VERSION ""

NS_ :

BS_:

BU_: EBOOST_HS CGM_HS BSM_HS HCP_B_HS AVM_HS PFAF_HS LVMPC_HS DCDC_HS TRCM_HS AMP_HS VICM2_HS FICM_HS ARS_HS MCP_B_HS MCP_A_HS ICCM_OBD_HS ACCM_HS VLBS_HS EBCM_OBD_HS HCP_T_HS EDI_HS HPCC_HS VITM_OBD_HS VICM_HS HCP_HS APPS_HS ICCM_HS EOCM_F_HS GPCM_HS VCM_HS HMIM_HS VES_HS Dummy_HS MCP_C_HS ONSTAR_HS EPS_HS TestTool_HS MCP_HS BCP_HS ALC_HS AHL_AFL_HS SADS_HS EPSB_HS FCM_HS TCCM_HS RDCM_HS PTO_HS EBCM_HS ACC_HS BCM_HS TCM_HS ECM_HS

BO_ 1904 DTC_Triggered_770: 7 ICCM_OBD_HS
 SG_ DTCI_WrnIndRqdSt_770 : 47|1@0+ (1,0) [0|1] ""  HMIM_HS,ONSTAR_HS
 SG_ DTCIUnused7_770 : 7|1@0+ (1,0) [0|1] ""  HMIM_HS,ONSTAR_HS
 SG_ DTCIUnused6_770 : 6|1@0+ (1,0) [0|1] ""  HMIM_HS,ONSTAR_HS
 SG_ DTCIUnused5_770 : 5|1@0+ (1,0) [0|1] ""  HMIM_HS,ONSTAR_HS
 SG_ DTCIUnused4_770 : 4|1@0+ (1,0) [0|1] ""  HMIM_HS,ONSTAR_HS
 SG_ DTCIUnused3_770 : 3|1@0+ (1,0) [0|1] ""  HMIM_HS,ONSTAR_HS
 SG_ DTCIUnused2_770 : 2|1@0+ (1,0) [0|1] ""  HMIM_HS,ONSTAR_HS
 SG_ DTCIUnused1_770 : 1|1@0+ (1,0) [0|1] ""  HMIM_HS,ONSTAR_HS
 SG_ DTCI_TstNPsdPwrUpSt_770 : 45|1@0+ (1,0) [0|1] ""  HMIM_HS,ONSTAR_HS
 SG_ DTCI_TstNPsdCdClrdSt_770 : 42|1@0+ (1,0) [0|1] ""  HMIM_HS,ONSTAR_HS
 SG_ DTCI_TstFldPwrUpSt_770 : 46|1@0+ (1,0) [0|1] ""  HMIM_HS,ONSTAR_HS
 SG_ DTCI_TstFldCdClrdStat_770 : 43|1@0+ (1,0) [0|1] ""  HMIM_HS,ONSTAR_HS
 SG_ DTCI_HistStat_770 : 44|1@0+ (1,0) [0|1] ""  HMIM_HS,ONSTAR_HS
 SG_ DTCI_DTCTriggered_770 : 0|1@0+ (1,0) [0|1] ""  HMIM_HS,ONSTAR_HS
 SG_ DTCI_DTCSource_770 : 15|8@0+ (1,0) [0|255] ""  HMIM_HS,ONSTAR_HS
 SG_ DTCI_DTCNumber_770 : 23|16@0+ (1,0) [0|65535] ""  HMIM_HS,ONSTAR_HS
 SG_ DTCI_DTCFaultType_770 : 55|8@0+ (1,0) [0|255] ""  HMIM_HS,ONSTAR_HS
 SG_ DTCI_DTCFailType_770 : 39|8@0+ (1,0) [0|255] ""  HMIM_HS,ONSTAR_HS
 SG_ DTCI_CurrentStatus_770 : 41|1@0+ (1,0) [0|1] ""  HMIM_HS,ONSTAR_HS
 SG_ DTCI_CodeSupported_770 : 40|1@0+ (1,0) [0|1] ""  HMIM_HS,ONSTAR_HS

BO_ 1908 DTC_Triggered_774: 7 DCDC_HS
 SG_ DTCI_DTCFaultType_774 : 55|8@0+ (1,0) [0|255] ""  HMIM_HS,ONSTAR_HS
 SG_ DTCI_CodeSupported_774 : 40|1@0+ (1,0) [0|1] ""  HMIM_HS,ONSTAR_HS
 SG_ DTCI_CurrentStatus_774 : 41|1@0+ (1,0) [0|1] ""  HMIM_HS,ONSTAR_HS
 SG_ DTCI_TstNPsdCdClrdSt_774 : 42|1@0+ (1,0) [0|1] ""  HMIM_HS,ONSTAR_HS
 SG_ DTCI_TstFldCdClrdStat_774 : 43|1@0+ (1,0) [0|1] ""  HMIM_HS,ONSTAR_HS
 SG_ DTCI_HistStat_774 : 44|1@0+ (1,0) [0|1] ""  HMIM_HS,ONSTAR_HS
 SG_ DTCI_TstNPsdPwrUpSt_774 : 45|1@0+ (1,0) [0|1] ""  HMIM_HS,ONSTAR_HS
 SG_ DTCI_TstFldPwrUpSt_774 : 46|1@0+ (1,0) [0|1] ""  HMIM_HS,ONSTAR_HS
 SG_ DTCI_WrnIndRqdSt_774 : 47|1@0+ (1,0) [0|1] ""  HMIM_HS,ONSTAR_HS
 SG_ DTCI_DTCFailType_774 : 39|8@0+ (1,0) [0|255] ""  HMIM_HS,ONSTAR_HS
 SG_ DTCI_DTCNumber_774 : 23|16@0+ (1,0) [0|65535] ""  HMIM_HS,ONSTAR_HS
 SG_ DTCI_DTCSource_774 : 15|8@0+ (1,0) [0|255] ""  HMIM_HS,ONSTAR_HS
 SG_ DTCI_DTCTriggered_774 : 0|1@0+ (1,0) [0|1] ""  HMIM_HS,ONSTAR_HS
 SG_ DTCIUnused7_774 : 1|1@0+ (1,0) [0|1] ""  HMIM_HS,ONSTAR_HS
 SG_ DTCIUnused6_774 : 2|1@0+ (1,0) [0|1] ""  HMIM_HS,ONSTAR_HS
 SG_ DTCIUnused5_774 : 3|1@0+ (1,0) [0|1] ""  HMIM_HS,ONSTAR_HS
 SG_ DTCIUnused4_774 : 4|1@0+ (1,0) [0|1] ""  HMIM_HS,ONSTAR_HS
 SG_ DTCIUnused3_774 : 5|1@0+ (1,0) [0|1] ""  HMIM_HS,ONSTAR_HS
 SG_ DTCIUnused2_774 : 6|1@0+ (1,0) [0|1] ""  HMIM_HS,ONSTAR_HS
 SG_ DTCIUnused1_774 : 7|1@0+ (1,0) [0|1] ""  HMIM_HS,ONSTAR_HS

BO_ 1909 DTC_Triggered_775: 7 MCP_HS
 SG_ DTCI_DTCFaultType_775 : 55|8@0+ (1,0) [0|255] ""  HMIM_HS,ONSTAR_HS
 SG_ DTCI_CodeSupported_775 : 40|1@0+ (1,0) [0|1] ""  HMIM_HS,ONSTAR_HS
 SG_ DTCI_CurrentStatus_775 : 41|1@0+ (1,0) [0|1] ""  HMIM_HS,ONSTAR_HS
 SG_ DTCI_TstNPsdCdClrdSt_775 : 42|1@0+ (1,0) [0|1] ""  HMIM_HS,ONSTAR_HS
 SG_ DTCI_TstFldCdClrdStat_775 : 43|1@0+ (1,0) [0|1] ""  HMIM_HS,ONSTAR_HS
 SG_ DTCI_HistStat_775 : 44|1@0+ (1,0) [0|1] ""  HMIM_HS,ONSTAR_HS
 SG_ DTCI_TstNPsdPwrUpSt_775 : 45|1@0+ (1,0) [0|1] ""  HMIM_HS,ONSTAR_HS
 SG_ DTCI_TstFldPwrUpSt_775 : 46|1@0+ (1,0) [0|1] ""  HMIM_HS,ONSTAR_HS
 SG_ DTCI_WrnIndRqdSt_775 : 47|1@0+ (1,0) [0|1] ""  HMIM_HS,ONSTAR_HS
 SG_ DTCI_DTCFailType_775 : 39|8@0+ (1,0) [0|255] ""  HMIM_HS,ONSTAR_HS
 SG_ DTCI_DTCNumber_775 : 23|16@0+ (1,0) [0|65535] ""  HMIM_HS,ONSTAR_HS
 SG_ DTCI_DTCSource_775 : 15|8@0+ (1,0) [0|255] ""  HMIM_HS,ONSTAR_HS
 SG_ DTCI_DTCTriggered_775 : 0|1@0+ (1,0) [0|1] ""  HMIM_HS,ONSTAR_HS
 SG_ DTCIUnused7_775 : 1|1@0+ (1,0) [0|1] ""  HMIM_HS,ONSTAR_HS
 SG_ DTCIUnused6_775 : 2|1@0+ (1,0) [0|1] ""  HMIM_HS,ONSTAR_HS
 SG_ DTCIUnused5_775 : 3|1@0+ (1,0) [0|1] ""  HMIM_HS,ONSTAR_HS
 SG_ DTCIUnused4_775 : 4|1@0+ (1,0) [0|1] ""  HMIM_HS,ONSTAR_HS
 SG_ DTCIUnused3_775 : 5|1@0+ (1,0) [0|1] ""  HMIM_HS,ONSTAR_HS
 SG_ DTCIUnused2_775 : 6|1@0+ (1,0) [0|1] ""  HMIM_HS,ONSTAR_HS
 SG_ DTCIUnused1_775 : 7|1@0+ (1,0) [0|1] ""  HMIM_HS,ONSTAR_HS

BO_ 1910 DTC_Triggered_776: 7 BCP_HS
 SG_ DTCI_DTCFaultType_776 : 55|8@0+ (1,0) [0|255] ""  HMIM_HS,ONSTAR_HS
 SG_ DTCI_CodeSupported_776 : 40|1@0+ (1,0) [0|1] ""  HMIM_HS,ONSTAR_HS
 SG_ DTCI_CurrentStatus_776 : 41|1@0+ (1,0) [0|1] ""  HMIM_HS,ONSTAR_HS
 SG_ DTCI_TstNPsdCdClrdSt_776 : 42|1@0+ (1,0) [0|1] ""  HMIM_HS,ONSTAR_HS
 SG_ DTCI_TstFldCdClrdStat_776 : 43|1@0+ (1,0) [0|1] ""  HMIM_HS,ONSTAR_HS
 SG_ DTCI_HistStat_776 : 44|1@0+ (1,0) [0|1] ""  HMIM_HS,ONSTAR_HS
 SG_ DTCI_TstNPsdPwrUpSt_776 : 45|1@0+ (1,0) [0|1] ""  HMIM_HS,ONSTAR_HS
 SG_ DTCI_TstFldPwrUpSt_776 : 46|1@0+ (1,0) [0|1] ""  HMIM_HS,ONSTAR_HS
 SG_ DTCI_WrnIndRqdSt_776 : 47|1@0+ (1,0) [0|1] ""  HMIM_HS,ONSTAR_HS
 SG_ DTCI_DTCFailType_776 : 39|8@0+ (1,0) [0|255] ""  HMIM_HS,ONSTAR_HS
 SG_ DTCI_DTCNumber_776 : 23|16@0+ (1,0) [0|65535] ""  HMIM_HS,ONSTAR_HS
 SG_ DTCI_DTCSource_776 : 15|8@0+ (1,0) [0|255] ""  HMIM_HS,ONSTAR_HS
 SG_ DTCI_DTCTriggered_776 : 0|1@0+ (1,0) [0|1] ""  HMIM_HS,ONSTAR_HS
 SG_ DTCIUnused7_776 : 1|1@0+ (1,0) [0|1] ""  HMIM_HS,ONSTAR_HS
 SG_ DTCIUnused6_776 : 2|1@0+ (1,0) [0|1] ""  HMIM_HS,ONSTAR_HS
 SG_ DTCIUnused5_776 : 3|1@0+ (1,0) [0|1] ""  HMIM_HS,ONSTAR_HS
 SG_ DTCIUnused4_776 : 4|1@0+ (1,0) [0|1] ""  HMIM_HS,ONSTAR_HS
 SG_ DTCIUnused3_776 : 5|1@0+ (1,0) [0|1] ""  HMIM_HS,ONSTAR_HS
 SG_ DTCIUnused2_776 : 6|1@0+ (1,0) [0|1] ""  HMIM_HS,ONSTAR_HS
 SG_ DTCIUnused1_776 : 7|1@0+ (1,0) [0|1] ""  HMIM_HS,ONSTAR_HS

BO_ 1912 DTC_Triggered_778: 7 EPS_HS
 SG_ DTCI_DTCFaultType_778 : 55|8@0+ (1,0) [0|255] ""  HMIM_HS,ONSTAR_HS
 SG_ DTCI_CodeSupported_778 : 40|1@0+ (1,0) [0|1] ""  HMIM_HS,ONSTAR_HS
 SG_ DTCI_CurrentStatus_778 : 41|1@0+ (1,0) [0|1] ""  HMIM_HS,ONSTAR_HS
 SG_ DTCI_TstNPsdCdClrdSt_778 : 42|1@0+ (1,0) [0|1] ""  HMIM_HS,ONSTAR_HS
 SG_ DTCI_TstFldCdClrdStat_778 : 43|1@0+ (1,0) [0|1] ""  HMIM_HS,ONSTAR_HS
 SG_ DTCI_HistStat_778 : 44|1@0+ (1,0) [0|1] ""  HMIM_HS,ONSTAR_HS
 SG_ DTCI_TstNPsdPwrUpSt_778 : 45|1@0+ (1,0) [0|1] ""  HMIM_HS,ONSTAR_HS
 SG_ DTCI_TstFldPwrUpSt_778 : 46|1@0+ (1,0) [0|1] ""  HMIM_HS,ONSTAR_HS
 SG_ DTCI_WrnIndRqdSt_778 : 47|1@0+ (1,0) [0|1] ""  HMIM_HS,ONSTAR_HS
 SG_ DTCI_DTCFailType_778 : 39|8@0+ (1,0) [0|255] ""  HMIM_HS,ONSTAR_HS
 SG_ DTCI_DTCNumber_778 : 23|16@0+ (1,0) [0|65535] ""  HMIM_HS,ONSTAR_HS
 SG_ DTCI_DTCSource_778 : 15|8@0+ (1,0) [0|255] ""  HMIM_HS,ONSTAR_HS
 SG_ DTCI_DTCTriggered_778 : 0|1@0+ (1,0) [0|1] ""  HMIM_HS,ONSTAR_HS
 SG_ DTCIUnused7_778 : 1|1@0+ (1,0) [0|1] ""  HMIM_HS,ONSTAR_HS
 SG_ DTCIUnused6_778 : 2|1@0+ (1,0) [0|1] ""  HMIM_HS,ONSTAR_HS
 SG_ DTCIUnused5_778 : 3|1@0+ (1,0) [0|1] ""  HMIM_HS,ONSTAR_HS
 SG_ DTCIUnused4_778 : 4|1@0+ (1,0) [0|1] ""  HMIM_HS,ONSTAR_HS
 SG_ DTCIUnused3_778 : 5|1@0+ (1,0) [0|1] ""  HMIM_HS,ONSTAR_HS
 SG_ DTCIUnused2_778 : 6|1@0+ (1,0) [0|1] ""  HMIM_HS,ONSTAR_HS
 SG_ DTCIUnused1_778 : 7|1@0+ (1,0) [0|1] ""  HMIM_HS,ONSTAR_HS

BO_ 1913 DTC_Triggered_779: 7 TRCM_HS
 SG_ DTCI_DTCFaultType_779 : 55|8@0+ (1,0) [0|255] ""  HMIM_HS,ONSTAR_HS
 SG_ DTCI_CodeSupported_779 : 40|1@0+ (1,0) [0|1] ""  HMIM_HS,ONSTAR_HS
 SG_ DTCI_CurrentStatus_779 : 41|1@0+ (1,0) [0|1] ""  HMIM_HS,ONSTAR_HS
 SG_ DTCI_TstNPsdCdClrdSt_779 : 42|1@0+ (1,0) [0|1] ""  HMIM_HS,ONSTAR_HS
 SG_ DTCI_TstFldCdClrdStat_779 : 43|1@0+ (1,0) [0|1] ""  HMIM_HS,ONSTAR_HS
 SG_ DTCI_HistStat_779 : 44|1@0+ (1,0) [0|1] ""  HMIM_HS,ONSTAR_HS
 SG_ DTCI_TstNPsdPwrUpSt_779 : 45|1@0+ (1,0) [0|1] ""  HMIM_HS,ONSTAR_HS
 SG_ DTCI_TstFldPwrUpSt_779 : 46|1@0+ (1,0) [0|1] ""  HMIM_HS,ONSTAR_HS
 SG_ DTCI_WrnIndRqdSt_779 : 47|1@0+ (1,0) [0|1] ""  HMIM_HS,ONSTAR_HS
 SG_ DTCI_DTCFailType_779 : 39|8@0+ (1,0) [0|255] ""  HMIM_HS,ONSTAR_HS
 SG_ DTCI_DTCNumber_779 : 23|16@0+ (1,0) [0|65535] ""  HMIM_HS,ONSTAR_HS
 SG_ DTCI_DTCSource_779 : 15|8@0+ (1,0) [0|255] ""  HMIM_HS,ONSTAR_HS
 SG_ DTCI_DTCTriggered_779 : 0|1@0+ (1,0) [0|1] ""  HMIM_HS,ONSTAR_HS
 SG_ DTCIUnused7_779 : 1|1@0+ (1,0) [0|1] ""  HMIM_HS,ONSTAR_HS
 SG_ DTCIUnused6_779 : 2|1@0+ (1,0) [0|1] ""  HMIM_HS,ONSTAR_HS
 SG_ DTCIUnused5_779 : 3|1@0+ (1,0) [0|1] ""  HMIM_HS,ONSTAR_HS
 SG_ DTCIUnused4_779 : 4|1@0+ (1,0) [0|1] ""  HMIM_HS,ONSTAR_HS
 SG_ DTCIUnused3_779 : 5|1@0+ (1,0) [0|1] ""  HMIM_HS,ONSTAR_HS
 SG_ DTCIUnused2_779 : 6|1@0+ (1,0) [0|1] ""  HMIM_HS,ONSTAR_HS
 SG_ DTCIUnused1_779 : 7|1@0+ (1,0) [0|1] ""  HMIM_HS,ONSTAR_HS

BO_ 1916 DTC_Triggered_77C: 7 CGM_HS
 SG_ DTCI_DTCFaultType_77C : 55|8@0+ (1,0) [0|255] ""  HMIM_HS,ONSTAR_HS
 SG_ DTCI_CodeSupported_77C : 40|1@0+ (1,0) [0|1] ""  HMIM_HS,ONSTAR_HS
 SG_ DTCI_CurrentStatus_77C : 41|1@0+ (1,0) [0|1] ""  HMIM_HS,ONSTAR_HS
 SG_ DTCI_TstNPsdCdClrdSt_77C : 42|1@0+ (1,0) [0|1] ""  HMIM_HS,ONSTAR_HS
 SG_ DTCI_TstFldCdClrdStat_77C : 43|1@0+ (1,0) [0|1] ""  HMIM_HS,ONSTAR_HS
 SG_ DTCI_HistStat_77C : 44|1@0+ (1,0) [0|1] ""  HMIM_HS,ONSTAR_HS
 SG_ DTCI_TstNPsdPwrUpSt_77C : 45|1@0+ (1,0) [0|1] ""  HMIM_HS,ONSTAR_HS
 SG_ DTCI_TstFldPwrUpSt_77C : 46|1@0+ (1,0) [0|1] ""  HMIM_HS,ONSTAR_HS
 SG_ DTCI_WrnIndRqdSt_77C : 47|1@0+ (1,0) [0|1] ""  HMIM_HS,ONSTAR_HS
 SG_ DTCI_DTCFailType_77C : 39|8@0+ (1,0) [0|255] ""  HMIM_HS,ONSTAR_HS
 SG_ DTCI_DTCNumber_77C : 23|16@0+ (1,0) [0|65535] ""  HMIM_HS,ONSTAR_HS
 SG_ DTCI_DTCSource_77C : 15|8@0+ (1,0) [0|255] ""  HMIM_HS,ONSTAR_HS
 SG_ DTCI_DTCTriggered_77C : 0|1@0+ (1,0) [0|1] ""  HMIM_HS,ONSTAR_HS
 SG_ DTCIUnused7_77C : 1|1@0+ (1,0) [0|1] ""  HMIM_HS,ONSTAR_HS
 SG_ DTCIUnused6_77C : 2|1@0+ (1,0) [0|1] ""  HMIM_HS,ONSTAR_HS
 SG_ DTCIUnused5_77C : 3|1@0+ (1,0) [0|1] ""  HMIM_HS,ONSTAR_HS
 SG_ DTCIUnused4_77C : 4|1@0+ (1,0) [0|1] ""  HMIM_HS,ONSTAR_HS
 SG_ DTCIUnused3_77C : 5|1@0+ (1,0) [0|1] ""  HMIM_HS,ONSTAR_HS
 SG_ DTCIUnused2_77C : 6|1@0+ (1,0) [0|1] ""  HMIM_HS,ONSTAR_HS
 SG_ DTCIUnused1_77C : 7|1@0+ (1,0) [0|1] ""  HMIM_HS,ONSTAR_HS

BO_ 1917 DTC_Triggered_77D: 7 CGM_HS
 SG_ DTCI_DTCFaultType_77D : 55|8@0+ (1,0) [0|255] ""  HMIM_HS,ONSTAR_HS
 SG_ DTCI_CodeSupported_77D : 40|1@0+ (1,0) [0|1] ""  HMIM_HS,ONSTAR_HS
 SG_ DTCI_CurrentStatus_77D : 41|1@0+ (1,0) [0|1] ""  HMIM_HS,ONSTAR_HS
 SG_ DTCI_TstNPsdCdClrdSt_77D : 42|1@0+ (1,0) [0|1] ""  HMIM_HS,ONSTAR_HS
 SG_ DTCI_TstFldCdClrdStat_77D : 43|1@0+ (1,0) [0|1] ""  HMIM_HS,ONSTAR_HS
 SG_ DTCI_HistStat_77D : 44|1@0+ (1,0) [0|1] ""  HMIM_HS,ONSTAR_HS
 SG_ DTCI_TstNPsdPwrUpSt_77D : 45|1@0+ (1,0) [0|1] ""  HMIM_HS,ONSTAR_HS
 SG_ DTCI_TstFldPwrUpSt_77D : 46|1@0+ (1,0) [0|1] ""  HMIM_HS,ONSTAR_HS
 SG_ DTCI_WrnIndRqdSt_77D : 47|1@0+ (1,0) [0|1] ""  HMIM_HS,ONSTAR_HS
 SG_ DTCI_DTCFailType_77D : 39|8@0+ (1,0) [0|255] ""  HMIM_HS,ONSTAR_HS
 SG_ DTCI_DTCNumber_77D : 23|16@0+ (1,0) [0|65535] ""  HMIM_HS,ONSTAR_HS
 SG_ DTCI_DTCSource_77D : 15|8@0+ (1,0) [0|255] ""  HMIM_HS,ONSTAR_HS
 SG_ DTCI_DTCTriggered_77D : 0|1@0+ (1,0) [0|1] ""  HMIM_HS,ONSTAR_HS
 SG_ DTCIUnused7_77D : 1|1@0+ (1,0) [0|1] ""  HMIM_HS,ONSTAR_HS
 SG_ DTCIUnused6_77D : 2|1@0+ (1,0) [0|1] ""  HMIM_HS,ONSTAR_HS
 SG_ DTCIUnused5_77D : 3|1@0+ (1,0) [0|1] ""  HMIM_HS,ONSTAR_HS
 SG_ DTCIUnused4_77D : 4|1@0+ (1,0) [0|1] ""  HMIM_HS,ONSTAR_HS
 SG_ DTCIUnused3_77D : 5|1@0+ (1,0) [0|1] ""  HMIM_HS,ONSTAR_HS
 SG_ DTCIUnused2_77D : 6|1@0+ (1,0) [0|1] ""  HMIM_HS,ONSTAR_HS
 SG_ DTCIUnused1_77D : 7|1@0+ (1,0) [0|1] ""  HMIM_HS,ONSTAR_HS

BO_ 1918 DTC_Triggered_77E: 7 SADS_HS
 SG_ DTCI_DTCFaultType_77E : 55|8@0+ (1,0) [0|255] ""  HMIM_HS,ONSTAR_HS
 SG_ DTCI_CodeSupported_77E : 40|1@0+ (1,0) [0|1] ""  HMIM_HS,ONSTAR_HS
 SG_ DTCI_CurrentStatus_77E : 41|1@0+ (1,0) [0|1] ""  HMIM_HS,ONSTAR_HS
 SG_ DTCI_TstNPsdCdClrdSt_77E : 42|1@0+ (1,0) [0|1] ""  HMIM_HS,ONSTAR_HS
 SG_ DTCI_TstFldCdClrdStat_77E : 43|1@0+ (1,0) [0|1] ""  HMIM_HS,ONSTAR_HS
 SG_ DTCI_HistStat_77E : 44|1@0+ (1,0) [0|1] ""  HMIM_HS,ONSTAR_HS
 SG_ DTCI_TstNPsdPwrUpSt_77E : 45|1@0+ (1,0) [0|1] ""  HMIM_HS,ONSTAR_HS
 SG_ DTCI_TstFldPwrUpSt_77E : 46|1@0+ (1,0) [0|1] ""  HMIM_HS,ONSTAR_HS
 SG_ DTCI_WrnIndRqdSt_77E : 47|1@0+ (1,0) [0|1] ""  HMIM_HS,ONSTAR_HS
 SG_ DTCI_DTCFailType_77E : 39|8@0+ (1,0) [0|255] ""  HMIM_HS,ONSTAR_HS
 SG_ DTCI_DTCNumber_77E : 23|16@0+ (1,0) [0|65535] ""  HMIM_HS,ONSTAR_HS
 SG_ DTCI_DTCSource_77E : 15|8@0+ (1,0) [0|255] ""  HMIM_HS,ONSTAR_HS
 SG_ DTCI_DTCTriggered_77E : 0|1@0+ (1,0) [0|1] ""  HMIM_HS,ONSTAR_HS
 SG_ DTCIUnused7_77E : 1|1@0+ (1,0) [0|1] ""  HMIM_HS,ONSTAR_HS
 SG_ DTCIUnused6_77E : 2|1@0+ (1,0) [0|1] ""  HMIM_HS,ONSTAR_HS
 SG_ DTCIUnused5_77E : 3|1@0+ (1,0) [0|1] ""  HMIM_HS,ONSTAR_HS
 SG_ DTCIUnused4_77E : 4|1@0+ (1,0) [0|1] ""  HMIM_HS,ONSTAR_HS
 SG_ DTCIUnused3_77E : 5|1@0+ (1,0) [0|1] ""  HMIM_HS,ONSTAR_HS
 SG_ DTCIUnused2_77E : 6|1@0+ (1,0) [0|1] ""  HMIM_HS,ONSTAR_HS
 SG_ DTCIUnused1_77E : 7|1@0+ (1,0) [0|1] ""  HMIM_HS,ONSTAR_HS

BO_ 1919 DTC_Triggered_77F: 7 TCM_HS
 SG_ DTCI_DTCFaultType_77F : 55|8@0+ (1,0) [0|255] ""  HMIM_HS,ONSTAR_HS
 SG_ DTCI_CodeSupported_77F : 40|1@0+ (1,0) [0|1] ""  HMIM_HS,ONSTAR_HS
 SG_ DTCI_CurrentStatus_77F : 41|1@0+ (1,0) [0|1] ""  HMIM_HS,ONSTAR_HS
 SG_ DTCI_TstNPsdCdClrdSt_77F : 42|1@0+ (1,0) [0|1] ""  HMIM_HS,ONSTAR_HS
 SG_ DTCI_TstFldCdClrdStat_77F : 43|1@0+ (1,0) [0|1] ""  HMIM_HS,ONSTAR_HS
 SG_ DTCI_HistStat_77F : 44|1@0+ (1,0) [0|1] ""  HMIM_HS,ONSTAR_HS
 SG_ DTCI_TstNPsdPwrUpSt_77F : 45|1@0+ (1,0) [0|1] ""  HMIM_HS,ONSTAR_HS
 SG_ DTCI_TstFldPwrUpSt_77F : 46|1@0+ (1,0) [0|1] ""  HMIM_HS,ONSTAR_HS
 SG_ DTCI_WrnIndRqdSt_77F : 47|1@0+ (1,0) [0|1] ""  HMIM_HS,ONSTAR_HS
 SG_ DTCI_DTCFailType_77F : 39|8@0+ (1,0) [0|255] ""  HMIM_HS,ONSTAR_HS
 SG_ DTCI_DTCNumber_77F : 23|16@0+ (1,0) [0|65535] ""  HMIM_HS,ONSTAR_HS
 SG_ DTCI_DTCSource_77F : 15|8@0+ (1,0) [0|255] ""  HMIM_HS,ONSTAR_HS
 SG_ DTCI_DTCTriggered_77F : 0|1@0+ (1,0) [0|1] ""  HMIM_HS,ONSTAR_HS
 SG_ DTCIUnused7_77F : 1|1@0+ (1,0) [0|1] ""  HMIM_HS,ONSTAR_HS
 SG_ DTCIUnused6_77F : 2|1@0+ (1,0) [0|1] ""  HMIM_HS,ONSTAR_HS
 SG_ DTCIUnused5_77F : 3|1@0+ (1,0) [0|1] ""  HMIM_HS,ONSTAR_HS
 SG_ DTCIUnused4_77F : 4|1@0+ (1,0) [0|1] ""  HMIM_HS,ONSTAR_HS
 SG_ DTCIUnused3_77F : 5|1@0+ (1,0) [0|1] ""  HMIM_HS,ONSTAR_HS
 SG_ DTCIUnused2_77F : 6|1@0+ (1,0) [0|1] ""  HMIM_HS,ONSTAR_HS
 SG_ DTCIUnused1_77F : 7|1@0+ (1,0) [0|1] ""  HMIM_HS,ONSTAR_HS

BO_ 589 USDT_Req_to_ONS_HS: 8 TestTool_HS
 SG_ DgnInf : 7|64@0+ (1,0) [0|1.84467440737096E+019] ""  CGM_HS,ONSTAR_HS

BO_ 1357 UUDT_Resp_From_ONS_HS: 8 ONSTAR_HS
 SG_ DgnInf_HS54D : 7|64@0+ (1,0) [0|1.84467440737096E+019] ""  TestTool_HS

BO_ 1613 USDT_Resp_From_ONS_HS: 8 ONSTAR_HS
 SG_ DgnInf : 7|64@0+ (1,0) [0|1.84467440737096E+019] ""  TestTool_HS

BO_ 1606 USDT_Resp_From_APPS_HS: 8 APPS_HS
 SG_ DgnInf : 7|64@0+ (1,0) [0|1.84467440737096E+019] ""  CGM_HS,ONSTAR_HS,TestTool_HS

BO_ 582 USDT_Req_to_APPS_HS: 8 TestTool_HS
 SG_ DgnInf : 7|64@0+ (1,0) [0|1.84467440737096E+019] ""  CGM_HS,APPS_HS

BO_ 590 USDT_Req_to_SADS_HS: 8 TestTool_HS
 SG_ DgnInf : 7|64@0+ (1,0) [0|1.84467440737096E+019] ""  SADS_HS

BO_ 601 USDT_Req_to_MCP_C_HS: 8 TestTool_HS
 SG_ DgnInf : 7|64@0+ (1,0) [0|1.84467440737096E+019] ""  MCP_C_HS

BO_ 1369 UUDT_Resp_From_MCP_C_HS: 8 MCP_C_HS
 SG_ DgnInf_HS559 : 7|64@0+ (1,0) [0|1.84467440737096E+019] ""  CGM_HS,ONSTAR_HS,TestTool_HS

BO_ 1625 USDT_Resp_From_MCP_C_HS: 8 MCP_C_HS
 SG_ DgnInf : 7|64@0+ (1,0) [0|1.84467440737096E+019] ""  CGM_HS,ONSTAR_HS,TestTool_HS

BO_ 1356 UUDT_Resp_From_PFAF_HS: 8 PFAF_HS
 SG_ DgnInf_HS54C : 7|64@0+ (1,0) [0|1.84467440737096E+019] ""  CGM_HS,ONSTAR_HS,TestTool_HS

BO_ 1358 UUDT_Resp_From_SADS_HS: 8 SADS_HS
 SG_ DgnInf_HS54E : 7|64@0+ (1,0) [0|1.84467440737096E+019] ""  CGM_HS,ONSTAR_HS,TestTool_HS

BO_ 1359 UUDT_Resp_From_RDCM_HS: 8 RDCM_HS
 SG_ DgnInf_HS54F : 7|64@0+ (1,0) [0|1.84467440737096E+019] ""  CGM_HS,ONSTAR_HS,TestTool_HS

BO_ 2023 USDT_Req_to_VITM_HS: 8 TestTool_HS
 SG_ DgnInf : 7|64@0+ (1,0) [0|1.84467440737096E+019] ""  VITM_OBD_HS

BO_ 2021 USDT_Req_to_OBD_Device5: 8 CGM_HS
 SG_ DgnInf : 7|64@0+ (1,0) [0|1.84467440737096E+019] ""  EBCM_OBD_HS

BO_ 2017 USDT_Req_to_BCP_HS: 8 TestTool_HS
 SG_ DgnInf : 7|64@0+ (1,0) [0|1.84467440737096E+019] ""  HCP_B_HS,HCP_T_HS,HCP_HS,BCP_HS

BO_ 2019 USDT_Req_to_ICCM_OBD_HS: 8 TestTool_HS
 SG_ DgnInf : 7|64@0+ (1,0) [0|1.84467440737096E+019] ""  ICCM_OBD_HS,ICCM_HS

BO_ 585 USDT_Req_to_AFL_AHL_HS: 8 TestTool_HS
 SG_ DgnInf : 7|64@0+ (1,0) [0|1.84467440737096E+019] ""  CGM_HS,AHL_AFL_HS

BO_ 578 USDT_Req_to_EHPS_EPS_HS: 8 TestTool_HS
 SG_ DgnInf : 7|64@0+ (1,0) [0|1.84467440737096E+019] ""  VES_HS,EPS_HS

BO_ 2022 USDT_Req_to_OBD_Device6: 8 CGM_HS
 SG_ DgnInf : 7|64@0+ (1,0) [0|1.84467440737096E+019] ""  EBOOST_HS,FICM_HS,GPCM_HS,VICM2_HS

BO_ 584 USDT_Req_to_Free_48_HS: 8 CGM_HS
 SG_ DgnInf : 7|64@0+ (1,0) [0|1.84467440737096E+019] ""  Dummy_HS

BO_ 591 USDT_Req_to_RDCM_HS: 8 TestTool_HS
 SG_ DgnInf : 7|64@0+ (1,0) [0|1.84467440737096E+019] ""  RDCM_HS

BO_ 581 USDT_Req_to_ALC_HS: 8 TestTool_HS
 SG_ DgnInf : 7|64@0+ (1,0) [0|1.84467440737096E+019] ""  ALC_HS

BO_ 586 USDT_Req_to_SAS_HS: 8 TestTool_HS
 SG_ DgnInf : 7|64@0+ (1,0) [0|1.84467440737096E+019] "" Vector__XXX

BO_ 588 USDT_Req_to_PFAF_HS: 8 TestTool_HS
 SG_ DgnInf : 7|64@0+ (1,0) [0|1.84467440737096E+019] ""  CGM_HS,PFAF_HS

BO_ 580 USDT_Req_to_OBCM_HS: 8 TestTool_HS
 SG_ DgnInf : 7|64@0+ (1,0) [0|1.84467440737096E+019] ""  DCDC_HS

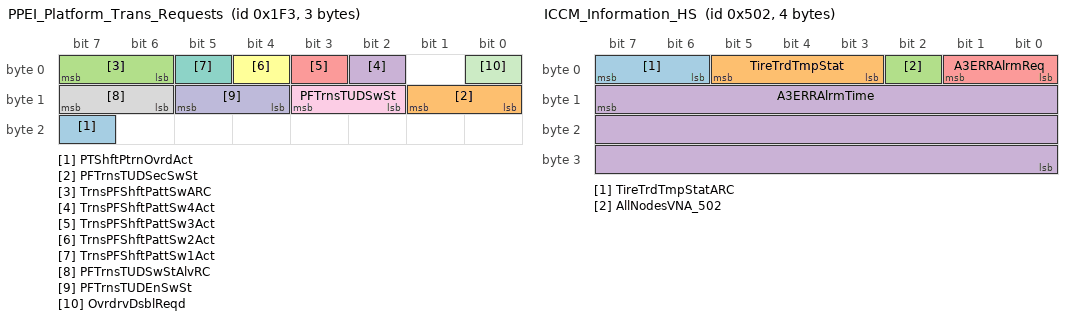
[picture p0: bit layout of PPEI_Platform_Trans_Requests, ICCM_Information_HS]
BO_ 499 PPEI_Platform_Trans_Requests: 3 BCM_HS
 SG_ PTShftPtrnOvrdAct : 23|1@0+ (1,0) [0|1] ""  TCM_HS
 SG_ PFTrnsTUDSecSwSt : 9|2@0+ (1,0) [0|3] ""  HCP_T_HS,TCM_HS
 SG_ TrnsPFShftPattSwARC : 7|2@0+ (1,0) [0|3] ""  HCP_T_HS,ECM_HS,TCM_HS
 SG_ TrnsPFShftPattSw4Act : 2|1@0+ (1,0) [0|1] ""  HCP_T_HS,ECM_HS,TCM_HS
 SG_ TrnsPFShftPattSw3Act : 3|1@0+ (1,0) [0|1] ""  HCP_T_HS,ECM_HS,TCM_HS
 SG_ TrnsPFShftPattSw2Act : 4|1@0+ (1,0) [0|1] ""  HCP_T_HS,ECM_HS,TCM_HS
 SG_ TrnsPFShftPattSw1Act : 5|1@0+ (1,0) [0|1] ""  HCP_T_HS,ECM_HS,TCM_HS
 SG_ PFTrnsTUDSwStAlvRC : 15|2@0+ (1,0) [0|3] ""  HCP_T_HS,TCM_HS
 SG_ PFTrnsTUDSwSt : 11|2@0+ (1,0) [0|3] ""  HCP_T_HS,TCM_HS
 SG_ PFTrnsTUDEnSwSt : 13|2@0+ (1,0) [0|3] ""  HCP_T_HS,TCM_HS
 SG_ OvrdrvDsblReqd : 0|1@0+ (1,0) [0|1] "" Vector__XXX

BO_ 1282 ICCM_Information_HS: 4 ALC_HS
 SG_ TireTrdTmpStatARC : 7|2@0+ (1,0) [0|3] ""  EBCM_OBD_HS,EBCM_HS
 SG_ TireTrdTmpStat : 5|3@0+ (1,0) [0|7] ""  BCM_HS,EBCM_OBD_HS,EBCM_HS
 SG_ AllNodesVNA_502 : 2|1@0+ (1,0) [0|1] ""  BCM_HS
 SG_ A3ERRAlrmTime : 15|24@0+ (1,0) [0|16777215] "min"  BCM_HS
 SG_ A3ERRAlrmReq : 1|2@0+ (1,0) [0|3] ""  BCM_HS

BO_ 1360 UUDT_Resp_From_AVM_HS: 8 AVM_HS
 SG_ DgnInf_HS550 : 7|64@0+ (1,0) [0|1.84467440737096E+019] ""  CGM_HS,ONSTAR_HS,TestTool_HS

BO_ 1616 USDT_Resp_From_AVM_HS: 8 AVM_HS
 SG_ DgnInf : 7|64@0+ (1,0) [0|1.84467440737096E+019] ""  CGM_HS,ONSTAR_HS,TestTool_HS

BO_ 1921 DTC_Triggered_781: 7 APPS_HS
 SG_ DTCI_CurrentStatus_781 : 41|1@0+ (1,0) [0|1] ""  HMIM_HS,ONSTAR_HS
 SG_ DTCI_WrnIndRqdSt_781 : 47|1@0+ (1,0) [0|1] ""  HMIM_HS,ONSTAR_HS
 SG_ DTCIUnused7_781 : 1|1@0+ (1,0) [0|1] ""  HMIM_HS,ONSTAR_HS
 SG_ DTCIUnused6_781 : 2|1@0+ (1,0) [0|1] ""  HMIM_HS,ONSTAR_HS
 SG_ DTCIUnused5_781 : 3|1@0+ (1,0) [0|1] ""  HMIM_HS,ONSTAR_HS
 SG_ DTCIUnused4_781 : 4|1@0+ (1,0) [0|1] ""  HMIM_HS,ONSTAR_HS
 SG_ DTCIUnused3_781 : 5|1@0+ (1,0) [0|1] ""  HMIM_HS,ONSTAR_HS
 SG_ DTCIUnused2_781 : 6|1@0+ (1,0) [0|1] ""  HMIM_HS,ONSTAR_HS
 SG_ DTCIUnused1_781 : 7|1@0+ (1,0) [0|1] ""  HMIM_HS,ONSTAR_HS
 SG_ DTCI_TstNPsdPwrUpSt_781 : 45|1@0+ (1,0) [0|1] ""  HMIM_HS,ONSTAR_HS
 SG_ DTCI_TstNPsdCdClrdSt_781 : 42|1@0+ (1,0) [0|1] ""  HMIM_HS,ONSTAR_HS
 SG_ DTCI_TstFldPwrUpSt_781 : 46|1@0+ (1,0) [0|1] ""  HMIM_HS,ONSTAR_HS
 SG_ DTCI_TstFldCdClrdStat_781 : 43|1@0+ (1,0) [0|1] ""  HMIM_HS,ONSTAR_HS
 SG_ DTCI_HistStat_781 : 44|1@0+ (1,0) [0|1] ""  HMIM_HS,ONSTAR_HS
 SG_ DTCI_DTCTriggered_781 : 0|1@0+ (1,0) [0|1] ""  HMIM_HS,ONSTAR_HS
 SG_ DTCI_DTCSource_781 : 15|8@0+ (1,0) [0|255] ""  HMIM_HS,ONSTAR_HS
 SG_ DTCI_DTCNumber_781 : 23|16@0+ (1,0) [0|65535] ""  HMIM_HS,ONSTAR_HS
 SG_ DTCI_DTCFaultType_781 : 55|8@0+ (1,0) [0|255] ""  HMIM_HS,ONSTAR_HS
 SG_ DTCI_DTCFailType_781 : 39|8@0+ (1,0) [0|255] ""  HMIM_HS,ONSTAR_HS
 SG_ DTCI_CodeSupported_781 : 40|1@0+ (1,0) [0|1] ""  HMIM_HS,ONSTAR_HS

BO_ 1920 DTC_Triggered_780: 7 EBCM_HS
 SG_ DTCI_CurrentStatus_780 : 41|1@0+ (1,0) [0|1] ""  HMIM_HS,ONSTAR_HS
 SG_ DTCI_WrnIndRqdSt_780 : 47|1@0+ (1,0) [0|1] ""  HMIM_HS,ONSTAR_HS
 SG_ DTCIUnused7_780 : 1|1@0+ (1,0) [0|1] ""  HMIM_HS,ONSTAR_HS
 SG_ DTCIUnused6_780 : 2|1@0+ (1,0) [0|1] ""  HMIM_HS,ONSTAR_HS
 SG_ DTCIUnused5_780 : 3|1@0+ (1,0) [0|1] ""  HMIM_HS,ONSTAR_HS
 SG_ DTCIUnused4_780 : 4|1@0+ (1,0) [0|1] ""  HMIM_HS,ONSTAR_HS
 SG_ DTCIUnused3_780 : 5|1@0+ (1,0) [0|1] ""  HMIM_HS,ONSTAR_HS
 SG_ DTCIUnused2_780 : 6|1@0+ (1,0) [0|1] ""  HMIM_HS,ONSTAR_HS
 SG_ DTCIUnused1_780 : 7|1@0+ (1,0) [0|1] ""  HMIM_HS,ONSTAR_HS
 SG_ DTCI_TstNPsdPwrUpSt_780 : 45|1@0+ (1,0) [0|1] ""  HMIM_HS,ONSTAR_HS
 SG_ DTCI_TstNPsdCdClrdSt_780 : 42|1@0+ (1,0) [0|1] ""  HMIM_HS,ONSTAR_HS
 SG_ DTCI_TstFldPwrUpSt_780 : 46|1@0+ (1,0) [0|1] ""  HMIM_HS,ONSTAR_HS
 SG_ DTCI_TstFldCdClrdStat_780 : 43|1@0+ (1,0) [0|1] ""  HMIM_HS,ONSTAR_HS
 SG_ DTCI_HistStat_780 : 44|1@0+ (1,0) [0|1] ""  HMIM_HS,ONSTAR_HS
 SG_ DTCI_DTCTriggered_780 : 0|1@0+ (1,0) [0|1] ""  HMIM_HS,ONSTAR_HS
 SG_ DTCI_DTCSource_780 : 15|8@0+ (1,0) [0|255] ""  HMIM_HS,ONSTAR_HS
 SG_ DTCI_DTCNumber_780 : 23|16@0+ (1,0) [0|65535] ""  HMIM_HS,ONSTAR_HS
 SG_ DTCI_DTCFaultType_780 : 55|8@0+ (1,0) [0|255] ""  HMIM_HS,ONSTAR_HS
 SG_ DTCI_DTCFailType_780 : 39|8@0+ (1,0) [0|255] ""  HMIM_HS,ONSTAR_HS
 SG_ DTCI_CodeSupported_780 : 40|1@0+ (1,0) [0|1] ""  HMIM_HS,ONSTAR_HS

BO_ 596 USDT_Req_to_EPB_HS: 8 TestTool_HS
 SG_ DgnInf : 7|64@0+ (1,0) [0|1.84467440737096E+019] ""  CGM_HS,EPSB_HS

BO_ 2033 PCU_Req_to_SDM_HS: 8 TestTool_HS
 SG_ PCUInfo : 7|64@0+ (1,0) [0|1.84467440737096E+019] ""  BCM_HS

BO_ 495 PPEI_Fuel_System_Request_2: 4 ECM_HS
 SG_ MassAirFloV : 7|1@0+ (1,0) [0|1] ""  BSM_HS,VICM_HS
 SG_ MassAirFlo : 23|16@0+ (0.01,0) [0|655.35] "grams/s"  BSM_HS,VICM_HS

BO_ 1350 UUDT_Resp_From_APPS_HS: 8 APPS_HS
 SG_ DgnInf_HS546 : 7|64@0+ (1,0) [0|1.84467440737096E+019] ""  CGM_HS,ONSTAR_HS,TestTool_HS

BO_ 1914 DTC_Triggered_77A: 7 RDCM_HS
 SG_ DTCI_DTCFaultType_77A : 55|8@0+ (1,0) [0|255] ""  HMIM_HS,ONSTAR_HS
 SG_ DTCI_CodeSupported_77A : 40|1@0+ (1,0) [0|1] ""  HMIM_HS,ONSTAR_HS
 SG_ DTCI_CurrentStatus_77A : 41|1@0+ (1,0) [0|1] ""  HMIM_HS,ONSTAR_HS
 SG_ DTCI_TstNPsdCdClrdSt_77A : 42|1@0+ (1,0) [0|1] ""  HMIM_HS,ONSTAR_HS
 SG_ DTCI_TstFldCdClrdStat_77A : 43|1@0+ (1,0) [0|1] ""  HMIM_HS,ONSTAR_HS
 SG_ DTCI_HistStat_77A : 44|1@0+ (1,0) [0|1] ""  HMIM_HS,ONSTAR_HS
 SG_ DTCI_TstNPsdPwrUpSt_77A : 45|1@0+ (1,0) [0|1] ""  HMIM_HS,ONSTAR_HS
 SG_ DTCI_TstFldPwrUpSt_77A : 46|1@0+ (1,0) [0|1] ""  HMIM_HS,ONSTAR_HS
 SG_ DTCI_WrnIndRqdSt_77A : 47|1@0+ (1,0) [0|1] ""  HMIM_HS,ONSTAR_HS
 SG_ DTCI_DTCFailType_77A : 39|8@0+ (1,0) [0|255] ""  HMIM_HS,ONSTAR_HS
 SG_ DTCI_DTCNumber_77A : 23|16@0+ (1,0) [0|65535] ""  HMIM_HS,ONSTAR_HS
 SG_ DTCI_DTCSource_77A : 15|8@0+ (1,0) [0|255] ""  HMIM_HS,ONSTAR_HS
 SG_ DTCI_DTCTriggered_77A : 0|1@0+ (1,0) [0|1] ""  HMIM_HS,ONSTAR_HS
 SG_ DTCIUnused7_77A : 1|1@0+ (1,0) [0|1] ""  HMIM_HS,ONSTAR_HS
 SG_ DTCIUnused6_77A : 2|1@0+ (1,0) [0|1] ""  HMIM_HS,ONSTAR_HS
 SG_ DTCIUnused5_77A : 3|1@0+ (1,0) [0|1] ""  HMIM_HS,ONSTAR_HS
 SG_ DTCIUnused4_77A : 4|1@0+ (1,0) [0|1] ""  HMIM_HS,ONSTAR_HS
 SG_ DTCIUnused3_77A : 5|1@0+ (1,0) [0|1] ""  HMIM_HS,ONSTAR_HS
 SG_ DTCIUnused2_77A : 6|1@0+ (1,0) [0|1] ""  HMIM_HS,ONSTAR_HS
 SG_ DTCIUnused1_77A : 7|1@0+ (1,0) [0|1] ""  HMIM_HS,ONSTAR_HS

BO_ 1911 DTC_Triggered_777: 7 PTO_HS
 SG_ DTCI_DTCFaultType_777 : 55|8@0+ (1,0) [0|255] ""  HMIM_HS,ONSTAR_HS
 SG_ DTCI_CodeSupported_777 : 40|1@0+ (1,0) [0|1] ""  HMIM_HS,ONSTAR_HS
 SG_ DTCI_CurrentStatus_777 : 41|1@0+ (1,0) [0|1] ""  HMIM_HS,ONSTAR_HS
 SG_ DTCI_TstNPsdCdClrdSt_777 : 42|1@0+ (1,0) [0|1] ""  HMIM_HS,ONSTAR_HS
 SG_ DTCI_TstFldCdClrdStat_777 : 43|1@0+ (1,0) [0|1] ""  HMIM_HS,ONSTAR_HS
 SG_ DTCI_HistStat_777 : 44|1@0+ (1,0) [0|1] ""  HMIM_HS,ONSTAR_HS
 SG_ DTCI_TstNPsdPwrUpSt_777 : 45|1@0+ (1,0) [0|1] ""  HMIM_HS,ONSTAR_HS
 SG_ DTCI_TstFldPwrUpSt_777 : 46|1@0+ (1,0) [0|1] ""  HMIM_HS,ONSTAR_HS
 SG_ DTCI_WrnIndRqdSt_777 : 47|1@0+ (1,0) [0|1] ""  HMIM_HS,ONSTAR_HS
 SG_ DTCI_DTCFailType_777 : 39|8@0+ (1,0) [0|255] ""  HMIM_HS,ONSTAR_HS
 SG_ DTCI_DTCNumber_777 : 23|16@0+ (1,0) [0|65535] ""  HMIM_HS,ONSTAR_HS
 SG_ DTCI_DTCSource_777 : 15|8@0+ (1,0) [0|255] ""  HMIM_HS,ONSTAR_HS
 SG_ DTCI_DTCTriggered_777 : 0|1@0+ (1,0) [0|1] ""  HMIM_HS,ONSTAR_HS
 SG_ DTCIUnused7_777 : 1|1@0+ (1,0) [0|1] ""  HMIM_HS,ONSTAR_HS
 SG_ DTCIUnused6_777 : 2|1@0+ (1,0) [0|1] ""  HMIM_HS,ONSTAR_HS
 SG_ DTCIUnused5_777 : 3|1@0+ (1,0) [0|1] ""  HMIM_HS,ONSTAR_HS
 SG_ DTCIUnused4_777 : 4|1@0+ (1,0) [0|1] ""  HMIM_HS,ONSTAR_HS
 SG_ DTCIUnused3_777 : 5|1@0+ (1,0) [0|1] ""  HMIM_HS,ONSTAR_HS
 SG_ DTCIUnused2_777 : 6|1@0+ (1,0) [0|1] ""  HMIM_HS,ONSTAR_HS
 SG_ DTCIUnused1_777 : 7|1@0+ (1,0) [0|1] ""  HMIM_HS,ONSTAR_HS

BO_ 583 USDT_Req_to_PTO_HS: 8 TestTool_HS
 SG_ DgnInf : 7|64@0+ (1,0) [0|1.84467440737096E+019] ""  PTO_HS

BO_ 1351 UUDT_Resp_From_PTO: 8 PTO_HS
 SG_ DgnInf_HS547 : 7|64@0+ (1,0) [0|1.84467440737096E+019] ""  CGM_HS,ONSTAR_HS,TestTool_HS

BO_ 1607 USDT_Resp_From_PTO_HS: 8 PTO_HS
 SG_ DgnInf : 7|64@0+ (1,0) [0|1.84467440737096E+019] ""  CGM_HS,ONSTAR_HS,TestTool_HS

BO_ 1906 DTC_Triggered_772: 7 ECM_HS
 SG_ DTCI_DTCFaultType_772 : 55|8@0+ (1,0) [0|255] ""  HMIM_HS,ONSTAR_HS
 SG_ DTCI_CodeSupported_772 : 40|1@0+ (1,0) [0|1] ""  HMIM_HS,ONSTAR_HS
 SG_ DTCI_CurrentStatus_772 : 41|1@0+ (1,0) [0|1] ""  HMIM_HS,ONSTAR_HS
 SG_ DTCI_TstNPsdCdClrdSt_772 : 42|1@0+ (1,0) [0|1] ""  HMIM_HS,ONSTAR_HS
 SG_ DTCI_TstFldCdClrdStat_772 : 43|1@0+ (1,0) [0|1] ""  HMIM_HS,ONSTAR_HS
 SG_ DTCI_HistStat_772 : 44|1@0+ (1,0) [0|1] ""  HMIM_HS,ONSTAR_HS
 SG_ DTCI_TstNPsdPwrUpSt_772 : 45|1@0+ (1,0) [0|1] ""  HMIM_HS,ONSTAR_HS
 SG_ DTCI_TstFldPwrUpSt_772 : 46|1@0+ (1,0) [0|1] ""  HMIM_HS,ONSTAR_HS
 SG_ DTCI_WrnIndRqdSt_772 : 47|1@0+ (1,0) [0|1] ""  HMIM_HS,ONSTAR_HS
 SG_ DTCI_DTCFailType_772 : 39|8@0+ (1,0) [0|255] ""  HMIM_HS,ONSTAR_HS
 SG_ DTCI_DTCNumber_772 : 23|16@0+ (1,0) [0|65535] ""  HMIM_HS,ONSTAR_HS
 SG_ DTCI_DTCSource_772 : 15|8@0+ (1,0) [0|255] ""  HMIM_HS,ONSTAR_HS
 SG_ DTCI_DTCTriggered_772 : 0|1@0+ (1,0) [0|1] ""  HMIM_HS,ONSTAR_HS
 SG_ DTCIUnused7_772 : 1|1@0+ (1,0) [0|1] ""  HMIM_HS,ONSTAR_HS
 SG_ DTCIUnused6_772 : 2|1@0+ (1,0) [0|1] ""  HMIM_HS,ONSTAR_HS
 SG_ DTCIUnused5_772 : 3|1@0+ (1,0) [0|1] ""  HMIM_HS,ONSTAR_HS
 SG_ DTCIUnused4_772 : 4|1@0+ (1,0) [0|1] ""  HMIM_HS,ONSTAR_HS
 SG_ DTCIUnused3_772 : 5|1@0+ (1,0) [0|1] ""  HMIM_HS,ONSTAR_HS
 SG_ DTCIUnused2_772 : 6|1@0+ (1,0) [0|1] ""  HMIM_HS,ONSTAR_HS
 SG_ DTCIUnused1_772 : 7|1@0+ (1,0) [0|1] ""  HMIM_HS,ONSTAR_HS

BO_ 1907 DTC_Triggered_773: 7 EBCM_HS
 SG_ DTCI_DTCFaultType_773 : 55|8@0+ (1,0) [0|255] ""  HMIM_HS,ONSTAR_HS
 SG_ DTCI_CodeSupported_773 : 40|1@0+ (1,0) [0|1] ""  HMIM_HS,ONSTAR_HS
 SG_ DTCI_CurrentStatus_773 : 41|1@0+ (1,0) [0|1] ""  HMIM_HS,ONSTAR_HS
 SG_ DTCI_TstNPsdCdClrdSt_773 : 42|1@0+ (1,0) [0|1] ""  HMIM_HS,ONSTAR_HS
 SG_ DTCI_TstFldCdClrdStat_773 : 43|1@0+ (1,0) [0|1] ""  HMIM_HS,ONSTAR_HS
 SG_ DTCI_HistStat_773 : 44|1@0+ (1,0) [0|1] ""  HMIM_HS,ONSTAR_HS
 SG_ DTCI_TstNPsdPwrUpSt_773 : 45|1@0+ (1,0) [0|1] ""  HMIM_HS,ONSTAR_HS
 SG_ DTCI_TstFldPwrUpSt_773 : 46|1@0+ (1,0) [0|1] ""  HMIM_HS,ONSTAR_HS
 SG_ DTCI_WrnIndRqdSt_773 : 47|1@0+ (1,0) [0|1] ""  HMIM_HS,ONSTAR_HS
 SG_ DTCI_DTCFailType_773 : 39|8@0+ (1,0) [0|255] ""  HMIM_HS,ONSTAR_HS
 SG_ DTCI_DTCNumber_773 : 23|16@0+ (1,0) [0|65535] ""  HMIM_HS,ONSTAR_HS
 SG_ DTCI_DTCSource_773 : 15|8@0+ (1,0) [0|255] ""  HMIM_HS,ONSTAR_HS
 SG_ DTCI_DTCTriggered_773 : 0|1@0+ (1,0) [0|1] ""  HMIM_HS,ONSTAR_HS
 SG_ DTCIUnused7_773 : 1|1@0+ (1,0) [0|1] ""  HMIM_HS,ONSTAR_HS
 SG_ DTCIUnused6_773 : 2|1@0+ (1,0) [0|1] ""  HMIM_HS,ONSTAR_HS
 SG_ DTCIUnused5_773 : 3|1@0+ (1,0) [0|1] ""  HMIM_HS,ONSTAR_HS
 SG_ DTCIUnused4_773 : 4|1@0+ (1,0) [0|1] ""  HMIM_HS,ONSTAR_HS
 SG_ DTCIUnused3_773 : 5|1@0+ (1,0) [0|1] ""  HMIM_HS,ONSTAR_HS
 SG_ DTCIUnused2_773 : 6|1@0+ (1,0) [0|1] ""  HMIM_HS,ONSTAR_HS
 SG_ DTCIUnused1_773 : 7|1@0+ (1,0) [0|1] ""  HMIM_HS,ONSTAR_HS

BO_ 579 USDT_Req_to_EBCM_HPCC_HS: 8 TestTool_HS
 SG_ DgnInf : 7|64@0+ (1,0) [0|1.84467440737096E+019] ""  HPCC_HS,EBCM_HS

BO_ 1603 USDT_Resp_From_EBCM_HPCC_HS: 8 EBCM_HS
 SG_ DgnInf : 7|64@0+ (1,0) [0|1.84467440737096E+019] ""  CGM_HS,ONSTAR_HS,TestTool_HS

BO_ 1347 UUDT_Resp_From_EBCM_HPCC_HS: 8 EBCM_HS
 SG_ DgnInf_HS543 : 7|64@0+ (1,0) [0|1.84467440737096E+019] ""  CGM_HS,ONSTAR_HS,TestTool_HS

BO_ 1915 DTC_Triggered_77B: 7 ACC_HS
 SG_ DTCI_DTCFaultType_77B : 55|8@0+ (1,0) [0|255] ""  HMIM_HS,ONSTAR_HS
 SG_ DTCI_CodeSupported_77B : 40|1@0+ (1,0) [0|1] ""  HMIM_HS,ONSTAR_HS
 SG_ DTCI_CurrentStatus_77B : 41|1@0+ (1,0) [0|1] ""  HMIM_HS,ONSTAR_HS
 SG_ DTCI_TstNPsdCdClrdSt_77B : 42|1@0+ (1,0) [0|1] ""  HMIM_HS,ONSTAR_HS
 SG_ DTCI_TstFldCdClrdStat_77B : 43|1@0+ (1,0) [0|1] ""  HMIM_HS,ONSTAR_HS
 SG_ DTCI_HistStat_77B : 44|1@0+ (1,0) [0|1] ""  HMIM_HS,ONSTAR_HS
 SG_ DTCI_TstNPsdPwrUpSt_77B : 45|1@0+ (1,0) [0|1] ""  HMIM_HS,ONSTAR_HS
 SG_ DTCI_TstFldPwrUpSt_77B : 46|1@0+ (1,0) [0|1] ""  HMIM_HS,ONSTAR_HS
 SG_ DTCI_WrnIndRqdSt_77B : 47|1@0+ (1,0) [0|1] ""  HMIM_HS,ONSTAR_HS
 SG_ DTCI_DTCFailType_77B : 39|8@0+ (1,0) [0|255] ""  HMIM_HS,ONSTAR_HS
 SG_ DTCI_DTCNumber_77B : 23|16@0+ (1,0) [0|65535] ""  HMIM_HS,ONSTAR_HS
 SG_ DTCI_DTCSource_77B : 15|8@0+ (1,0) [0|255] ""  HMIM_HS,ONSTAR_HS
 SG_ DTCI_DTCTriggered_77B : 0|1@0+ (1,0) [0|1] ""  HMIM_HS,ONSTAR_HS
 SG_ DTCIUnused7_77B : 1|1@0+ (1,0) [0|1] ""  HMIM_HS,ONSTAR_HS
 SG_ DTCIUnused6_77B : 2|1@0+ (1,0) [0|1] ""  HMIM_HS,ONSTAR_HS
 SG_ DTCIUnused5_77B : 3|1@0+ (1,0) [0|1] ""  HMIM_HS,ONSTAR_HS
 SG_ DTCIUnused4_77B : 4|1@0+ (1,0) [0|1] ""  HMIM_HS,ONSTAR_HS
 SG_ DTCIUnused3_77B : 5|1@0+ (1,0) [0|1] ""  HMIM_HS,ONSTAR_HS
 SG_ DTCIUnused2_77B : 6|1@0+ (1,0) [0|1] ""  HMIM_HS,ONSTAR_HS
 SG_ DTCIUnused1_77B : 7|1@0+ (1,0) [0|1] ""  HMIM_HS,ONSTAR_HS

BO_ 587 USDT_Req_to_EOCM_FCM_HS: 8 TestTool_HS
 SG_ DgnInf : 7|64@0+ (1,0) [0|1.84467440737096E+019] ""  CGM_HS,EOCM_F_HS,FCM_HS

BO_ 1611 USDT_Resp_From_EOCM_FCM_HS: 8 FCM_HS
 SG_ DgnInf : 7|64@0+ (1,0) [0|1.84467440737096E+019] ""  CGM_HS,ONSTAR_HS,TestTool_HS

BO_ 1355 UUDT_Resp_From_EOCM_FCM_HS: 8 FCM_HS
 SG_ DgnInf_HS54B : 7|64@0+ (1,0) [0|1.84467440737096E+019] ""  CGM_HS,ONSTAR_HS,TestTool_HS

BO_TX_BU_ 1909 : MCP_A_HS,MCP_HS;
BO_TX_BU_ 1910 : HCP_B_HS,HCP_HS,BCP_HS;
BO_TX_BU_ 1912 : VES_HS,EPS_HS;
BO_TX_BU_ 1916 : CGM_HS,AHL_AFL_HS;
BO_TX_BU_ 1357 : CGM_HS,ONSTAR_HS;
BO_TX_BU_ 1613 : CGM_HS,ONSTAR_HS;
BO_TX_BU_ 1606 : CGM_HS,APPS_HS;
BO_TX_BU_ 582 : CGM_HS,ONSTAR_HS,TestTool_HS;
BO_TX_BU_ 590 : CGM_HS,ONSTAR_HS,TestTool_HS;
BO_TX_BU_ 601 : CGM_HS,ONSTAR_HS,TestTool_HS;
BO_TX_BU_ 1356 : CGM_HS,PFAF_HS;
BO_TX_BU_ 2023 : CGM_HS,ONSTAR_HS,TestTool_HS;
BO_TX_BU_ 2021 : CGM_HS,ONSTAR_HS,TestTool_HS;
BO_TX_BU_ 2017 : CGM_HS,ONSTAR_HS,TestTool_HS;
BO_TX_BU_ 2019 : CGM_HS,ONSTAR_HS,TestTool_HS;
BO_TX_BU_ 585 : CGM_HS,ONSTAR_HS,TestTool_HS;
BO_TX_BU_ 578 : CGM_HS,ONSTAR_HS,TestTool_HS;
BO_TX_BU_ 2022 : CGM_HS,ONSTAR_HS,TestTool_HS;
BO_TX_BU_ 584 : CGM_HS,ONSTAR_HS,TestTool_HS;
BO_TX_BU_ 591 : CGM_HS,ONSTAR_HS,TestTool_HS;
BO_TX_BU_ 581 : CGM_HS,ONSTAR_HS,TestTool_HS;
BO_TX_BU_ 586 : CGM_HS,ONSTAR_HS,TestTool_HS;
BO_TX_BU_ 588 : CGM_HS,ONSTAR_HS,TestTool_HS;
BO_TX_BU_ 580 : CGM_HS,ONSTAR_HS,TestTool_HS;
BO_TX_BU_ 1282 : ICCM_OBD_HS,ICCM_HS,ALC_HS;
BO_TX_BU_ 1921 : CGM_HS,HCP_T_HS,APPS_HS;
BO_TX_BU_ 1920 : EBCM_OBD_HS,EBCM_HS;
BO_TX_BU_ 596 : CGM_HS,ONSTAR_HS,TestTool_HS;
BO_TX_BU_ 1350 : CGM_HS,APPS_HS;
BO_TX_BU_ 1914 : TCCM_HS,RDCM_HS;
BO_TX_BU_ 583 : CGM_HS,ONSTAR_HS,TestTool_HS;
BO_TX_BU_ 1907 : EBCM_OBD_HS,HPCC_HS,EBCM_HS;
BO_TX_BU_ 579 : CGM_HS,ONSTAR_HS,TestTool_HS;
BO_TX_BU_ 1603 : HPCC_HS,EBCM_HS;
BO_TX_BU_ 1347 : HPCC_HS,EBCM_HS;
BO_TX_BU_ 1915 : CGM_HS,ACC_HS;
BO_TX_BU_ 587 : CGM_HS,ONSTAR_HS,TestTool_HS;
BO_TX_BU_ 1611 : CGM_HS,EOCM_F_HS,FCM_HS;
BO_TX_BU_ 1355 : CGM_HS,EOCM_F_HS,FCM_HS;
CM_ SG_ 1904 DTCI_DTCSource_770 "This shall be equal to the Diagnostic Address of the transmittting device.";
CM_ SG_ 1904 DTCI_DTCFaultType_770 "Based on Powertrain definition.  Not expected to be supported by all devices.";
CM_ SG_ 1904 DTCI_DTCFailType_770 "Assigned per GMW3110, Appendix E";
CM_ SG_ 1908 DTCI_DTCFaultType_774 "Based on Powertrain definition.  Not expected to be supported by all devices.";
CM_ SG_ 1908 DTCI_DTCFailType_774 "Assigned per GMW3110, Appendix E";
CM_ SG_ 1908 DTCI_DTCSource_774 "This shall be equal to the Diagnostic Address of the transmittting device.";
CM_ SG_ 1909 DTCI_DTCFaultType_775 "Based on Powertrain definition.  Not expected to be supported by all devices.";
CM_ SG_ 1909 DTCI_DTCFailType_775 "Assigned per GMW3110, Appendix E";
CM_ SG_ 1909 DTCI_DTCSource_775 "This shall be equal to the Diagnostic Address of the transmittting device.";
CM_ SG_ 1910 DTCI_DTCFaultType_776 "Based on Powertrain definition.  Not expected to be supported by all devices.";
CM_ SG_ 1910 DTCI_DTCFailType_776 "Assigned per GMW3110, Appendix E";
CM_ SG_ 1910 DTCI_DTCSource_776 "This shall be equal to the Diagnostic Address of the transmittting device.";
CM_ SG_ 1912 DTCI_DTCFaultType_778 "Based on Powertrain definition.  Not expected to be supported by all devices.";
CM_ SG_ 1912 DTCI_DTCFailType_778 "Assigned per GMW3110, Appendix E";
CM_ SG_ 1912 DTCI_DTCSource_778 "This shall be equal to the Diagnostic Address of the transmittting device.";
CM_ SG_ 1913 DTCI_DTCFaultType_779 "Based on Powertrain definition.  Not expected to be supported by all devices.";
CM_ SG_ 1913 DTCI_DTCFailType_779 "Assigned per GMW3110, Appendix E";
CM_ SG_ 1913 DTCI_DTCSource_779 "This shall be equal to the Diagnostic Address of the transmittting device.";
CM_ SG_ 1916 DTCI_DTCFaultType_77C "Based on Powertrain definition.  Not expected to be supported by all devices.";
CM_ SG_ 1916 DTCI_DTCFailType_77C "Assigned per GMW3110, Appendix E";
CM_ SG_ 1916 DTCI_DTCSource_77C "This shall be equal to the Diagnostic Address of the transmittting device.";
CM_ SG_ 1917 DTCI_DTCFaultType_77D "Based on Powertrain definition.  Not expected to be supported by all devices.";
CM_ SG_ 1917 DTCI_DTCFailType_77D "Assigned per GMW3110, Appendix E";
CM_ SG_ 1917 DTCI_DTCSource_77D "This shall be equal to the Diagnostic Address of the transmittting device.";
CM_ SG_ 1918 DTCI_DTCFaultType_77E "Based on Powertrain definition.  Not expected to be supported by all devices.";
CM_ SG_ 1918 DTCI_DTCFailType_77E "Assigned per GMW3110, Appendix E";
CM_ SG_ 1918 DTCI_DTCSource_77E "This shall be equal to the Diagnostic Address of the transmittting device.";
CM_ SG_ 1919 DTCI_DTCFaultType_77F "Based on Powertrain definition.  Not expected to be supported by all devices.";
CM_ SG_ 1919 DTCI_DTCFailType_77F "Assigned per GMW3110, Appendix E";
CM_ SG_ 1919 DTCI_DTCSource_77F "This shall be equal to the Diagnostic Address of the transmittting device.";
CM_ SG_ 499 PFTrnsTUDSecSwSt "Added 2006 Nov 10 according to CR1112";
CM_ BO_ 1282 "ALC will not (and cannot) be present on vehicles where the ICCM will transmit HS $502. Currently, this is only envisioned for high-performance vehicles.";
CM_ SG_ 1921 DTCI_DTCSource_781 "This shall be equal to the Diagnostic Address of the transmittting device.";
CM_ SG_ 1921 DTCI_DTCFaultType_781 "Based on Powertrain definition.  Not expected to be supported by all devices.";
CM_ SG_ 1921 DTCI_DTCFailType_781 "Assigned per GMW3110, Appendix E";
CM_ SG_ 1920 DTCI_DTCSource_780 "This shall be equal to the Diagnostic Address of the transmittting device.";
CM_ SG_ 1920 DTCI_DTCFaultType_780 "Based on Powertrain definition.  Not expected to be supported by all devices.";
CM_ SG_ 1920 DTCI_DTCFailType_780 "Assigned per GMW3110, Appendix E";
CM_ SG_ 1914 DTCI_DTCFaultType_77A "Based on Powertrain definition.  Not expected to be supported by all devices.";
CM_ SG_ 1914 DTCI_DTCFailType_77A "Assigned per GMW3110, Appendix E";
CM_ SG_ 1914 DTCI_DTCSource_77A "This shall be equal to the Diagnostic Address of the transmittting device.";
CM_ SG_ 1911 DTCI_DTCFaultType_777 "Based on Powertrain definition.  Not expected to be supported by all devices.";
CM_ SG_ 1911 DTCI_DTCFailType_777 "Assigned per GMW3110, Appendix E";
CM_ SG_ 1911 DTCI_DTCSource_777 "This shall be equal to the Diagnostic Address of the transmittting device.";
CM_ SG_ 1906 DTCI_DTCFaultType_772 "Based on Powertrain definition.  Not expected to be supported by all devices.";
CM_ SG_ 1906 DTCI_DTCFailType_772 "Assigned per GMW3110, Appendix E";
CM_ SG_ 1906 DTCI_DTCSource_772 "This shall be equal to the Diagnostic Address of the transmittting device.";
CM_ SG_ 1907 DTCI_DTCFaultType_773 "Based on Powertrain definition.  Not expected to be supported by all devices.";
CM_ SG_ 1907 DTCI_DTCFailType_773 "Assigned per GMW3110, Appendix E";
CM_ SG_ 1907 DTCI_DTCSource_773 "This shall be equal to the Diagnostic Address of the transmittting device.";
CM_ SG_ 1915 DTCI_DTCFaultType_77B "Based on Powertrain definition.  Not expected to be supported by all devices.";
CM_ SG_ 1915 DTCI_DTCFailType_77B "Assigned per GMW3110, Appendix E";
CM_ SG_ 1915 DTCI_DTCSource_77B "This shall be equal to the Diagnostic Address of the transmittting device.";
BA_DEF_ SG_  "VNSigSLHS_VNReq" ENUM  "No","Yes";
BA_DEF_ SG_  "VNSigSLHSSharedDiagnostic" ENUM  "No","Yes";
BA_DEF_ SG_  "SignalType" STRING ;
BA_DEF_ SG_  "PacketOrder" INT 0 65535;
BA_DEF_ SG_  "SignalLongName" STRING ;
BA_DEF_ SG_  "GenSigStartValue" INT 0 65535;
BA_DEF_ SG_  "VNSigAllNodes" ENUM  "No","Yes";
BA_DEF_ SG_  "GenSigDeltaValue" INT 0 0;
BA_DEF_ SG_  "GenSigSendType" ENUM  "not used","not used","not used","not used","not used","not used","not used","NoSigSendType","not used","not used","OnAnyChange","OnChangeIfActive","OnDelta";
BA_DEF_ SG_  "GenSigSendOnInit" ENUM  "Not Initialized","Application","Handler";
BA_DEF_ BO_  "AppGenMsgCycleTime" INT 0 0;
BA_DEF_ BO_  "TpTxIndex" INT 0 99;
BA_DEF_ BO_  "GenMsgILSupport" ENUM  "No","Yes";
BA_DEF_ BO_  "TpApplType" STRING ;
BA_DEF_ BO_  "Prio" INT 0 7;
BA_DEF_ BO_  "MessageSubnet" ENUM  "LS","MS","HS","CE","PE","HV","FO","S1","HE","LE","HE2";
BA_DEF_ BO_  "DiagState" ENUM  "No","Yes";
BA_DEF_ BO_  "GenMsgStartDelayTime" INT 0 100000;
BA_DEF_ BO_  "GenMsgDelayTime" INT 0 100000;
BA_DEF_ BO_  "GenMsgCycleTime" INT 0 100000;
BA_DEF_ BO_  "GenMsgSendType" ENUM  "cyclicX","spontanX","cyclicIfActiveX","spontanWithDelay","cyclicAndSpontanX","cyclicAndSpontanWithDelay","spontanWithRepitition","cyclicIfActiveAndSpontanWD";
BA_DEF_ BO_  "DiagResponse" ENUM  "No","Yes";
BA_DEF_ BO_  "DiagRequest" ENUM  "No","Yes";
BA_DEF_ BO_  "NmMessage" ENUM  "No","Yes";
BA_DEF_REL_ BU_SG_REL_  "GenSigSuprvRespComment" STRING ;
BA_DEF_REL_ BU_SG_REL_  "GenSigVBitResp" ENUM  "No","Yes";
BA_DEF_REL_ BU_SG_REL_  "GenSigVBitRespComment" STRING ;
BA_DEF_REL_ BU_SG_REL_  "GenSigVDAFailComment" STRING ;
BA_DEF_REL_ BU_SG_REL_  "GenSigVDAFailResp" ENUM  "No","Yes";
BA_DEF_REL_ BU_SG_REL_  "GenSigRxStartValue" STRING ;
BA_DEF_REL_ BU_SG_REL_  "GenSigSuprvRespSubValue" INT 0 65535;
BA_DEF_REL_ BU_SG_REL_  "GenSigSuprvResp" ENUM  "None","Notify App","Substitute Default";
BA_DEF_REL_ BU_SG_REL_  "GenSigTimeoutMsg" HEX -2147483648 268435455;
BA_DEF_REL_ BU_SG_REL_  "GenSigTimeoutTime" INT 0 15000;
BA_DEF_DEF_  "VNSigSLHS_VNReq" "No";
BA_DEF_DEF_  "VNSigSLHSSharedDiagnostic" "No";
BA_DEF_DEF_  "SignalType" "";
BA_DEF_DEF_  "PacketOrder" 0;
BA_DEF_DEF_  "SignalLongName" "";
BA_DEF_DEF_  "GenSigStartValue" 0;
BA_DEF_DEF_  "VNSigAllNodes" "No";
BA_DEF_DEF_  "GenSigDeltaValue" 0;
BA_DEF_DEF_  "GenSigSendType" "NoSigSendType";
BA_DEF_DEF_  "GenSigSendOnInit" "Not Initialized";
BA_DEF_DEF_  "AppGenMsgCycleTime" 0;
BA_DEF_DEF_  "TpTxIndex" 0;
BA_DEF_DEF_  "GenMsgILSupport" "Yes";
BA_DEF_DEF_  "TpApplType" "";
BA_DEF_DEF_  "Prio" 4;
BA_DEF_DEF_  "MessageSubnet" "FO";
BA_DEF_DEF_  "DiagState" "No";
BA_DEF_DEF_  "GenMsgStartDelayTime" 0;
BA_DEF_DEF_  "GenMsgDelayTime" 0;
BA_DEF_DEF_  "GenMsgCycleTime" 0;
BA_DEF_DEF_  "GenMsgSendType" "spontanX";
BA_DEF_DEF_  "DiagResponse" "No";
BA_DEF_DEF_  "DiagRequest" "No";
BA_DEF_DEF_  "NmMessage" "No";
BA_DEF_DEF_REL_ "GenSigSuprvRespComment" "";
BA_DEF_DEF_REL_ "GenSigVBitResp" "No";
BA_DEF_DEF_REL_ "GenSigVBitRespComment" "";
BA_DEF_DEF_REL_ "GenSigVDAFailComment" "";
BA_DEF_DEF_REL_ "GenSigVDAFailResp" "No";
BA_DEF_DEF_REL_ "GenSigRxStartValue" "";
BA_DEF_DEF_REL_ "GenSigSuprvRespSubValue" 0;
BA_DEF_DEF_REL_ "GenSigSuprvResp" "None";
BA_DEF_DEF_REL_ "GenSigTimeoutMsg" 0;
BA_DEF_DEF_REL_ "GenSigTimeoutTime" 0;
BA_ "Prio" BO_ 1904 6;
BA_ "MessageSubnet" BO_ 1904 2;
BA_ "GenMsgCycleTime" BO_ 1904 1000;
BA_ "GenMsgSendType" BO_ 1904 0;
BA_ "Prio" BO_ 1908 6;
BA_ "MessageSubnet" BO_ 1908 2;
BA_ "GenMsgCycleTime" BO_ 1908 1000;
BA_ "GenMsgSendType" BO_ 1908 0;
BA_ "Prio" BO_ 1909 6;
BA_ "MessageSubnet" BO_ 1909 2;
BA_ "GenMsgCycleTime" BO_ 1909 1000;
BA_ "GenMsgSendType" BO_ 1909 0;
BA_ "Prio" BO_ 1910 6;
BA_ "MessageSubnet" BO_ 1910 2;
BA_ "GenMsgCycleTime" BO_ 1910 1000;
BA_ "GenMsgSendType" BO_ 1910 0;
BA_ "Prio" BO_ 1912 6;
BA_ "MessageSubnet" BO_ 1912 2;
BA_ "GenMsgCycleTime" BO_ 1912 1000;
BA_ "GenMsgSendType" BO_ 1912 0;
BA_ "Prio" BO_ 1913 6;
BA_ "MessageSubnet" BO_ 1913 2;
BA_ "GenMsgCycleTime" BO_ 1913 1000;
BA_ "GenMsgSendType" BO_ 1913 0;
BA_ "Prio" BO_ 1916 6;
BA_ "MessageSubnet" BO_ 1916 2;
BA_ "GenMsgCycleTime" BO_ 1916 1000;
BA_ "GenMsgSendType" BO_ 1916 0;
BA_ "Prio" BO_ 1917 6;
BA_ "MessageSubnet" BO_ 1917 2;
BA_ "GenMsgCycleTime" BO_ 1917 1000;
BA_ "GenMsgSendType" BO_ 1917 0;
BA_ "Prio" BO_ 1918 6;
BA_ "MessageSubnet" BO_ 1918 2;
BA_ "GenMsgCycleTime" BO_ 1918 1000;
BA_ "GenMsgSendType" BO_ 1918 0;
BA_ "Prio" BO_ 1919 6;
BA_ "MessageSubnet" BO_ 1919 2;
BA_ "GenMsgCycleTime" BO_ 1919 1000;
BA_ "GenMsgSendType" BO_ 1919 0;
BA_ "Prio" BO_ 589 0;
BA_ "MessageSubnet" BO_ 589 2;
BA_ "DiagRequest" BO_ 589 1;
BA_ "GenMsgILSupport" BO_ 1357 0;
BA_ "TpApplType" BO_ 1357 "DiagUUDTResponse";
BA_ "Prio" BO_ 1357 0;
BA_ "MessageSubnet" BO_ 1357 2;
BA_ "Prio" BO_ 1613 0;
BA_ "MessageSubnet" BO_ 1613 2;
BA_ "DiagResponse" BO_ 1613 1;
BA_ "Prio" BO_ 1606 0;
BA_ "MessageSubnet" BO_ 1606 2;
BA_ "DiagResponse" BO_ 1606 1;
BA_ "Prio" BO_ 582 0;
BA_ "MessageSubnet" BO_ 582 2;
BA_ "DiagRequest" BO_ 582 1;
BA_ "Prio" BO_ 590 0;
BA_ "MessageSubnet" BO_ 590 2;
BA_ "DiagRequest" BO_ 590 1;
BA_ "Prio" BO_ 601 0;
BA_ "MessageSubnet" BO_ 601 2;
BA_ "DiagRequest" BO_ 601 1;
BA_ "GenMsgILSupport" BO_ 1369 0;
BA_ "TpApplType" BO_ 1369 "DiagUUDTResponse";
BA_ "Prio" BO_ 1369 0;
BA_ "MessageSubnet" BO_ 1369 2;
BA_ "Prio" BO_ 1625 0;
BA_ "MessageSubnet" BO_ 1625 2;
BA_ "DiagResponse" BO_ 1625 1;
BA_ "GenMsgILSupport" BO_ 1356 0;
BA_ "TpApplType" BO_ 1356 "DiagUUDTResponse";
BA_ "Prio" BO_ 1356 0;
BA_ "MessageSubnet" BO_ 1356 2;
BA_ "GenMsgILSupport" BO_ 1358 0;
BA_ "TpApplType" BO_ 1358 "DiagUUDTResponse";
BA_ "Prio" BO_ 1358 0;
BA_ "MessageSubnet" BO_ 1358 2;
BA_ "GenMsgILSupport" BO_ 1359 0;
BA_ "TpApplType" BO_ 1359 "DiagUUDTResponse";
BA_ "Prio" BO_ 1359 0;
BA_ "MessageSubnet" BO_ 1359 2;
BA_ "Prio" BO_ 2023 0;
BA_ "MessageSubnet" BO_ 2023 2;
BA_ "DiagRequest" BO_ 2023 1;
BA_ "Prio" BO_ 2021 0;
BA_ "MessageSubnet" BO_ 2021 2;
BA_ "DiagRequest" BO_ 2021 1;
BA_ "Prio" BO_ 2017 0;
BA_ "MessageSubnet" BO_ 2017 2;
BA_ "DiagRequest" BO_ 2017 1;
BA_ "Prio" BO_ 2019 0;
BA_ "MessageSubnet" BO_ 2019 2;
BA_ "DiagRequest" BO_ 2019 1;
BA_ "Prio" BO_ 585 0;
BA_ "MessageSubnet" BO_ 585 2;
BA_ "DiagRequest" BO_ 585 1;
BA_ "Prio" BO_ 578 0;
BA_ "MessageSubnet" BO_ 578 2;
BA_ "DiagRequest" BO_ 578 1;
BA_ "Prio" BO_ 2022 0;
BA_ "MessageSubnet" BO_ 2022 2;
BA_ "DiagRequest" BO_ 2022 1;
BA_ "Prio" BO_ 584 0;
BA_ "MessageSubnet" BO_ 584 2;
BA_ "DiagRequest" BO_ 584 1;
BA_ "Prio" BO_ 591 0;
BA_ "MessageSubnet" BO_ 591 2;
BA_ "DiagRequest" BO_ 591 1;
BA_ "Prio" BO_ 581 0;
BA_ "MessageSubnet" BO_ 581 2;
BA_ "DiagRequest" BO_ 581 1;
BA_ "Prio" BO_ 586 0;
BA_ "MessageSubnet" BO_ 586 2;
BA_ "DiagRequest" BO_ 586 1;
BA_ "GenMsgILSupport" BO_ 588 0;
BA_ "Prio" BO_ 588 0;
BA_ "MessageSubnet" BO_ 588 2;
BA_ "DiagRequest" BO_ 588 1;
BA_ "Prio" BO_ 580 0;
BA_ "MessageSubnet" BO_ 580 2;
BA_ "DiagRequest" BO_ 580 1;
BA_ "Prio" BO_ 499 0;
BA_ "MessageSubnet" BO_ 499 2;
BA_ "GenMsgStartDelayTime" BO_ 499 20;
BA_ "GenMsgCycleTime" BO_ 499 30;
BA_ "GenMsgSendType" BO_ 499 0;
BA_ "Prio" BO_ 1282 0;
BA_ "MessageSubnet" BO_ 1282 2;
BA_ "GenMsgCycleTime" BO_ 1282 500;
BA_ "GenMsgSendType" BO_ 1282 0;
BA_ "GenMsgILSupport" BO_ 1360 0;
BA_ "TpApplType" BO_ 1360 "DiagUUDTResponse";
BA_ "Prio" BO_ 1360 0;
BA_ "MessageSubnet" BO_ 1360 2;
BA_ "Prio" BO_ 1616 0;
BA_ "MessageSubnet" BO_ 1616 2;
BA_ "DiagResponse" BO_ 1616 1;
BA_ "Prio" BO_ 1921 0;
BA_ "MessageSubnet" BO_ 1921 2;
BA_ "GenMsgCycleTime" BO_ 1921 1000;
BA_ "GenMsgSendType" BO_ 1921 0;
BA_ "Prio" BO_ 1920 0;
BA_ "MessageSubnet" BO_ 1920 2;
BA_ "GenMsgCycleTime" BO_ 1920 1000;
BA_ "GenMsgSendType" BO_ 1920 0;
BA_ "Prio" BO_ 596 0;
BA_ "MessageSubnet" BO_ 596 2;
BA_ "DiagRequest" BO_ 596 1;
BA_ "Prio" BO_ 2033 0;
BA_ "MessageSubnet" BO_ 2033 2;
BA_ "Prio" BO_ 495 0;
BA_ "MessageSubnet" BO_ 495 2;
BA_ "GenMsgCycleTime" BO_ 495 12;
BA_ "GenMsgSendType" BO_ 495 0;
BA_ "GenMsgILSupport" BO_ 1350 0;
BA_ "TpApplType" BO_ 1350 "DiagUUDTResponse";
BA_ "Prio" BO_ 1350 0;
BA_ "MessageSubnet" BO_ 1350 2;
BA_ "Prio" BO_ 1914 6;
BA_ "MessageSubnet" BO_ 1914 2;
BA_ "GenMsgCycleTime" BO_ 1914 1000;
BA_ "GenMsgSendType" BO_ 1914 0;
BA_ "Prio" BO_ 1911 6;
BA_ "MessageSubnet" BO_ 1911 2;
BA_ "GenMsgCycleTime" BO_ 1911 1000;
BA_ "GenMsgSendType" BO_ 1911 0;
BA_ "Prio" BO_ 583 0;
BA_ "MessageSubnet" BO_ 583 2;
BA_ "DiagRequest" BO_ 583 1;
BA_ "GenMsgILSupport" BO_ 1351 0;
BA_ "TpApplType" BO_ 1351 "DiagUUDTResponse";
BA_ "Prio" BO_ 1351 0;
BA_ "MessageSubnet" BO_ 1351 2;
BA_ "Prio" BO_ 1607 0;
BA_ "MessageSubnet" BO_ 1607 2;
BA_ "DiagResponse" BO_ 1607 1;
BA_ "Prio" BO_ 1906 6;
BA_ "MessageSubnet" BO_ 1906 2;
BA_ "GenMsgCycleTime" BO_ 1906 1000;
BA_ "GenMsgSendType" BO_ 1906 0;
BA_ "Prio" BO_ 1907 6;
BA_ "MessageSubnet" BO_ 1907 2;
BA_ "GenMsgCycleTime" BO_ 1907 1000;
BA_ "GenMsgSendType" BO_ 1907 0;
BA_ "Prio" BO_ 579 0;
BA_ "MessageSubnet" BO_ 579 2;
BA_ "DiagRequest" BO_ 579 1;
BA_ "Prio" BO_ 1603 0;
BA_ "MessageSubnet" BO_ 1603 2;
BA_ "DiagResponse" BO_ 1603 1;
BA_ "GenMsgILSupport" BO_ 1347 0;
BA_ "TpApplType" BO_ 1347 "DiagUUDTResponse";
BA_ "Prio" BO_ 1347 0;
BA_ "MessageSubnet" BO_ 1347 2;
BA_ "Prio" BO_ 1915 6;
BA_ "MessageSubnet" BO_ 1915 2;
BA_ "GenMsgCycleTime" BO_ 1915 1000;
BA_ "GenMsgSendType" BO_ 1915 0;
BA_ "GenMsgILSupport" BO_ 587 0;
BA_ "Prio" BO_ 587 0;
BA_ "MessageSubnet" BO_ 587 2;
BA_ "DiagRequest" BO_ 587 1;
BA_ "GenMsgILSupport" BO_ 1611 0;
BA_ "Prio" BO_ 1611 0;
BA_ "MessageSubnet" BO_ 1611 2;
BA_ "DiagResponse" BO_ 1611 1;
BA_ "GenMsgILSupport" BO_ 1355 0;
BA_ "TpApplType" BO_ 1355 "DiagUUDTResponse";
BA_ "Prio" BO_ 1355 0;
BA_ "MessageSubnet" BO_ 1355 2;
BA_ "SignalType" SG_ 1904 DTCI_WrnIndRqdSt_770 "BLN";
BA_ "PacketOrder" SG_ 1904 DTCI_WrnIndRqdSt_770 12;
BA_ "SignalLongName" SG_ 1904 DTCI_WrnIndRqdSt_770 "Diagnostic Trouble Code Information Extended 770 : Warning Indicator Requested Status";
BA_ "VNSigAllNodes" SG_ 1904 DTCI_WrnIndRqdSt_770 1;
BA_ "SignalType" SG_ 1904 DTCIUnused7_770 "BLN";
BA_ "PacketOrder" SG_ 1904 DTCIUnused7_770 1;
BA_ "SignalLongName" SG_ 1904 DTCIUnused7_770 "Diagnostic Trouble Code Information Extended 770 : Unused 7";
BA_ "VNSigAllNodes" SG_ 1904 DTCIUnused7_770 1;
BA_ "SignalType" SG_ 1904 DTCIUnused6_770 "BLN";
BA_ "PacketOrder" SG_ 1904 DTCIUnused6_770 2;
BA_ "SignalLongName" SG_ 1904 DTCIUnused6_770 "Diagnostic Trouble Code Information Extended 770 : Unused 6";
BA_ "VNSigAllNodes" SG_ 1904 DTCIUnused6_770 1;
BA_ "SignalType" SG_ 1904 DTCIUnused5_770 "BLN";
BA_ "PacketOrder" SG_ 1904 DTCIUnused5_770 3;
BA_ "SignalLongName" SG_ 1904 DTCIUnused5_770 "Diagnostic Trouble Code Information Extended 770 : Unused 5";
BA_ "VNSigAllNodes" SG_ 1904 DTCIUnused5_770 1;
BA_ "SignalType" SG_ 1904 DTCIUnused4_770 "BLN";
BA_ "PacketOrder" SG_ 1904 DTCIUnused4_770 4;
BA_ "SignalLongName" SG_ 1904 DTCIUnused4_770 "Diagnostic Trouble Code Information Extended 770 : Unused 4";
BA_ "VNSigAllNodes" SG_ 1904 DTCIUnused4_770 1;
BA_ "SignalType" SG_ 1904 DTCIUnused3_770 "BLN";
BA_ "PacketOrder" SG_ 1904 DTCIUnused3_770 5;
BA_ "SignalLongName" SG_ 1904 DTCIUnused3_770 "Diagnostic Trouble Code Information Extended 770 : Unused 3";
BA_ "VNSigAllNodes" SG_ 1904 DTCIUnused3_770 1;
BA_ "SignalType" SG_ 1904 DTCIUnused2_770 "BLN";
BA_ "PacketOrder" SG_ 1904 DTCIUnused2_770 6;
BA_ "SignalLongName" SG_ 1904 DTCIUnused2_770 "Diagnostic Trouble Code Information Extended 770 : Unused 2";
BA_ "VNSigAllNodes" SG_ 1904 DTCIUnused2_770 1;
BA_ "SignalType" SG_ 1904 DTCIUnused1_770 "BLN";
BA_ "PacketOrder" SG_ 1904 DTCIUnused1_770 7;
BA_ "SignalLongName" SG_ 1904 DTCIUnused1_770 "Diagnostic Trouble Code Information Extended 770 : Unused 1";
BA_ "VNSigAllNodes" SG_ 1904 DTCIUnused1_770 1;
BA_ "SignalType" SG_ 1904 DTCI_TstNPsdPwrUpSt_770 "BLN";
BA_ "PacketOrder" SG_ 1904 DTCI_TstNPsdPwrUpSt_770 14;
BA_ "SignalLongName" SG_ 1904 DTCI_TstNPsdPwrUpSt_770 "Diagnostic Trouble Code Information Extended 770 : Test Not Passed Since Power Up Status";
BA_ "VNSigAllNodes" SG_ 1904 DTCI_TstNPsdPwrUpSt_770 1;
BA_ "SignalType" SG_ 1904 DTCI_TstNPsdCdClrdSt_770 "BLN";
BA_ "PacketOrder" SG_ 1904 DTCI_TstNPsdCdClrdSt_770 17;
BA_ "SignalLongName" SG_ 1904 DTCI_TstNPsdCdClrdSt_770 "Diagnostic Trouble Code Information Extended 770 : Test Not Passed Since Code Cleared Status";
BA_ "VNSigAllNodes" SG_ 1904 DTCI_TstNPsdCdClrdSt_770 1;
BA_ "SignalType" SG_ 1904 DTCI_TstFldPwrUpSt_770 "BLN";
BA_ "PacketOrder" SG_ 1904 DTCI_TstFldPwrUpSt_770 13;
BA_ "SignalLongName" SG_ 1904 DTCI_TstFldPwrUpSt_770 "Diagnostic Trouble Code Information Extended 770 : Test Failed Since Power Up Status";
BA_ "VNSigAllNodes" SG_ 1904 DTCI_TstFldPwrUpSt_770 1;
BA_ "SignalType" SG_ 1904 DTCI_TstFldCdClrdStat_770 "BLN";
BA_ "PacketOrder" SG_ 1904 DTCI_TstFldCdClrdStat_770 16;
BA_ "SignalLongName" SG_ 1904 DTCI_TstFldCdClrdStat_770 "Diagnostic Trouble Code Information Extended 770 : Test Failed Since Code Cleared Status";
BA_ "VNSigAllNodes" SG_ 1904 DTCI_TstFldCdClrdStat_770 1;
BA_ "SignalType" SG_ 1904 DTCI_HistStat_770 "BLN";
BA_ "PacketOrder" SG_ 1904 DTCI_HistStat_770 15;
BA_ "SignalLongName" SG_ 1904 DTCI_HistStat_770 "Diagnostic Trouble Code Information Extended 770 : History Status";
BA_ "VNSigAllNodes" SG_ 1904 DTCI_HistStat_770 1;
BA_ "SignalType" SG_ 1904 DTCI_DTCTriggered_770 "BLN";
BA_ "PacketOrder" SG_ 1904 DTCI_DTCTriggered_770 8;
BA_ "SignalLongName" SG_ 1904 DTCI_DTCTriggered_770 "Diagnostic Trouble Code Information Extended 770 : Diagnostic Trouble Code Triggered";
BA_ "VNSigAllNodes" SG_ 1904 DTCI_DTCTriggered_770 1;
BA_ "SignalType" SG_ 1904 DTCI_DTCSource_770 "UNM";
BA_ "PacketOrder" SG_ 1904 DTCI_DTCSource_770 9;
BA_ "SignalLongName" SG_ 1904 DTCI_DTCSource_770 "Diagnostic Trouble Code Information Extended 770 : Diagnostic Trouble Code Source";
BA_ "VNSigAllNodes" SG_ 1904 DTCI_DTCSource_770 1;
BA_ "SignalType" SG_ 1904 DTCI_DTCNumber_770 "UNM";
BA_ "PacketOrder" SG_ 1904 DTCI_DTCNumber_770 10;
BA_ "SignalLongName" SG_ 1904 DTCI_DTCNumber_770 "Diagnostic Trouble Code Information Extended 770 : Diagnostic Trouble Code Number";
BA_ "VNSigAllNodes" SG_ 1904 DTCI_DTCNumber_770 1;
BA_ "SignalType" SG_ 1904 DTCI_DTCFaultType_770 "ENM";
BA_ "PacketOrder" SG_ 1904 DTCI_DTCFaultType_770 20;
BA_ "SignalLongName" SG_ 1904 DTCI_DTCFaultType_770 "Diagnostic Trouble Code Information Extended 770 : Diagnostic Trouble Code Fault Type";
BA_ "VNSigAllNodes" SG_ 1904 DTCI_DTCFaultType_770 1;
BA_ "SignalType" SG_ 1904 DTCI_DTCFailType_770 "UNM";
BA_ "PacketOrder" SG_ 1904 DTCI_DTCFailType_770 11;
BA_ "SignalLongName" SG_ 1904 DTCI_DTCFailType_770 "Diagnostic Trouble Code Information Extended 770 : Diagnostic Trouble Code Failure Type";
BA_ "VNSigAllNodes" SG_ 1904 DTCI_DTCFailType_770 1;
BA_ "SignalType" SG_ 1904 DTCI_CurrentStatus_770 "BLN";
BA_ "PacketOrder" SG_ 1904 DTCI_CurrentStatus_770 18;
BA_ "SignalLongName" SG_ 1904 DTCI_CurrentStatus_770 "Diagnostic Trouble Code Information Extended 770 : Current Status";
BA_ "VNSigAllNodes" SG_ 1904 DTCI_CurrentStatus_770 1;
BA_ "SignalType" SG_ 1904 DTCI_CodeSupported_770 "BLN";
BA_ "PacketOrder" SG_ 1904 DTCI_CodeSupported_770 19;
BA_ "SignalLongName" SG_ 1904 DTCI_CodeSupported_770 "Diagnostic Trouble Code Information Extended 770 : Code Supported";
BA_ "VNSigAllNodes" SG_ 1904 DTCI_CodeSupported_770 1;
BA_ "SignalType" SG_ 1908 DTCI_DTCFaultType_774 "ENM";
BA_ "PacketOrder" SG_ 1908 DTCI_DTCFaultType_774 20;
BA_ "SignalLongName" SG_ 1908 DTCI_DTCFaultType_774 "Diagnostic Trouble Code Information Extended 774 : Diagnostic Trouble Code Fault Type";
BA_ "VNSigAllNodes" SG_ 1908 DTCI_DTCFaultType_774 1;
BA_ "SignalType" SG_ 1908 DTCI_CodeSupported_774 "BLN";
BA_ "PacketOrder" SG_ 1908 DTCI_CodeSupported_774 19;
BA_ "SignalLongName" SG_ 1908 DTCI_CodeSupported_774 "Diagnostic Trouble Code Information Extended 774 : Code Supported";
BA_ "VNSigAllNodes" SG_ 1908 DTCI_CodeSupported_774 1;
BA_ "SignalType" SG_ 1908 DTCI_CurrentStatus_774 "BLN";
BA_ "PacketOrder" SG_ 1908 DTCI_CurrentStatus_774 18;
BA_ "SignalLongName" SG_ 1908 DTCI_CurrentStatus_774 "Diagnostic Trouble Code Information Extended 774 : Current Status";
BA_ "VNSigAllNodes" SG_ 1908 DTCI_CurrentStatus_774 1;
BA_ "SignalType" SG_ 1908 DTCI_TstNPsdCdClrdSt_774 "BLN";
BA_ "PacketOrder" SG_ 1908 DTCI_TstNPsdCdClrdSt_774 17;
BA_ "SignalLongName" SG_ 1908 DTCI_TstNPsdCdClrdSt_774 "Diagnostic Trouble Code Information Extended 774 : Test Not Passed Since Code Cleared Status";
BA_ "VNSigAllNodes" SG_ 1908 DTCI_TstNPsdCdClrdSt_774 1;
BA_ "SignalType" SG_ 1908 DTCI_TstFldCdClrdStat_774 "BLN";
BA_ "PacketOrder" SG_ 1908 DTCI_TstFldCdClrdStat_774 16;
BA_ "SignalLongName" SG_ 1908 DTCI_TstFldCdClrdStat_774 "Diagnostic Trouble Code Information Extended 774 : Test Failed Since Code Cleared Status";
BA_ "VNSigAllNodes" SG_ 1908 DTCI_TstFldCdClrdStat_774 1;
BA_ "SignalType" SG_ 1908 DTCI_HistStat_774 "BLN";
BA_ "PacketOrder" SG_ 1908 DTCI_HistStat_774 15;
BA_ "SignalLongName" SG_ 1908 DTCI_HistStat_774 "Diagnostic Trouble Code Information Extended 774 : History Status";
BA_ "VNSigAllNodes" SG_ 1908 DTCI_HistStat_774 1;
BA_ "SignalType" SG_ 1908 DTCI_TstNPsdPwrUpSt_774 "BLN";
BA_ "PacketOrder" SG_ 1908 DTCI_TstNPsdPwrUpSt_774 14;
BA_ "SignalLongName" SG_ 1908 DTCI_TstNPsdPwrUpSt_774 "Diagnostic Trouble Code Information Extended 774 : Test Not Passed Since Power Up Status";
BA_ "VNSigAllNodes" SG_ 1908 DTCI_TstNPsdPwrUpSt_774 1;
BA_ "SignalType" SG_ 1908 DTCI_TstFldPwrUpSt_774 "BLN";
BA_ "PacketOrder" SG_ 1908 DTCI_TstFldPwrUpSt_774 13;
BA_ "SignalLongName" SG_ 1908 DTCI_TstFldPwrUpSt_774 "Diagnostic Trouble Code Information Extended 774 : Test Failed Since Power Up Status";
BA_ "VNSigAllNodes" SG_ 1908 DTCI_TstFldPwrUpSt_774 1;
BA_ "SignalType" SG_ 1908 DTCI_WrnIndRqdSt_774 "BLN";
BA_ "PacketOrder" SG_ 1908 DTCI_WrnIndRqdSt_774 12;
BA_ "SignalLongName" SG_ 1908 DTCI_WrnIndRqdSt_774 "Diagnostic Trouble Code Information Extended 774 : Warning Indicator Requested Status";
BA_ "VNSigAllNodes" SG_ 1908 DTCI_WrnIndRqdSt_774 1;
BA_ "SignalType" SG_ 1908 DTCI_DTCFailType_774 "UNM";
BA_ "PacketOrder" SG_ 1908 DTCI_DTCFailType_774 11;
BA_ "SignalLongName" SG_ 1908 DTCI_DTCFailType_774 "Diagnostic Trouble Code Information Extended 774 : Diagnostic Trouble Code Failure Type";
BA_ "VNSigAllNodes" SG_ 1908 DTCI_DTCFailType_774 1;
BA_ "SignalType" SG_ 1908 DTCI_DTCNumber_774 "UNM";
BA_ "PacketOrder" SG_ 1908 DTCI_DTCNumber_774 10;
BA_ "SignalLongName" SG_ 1908 DTCI_DTCNumber_774 "Diagnostic Trouble Code Information Extended 774 : Diagnostic Trouble Code Number";
BA_ "VNSigAllNodes" SG_ 1908 DTCI_DTCNumber_774 1;
BA_ "SignalType" SG_ 1908 DTCI_DTCSource_774 "UNM";
BA_ "PacketOrder" SG_ 1908 DTCI_DTCSource_774 9;
BA_ "SignalLongName" SG_ 1908 DTCI_DTCSource_774 "Diagnostic Trouble Code Information Extended 774 : Diagnostic Trouble Code Source";
BA_ "VNSigAllNodes" SG_ 1908 DTCI_DTCSource_774 1;
BA_ "SignalType" SG_ 1908 DTCI_DTCTriggered_774 "BLN";
BA_ "PacketOrder" SG_ 1908 DTCI_DTCTriggered_774 8;
BA_ "SignalLongName" SG_ 1908 DTCI_DTCTriggered_774 "Diagnostic Trouble Code Information Extended 774 : Diagnostic Trouble Code Triggered";
BA_ "VNSigAllNodes" SG_ 1908 DTCI_DTCTriggered_774 1;
BA_ "SignalType" SG_ 1908 DTCIUnused7_774 "BLN";
BA_ "PacketOrder" SG_ 1908 DTCIUnused7_774 7;
BA_ "SignalLongName" SG_ 1908 DTCIUnused7_774 "Diagnostic Trouble Code Information Extended 774 : Unused 7";
BA_ "VNSigAllNodes" SG_ 1908 DTCIUnused7_774 1;
BA_ "SignalType" SG_ 1908 DTCIUnused6_774 "BLN";
BA_ "PacketOrder" SG_ 1908 DTCIUnused6_774 6;
BA_ "SignalLongName" SG_ 1908 DTCIUnused6_774 "Diagnostic Trouble Code Information Extended 774 : Unused 6";
BA_ "VNSigAllNodes" SG_ 1908 DTCIUnused6_774 1;
BA_ "SignalType" SG_ 1908 DTCIUnused5_774 "BLN";
BA_ "PacketOrder" SG_ 1908 DTCIUnused5_774 5;
BA_ "SignalLongName" SG_ 1908 DTCIUnused5_774 "Diagnostic Trouble Code Information Extended 774 : Unused 5";
BA_ "VNSigAllNodes" SG_ 1908 DTCIUnused5_774 1;
BA_ "SignalType" SG_ 1908 DTCIUnused4_774 "BLN";
BA_ "PacketOrder" SG_ 1908 DTCIUnused4_774 4;
BA_ "SignalLongName" SG_ 1908 DTCIUnused4_774 "Diagnostic Trouble Code Information Extended 774 : Unused 4";
BA_ "VNSigAllNodes" SG_ 1908 DTCIUnused4_774 1;
BA_ "SignalType" SG_ 1908 DTCIUnused3_774 "BLN";
BA_ "PacketOrder" SG_ 1908 DTCIUnused3_774 3;
BA_ "SignalLongName" SG_ 1908 DTCIUnused3_774 "Diagnostic Trouble Code Information Extended 774 : Unused 3";
BA_ "VNSigAllNodes" SG_ 1908 DTCIUnused3_774 1;
BA_ "SignalType" SG_ 1908 DTCIUnused2_774 "BLN";
BA_ "PacketOrder" SG_ 1908 DTCIUnused2_774 2;
BA_ "SignalLongName" SG_ 1908 DTCIUnused2_774 "Diagnostic Trouble Code Information Extended 774 : Unused 2";
BA_ "VNSigAllNodes" SG_ 1908 DTCIUnused2_774 1;
BA_ "SignalType" SG_ 1908 DTCIUnused1_774 "BLN";
BA_ "PacketOrder" SG_ 1908 DTCIUnused1_774 1;
BA_ "SignalLongName" SG_ 1908 DTCIUnused1_774 "Diagnostic Trouble Code Information Extended 774 : Unused 1";
BA_ "VNSigAllNodes" SG_ 1908 DTCIUnused1_774 1;
BA_ "SignalType" SG_ 1909 DTCI_DTCFaultType_775 "ENM";
BA_ "PacketOrder" SG_ 1909 DTCI_DTCFaultType_775 20;
BA_ "SignalLongName" SG_ 1909 DTCI_DTCFaultType_775 "Diagnostic Trouble Code Information Extended 775 : Diagnostic Trouble Code Fault Type";
BA_ "VNSigAllNodes" SG_ 1909 DTCI_DTCFaultType_775 1;
BA_ "SignalType" SG_ 1909 DTCI_CodeSupported_775 "BLN";
BA_ "PacketOrder" SG_ 1909 DTCI_CodeSupported_775 19;
BA_ "SignalLongName" SG_ 1909 DTCI_CodeSupported_775 "Diagnostic Trouble Code Information Extended 775 : Code Supported";
BA_ "VNSigAllNodes" SG_ 1909 DTCI_CodeSupported_775 1;
BA_ "SignalType" SG_ 1909 DTCI_CurrentStatus_775 "BLN";
BA_ "PacketOrder" SG_ 1909 DTCI_CurrentStatus_775 18;
BA_ "SignalLongName" SG_ 1909 DTCI_CurrentStatus_775 "Diagnostic Trouble Code Information Extended 775 : Current Status";
BA_ "VNSigAllNodes" SG_ 1909 DTCI_CurrentStatus_775 1;
BA_ "SignalType" SG_ 1909 DTCI_TstNPsdCdClrdSt_775 "BLN";
BA_ "PacketOrder" SG_ 1909 DTCI_TstNPsdCdClrdSt_775 17;
BA_ "SignalLongName" SG_ 1909 DTCI_TstNPsdCdClrdSt_775 "Diagnostic Trouble Code Information Extended 775 : Test Not Passed Since Code Cleared Status";
BA_ "VNSigAllNodes" SG_ 1909 DTCI_TstNPsdCdClrdSt_775 1;
BA_ "SignalType" SG_ 1909 DTCI_TstFldCdClrdStat_775 "BLN";
BA_ "PacketOrder" SG_ 1909 DTCI_TstFldCdClrdStat_775 16;
BA_ "SignalLongName" SG_ 1909 DTCI_TstFldCdClrdStat_775 "Diagnostic Trouble Code Information Extended 775 : Test Failed Since Code Cleared Status";
BA_ "VNSigAllNodes" SG_ 1909 DTCI_TstFldCdClrdStat_775 1;
BA_ "SignalType" SG_ 1909 DTCI_HistStat_775 "BLN";
BA_ "PacketOrder" SG_ 1909 DTCI_HistStat_775 15;
BA_ "SignalLongName" SG_ 1909 DTCI_HistStat_775 "Diagnostic Trouble Code Information Extended 775 : History Status";
BA_ "VNSigAllNodes" SG_ 1909 DTCI_HistStat_775 1;
BA_ "SignalType" SG_ 1909 DTCI_TstNPsdPwrUpSt_775 "BLN";
BA_ "PacketOrder" SG_ 1909 DTCI_TstNPsdPwrUpSt_775 14;
BA_ "SignalLongName" SG_ 1909 DTCI_TstNPsdPwrUpSt_775 "Diagnostic Trouble Code Information Extended 775 : Test Not Passed Since Power Up Status";
BA_ "VNSigAllNodes" SG_ 1909 DTCI_TstNPsdPwrUpSt_775 1;
BA_ "SignalType" SG_ 1909 DTCI_TstFldPwrUpSt_775 "BLN";
BA_ "PacketOrder" SG_ 1909 DTCI_TstFldPwrUpSt_775 13;
BA_ "SignalLongName" SG_ 1909 DTCI_TstFldPwrUpSt_775 "Diagnostic Trouble Code Information Extended 775 : Test Failed Since Power Up Status";
BA_ "VNSigAllNodes" SG_ 1909 DTCI_TstFldPwrUpSt_775 1;
BA_ "SignalType" SG_ 1909 DTCI_WrnIndRqdSt_775 "BLN";
BA_ "PacketOrder" SG_ 1909 DTCI_WrnIndRqdSt_775 12;
BA_ "SignalLongName" SG_ 1909 DTCI_WrnIndRqdSt_775 "Diagnostic Trouble Code Information Extended 775 : Warning Indicator Requested Status";
BA_ "VNSigAllNodes" SG_ 1909 DTCI_WrnIndRqdSt_775 1;
BA_ "SignalType" SG_ 1909 DTCI_DTCFailType_775 "UNM";
BA_ "PacketOrder" SG_ 1909 DTCI_DTCFailType_775 11;
BA_ "SignalLongName" SG_ 1909 DTCI_DTCFailType_775 "Diagnostic Trouble Code Information Extended 775 : Diagnostic Trouble Code Failure Type";
BA_ "VNSigAllNodes" SG_ 1909 DTCI_DTCFailType_775 1;
BA_ "SignalType" SG_ 1909 DTCI_DTCNumber_775 "UNM";
BA_ "PacketOrder" SG_ 1909 DTCI_DTCNumber_775 10;
BA_ "SignalLongName" SG_ 1909 DTCI_DTCNumber_775 "Diagnostic Trouble Code Information Extended 775 : Diagnostic Trouble Code Number";
BA_ "VNSigAllNodes" SG_ 1909 DTCI_DTCNumber_775 1;
BA_ "SignalType" SG_ 1909 DTCI_DTCSource_775 "UNM";
BA_ "PacketOrder" SG_ 1909 DTCI_DTCSource_775 9;
BA_ "SignalLongName" SG_ 1909 DTCI_DTCSource_775 "Diagnostic Trouble Code Information Extended 775 : Diagnostic Trouble Code Source";
BA_ "VNSigAllNodes" SG_ 1909 DTCI_DTCSource_775 1;
BA_ "SignalType" SG_ 1909 DTCI_DTCTriggered_775 "BLN";
BA_ "PacketOrder" SG_ 1909 DTCI_DTCTriggered_775 8;
BA_ "SignalLongName" SG_ 1909 DTCI_DTCTriggered_775 "Diagnostic Trouble Code Information Extended 775 : Diagnostic Trouble Code Triggered";
BA_ "VNSigAllNodes" SG_ 1909 DTCI_DTCTriggered_775 1;
BA_ "SignalType" SG_ 1909 DTCIUnused7_775 "BLN";
BA_ "PacketOrder" SG_ 1909 DTCIUnused7_775 7;
BA_ "SignalLongName" SG_ 1909 DTCIUnused7_775 "Diagnostic Trouble Code Information Extended 775 : Unused 7";
BA_ "VNSigAllNodes" SG_ 1909 DTCIUnused7_775 1;
BA_ "SignalType" SG_ 1909 DTCIUnused6_775 "BLN";
BA_ "PacketOrder" SG_ 1909 DTCIUnused6_775 6;
BA_ "SignalLongName" SG_ 1909 DTCIUnused6_775 "Diagnostic Trouble Code Information Extended 775 : Unused 6";
BA_ "VNSigAllNodes" SG_ 1909 DTCIUnused6_775 1;
BA_ "SignalType" SG_ 1909 DTCIUnused5_775 "BLN";
BA_ "PacketOrder" SG_ 1909 DTCIUnused5_775 5;
BA_ "SignalLongName" SG_ 1909 DTCIUnused5_775 "Diagnostic Trouble Code Information Extended 775 : Unused 5";
BA_ "VNSigAllNodes" SG_ 1909 DTCIUnused5_775 1;
BA_ "SignalType" SG_ 1909 DTCIUnused4_775 "BLN";
BA_ "PacketOrder" SG_ 1909 DTCIUnused4_775 4;
BA_ "SignalLongName" SG_ 1909 DTCIUnused4_775 "Diagnostic Trouble Code Information Extended 775 : Unused 4";
BA_ "VNSigAllNodes" SG_ 1909 DTCIUnused4_775 1;
BA_ "SignalType" SG_ 1909 DTCIUnused3_775 "BLN";
BA_ "PacketOrder" SG_ 1909 DTCIUnused3_775 3;
BA_ "SignalLongName" SG_ 1909 DTCIUnused3_775 "Diagnostic Trouble Code Information Extended 775 : Unused 3";
BA_ "VNSigAllNodes" SG_ 1909 DTCIUnused3_775 1;
BA_ "SignalType" SG_ 1909 DTCIUnused2_775 "BLN";
BA_ "PacketOrder" SG_ 1909 DTCIUnused2_775 2;
BA_ "SignalLongName" SG_ 1909 DTCIUnused2_775 "Diagnostic Trouble Code Information Extended 775 : Unused 2";
BA_ "VNSigAllNodes" SG_ 1909 DTCIUnused2_775 1;
BA_ "SignalType" SG_ 1909 DTCIUnused1_775 "BLN";
BA_ "PacketOrder" SG_ 1909 DTCIUnused1_775 1;
BA_ "SignalLongName" SG_ 1909 DTCIUnused1_775 "Diagnostic Trouble Code Information Extended 775 : Unused 1";
BA_ "VNSigAllNodes" SG_ 1909 DTCIUnused1_775 1;
BA_ "SignalType" SG_ 1910 DTCI_DTCFaultType_776 "ENM";
BA_ "PacketOrder" SG_ 1910 DTCI_DTCFaultType_776 20;
BA_ "SignalLongName" SG_ 1910 DTCI_DTCFaultType_776 "Diagnostic Trouble Code Information Extended 776 : Diagnostic Trouble Code Fault Type";
BA_ "VNSigAllNodes" SG_ 1910 DTCI_DTCFaultType_776 1;
BA_ "SignalType" SG_ 1910 DTCI_CodeSupported_776 "BLN";
BA_ "PacketOrder" SG_ 1910 DTCI_CodeSupported_776 19;
BA_ "SignalLongName" SG_ 1910 DTCI_CodeSupported_776 "Diagnostic Trouble Code Information Extended 776 : Code Supported";
BA_ "VNSigAllNodes" SG_ 1910 DTCI_CodeSupported_776 1;
BA_ "SignalType" SG_ 1910 DTCI_CurrentStatus_776 "BLN";
BA_ "PacketOrder" SG_ 1910 DTCI_CurrentStatus_776 18;
BA_ "SignalLongName" SG_ 1910 DTCI_CurrentStatus_776 "Diagnostic Trouble Code Information Extended 776 : Current Status";
BA_ "VNSigAllNodes" SG_ 1910 DTCI_CurrentStatus_776 1;
BA_ "SignalType" SG_ 1910 DTCI_TstNPsdCdClrdSt_776 "BLN";
BA_ "PacketOrder" SG_ 1910 DTCI_TstNPsdCdClrdSt_776 17;
BA_ "SignalLongName" SG_ 1910 DTCI_TstNPsdCdClrdSt_776 "Diagnostic Trouble Code Information Extended 776 : Test Not Passed Since Code Cleared Status";
BA_ "VNSigAllNodes" SG_ 1910 DTCI_TstNPsdCdClrdSt_776 1;
BA_ "SignalType" SG_ 1910 DTCI_TstFldCdClrdStat_776 "BLN";
BA_ "PacketOrder" SG_ 1910 DTCI_TstFldCdClrdStat_776 16;
BA_ "SignalLongName" SG_ 1910 DTCI_TstFldCdClrdStat_776 "Diagnostic Trouble Code Information Extended 776 : Test Failed Since Code Cleared Status";
BA_ "VNSigAllNodes" SG_ 1910 DTCI_TstFldCdClrdStat_776 1;
BA_ "SignalType" SG_ 1910 DTCI_HistStat_776 "BLN";
BA_ "PacketOrder" SG_ 1910 DTCI_HistStat_776 15;
BA_ "SignalLongName" SG_ 1910 DTCI_HistStat_776 "Diagnostic Trouble Code Information Extended 776 : History Status";
BA_ "VNSigAllNodes" SG_ 1910 DTCI_HistStat_776 1;
BA_ "SignalType" SG_ 1910 DTCI_TstNPsdPwrUpSt_776 "BLN";
BA_ "PacketOrder" SG_ 1910 DTCI_TstNPsdPwrUpSt_776 14;
BA_ "SignalLongName" SG_ 1910 DTCI_TstNPsdPwrUpSt_776 "Diagnostic Trouble Code Information Extended 776 : Test Not Passed Since Power Up Status";
BA_ "VNSigAllNodes" SG_ 1910 DTCI_TstNPsdPwrUpSt_776 1;
BA_ "SignalType" SG_ 1910 DTCI_TstFldPwrUpSt_776 "BLN";
BA_ "PacketOrder" SG_ 1910 DTCI_TstFldPwrUpSt_776 13;
BA_ "SignalLongName" SG_ 1910 DTCI_TstFldPwrUpSt_776 "Diagnostic Trouble Code Information Extended 776 : Test Failed Since Power Up Status";
BA_ "VNSigAllNodes" SG_ 1910 DTCI_TstFldPwrUpSt_776 1;
BA_ "SignalType" SG_ 1910 DTCI_WrnIndRqdSt_776 "BLN";
BA_ "PacketOrder" SG_ 1910 DTCI_WrnIndRqdSt_776 12;
BA_ "SignalLongName" SG_ 1910 DTCI_WrnIndRqdSt_776 "Diagnostic Trouble Code Information Extended 776 : Warning Indicator Requested Status";
BA_ "VNSigAllNodes" SG_ 1910 DTCI_WrnIndRqdSt_776 1;
BA_ "SignalType" SG_ 1910 DTCI_DTCFailType_776 "UNM";
BA_ "PacketOrder" SG_ 1910 DTCI_DTCFailType_776 11;
BA_ "SignalLongName" SG_ 1910 DTCI_DTCFailType_776 "Diagnostic Trouble Code Information Extended 776 : Diagnostic Trouble Code Failure Type";
BA_ "VNSigAllNodes" SG_ 1910 DTCI_DTCFailType_776 1;
BA_ "SignalType" SG_ 1910 DTCI_DTCNumber_776 "UNM";
BA_ "PacketOrder" SG_ 1910 DTCI_DTCNumber_776 10;
BA_ "SignalLongName" SG_ 1910 DTCI_DTCNumber_776 "Diagnostic Trouble Code Information Extended 776 : Diagnostic Trouble Code Number";
BA_ "VNSigAllNodes" SG_ 1910 DTCI_DTCNumber_776 1;
BA_ "SignalType" SG_ 1910 DTCI_DTCSource_776 "UNM";
BA_ "PacketOrder" SG_ 1910 DTCI_DTCSource_776 9;
BA_ "SignalLongName" SG_ 1910 DTCI_DTCSource_776 "Diagnostic Trouble Code Information Extended 776 : Diagnostic Trouble Code Source";
BA_ "VNSigAllNodes" SG_ 1910 DTCI_DTCSource_776 1;
BA_ "SignalType" SG_ 1910 DTCI_DTCTriggered_776 "BLN";
BA_ "PacketOrder" SG_ 1910 DTCI_DTCTriggered_776 8;
BA_ "SignalLongName" SG_ 1910 DTCI_DTCTriggered_776 "Diagnostic Trouble Code Information Extended 776 : Diagnostic Trouble Code Triggered";
BA_ "VNSigAllNodes" SG_ 1910 DTCI_DTCTriggered_776 1;
BA_ "SignalType" SG_ 1910 DTCIUnused7_776 "BLN";
BA_ "PacketOrder" SG_ 1910 DTCIUnused7_776 7;
BA_ "SignalLongName" SG_ 1910 DTCIUnused7_776 "Diagnostic Trouble Code Information Extended 776 : Unused 7";
BA_ "VNSigAllNodes" SG_ 1910 DTCIUnused7_776 1;
BA_ "SignalType" SG_ 1910 DTCIUnused6_776 "BLN";
BA_ "PacketOrder" SG_ 1910 DTCIUnused6_776 6;
BA_ "SignalLongName" SG_ 1910 DTCIUnused6_776 "Diagnostic Trouble Code Information Extended 776 : Unused 6";
BA_ "VNSigAllNodes" SG_ 1910 DTCIUnused6_776 1;
BA_ "SignalType" SG_ 1910 DTCIUnused5_776 "BLN";
BA_ "PacketOrder" SG_ 1910 DTCIUnused5_776 5;
BA_ "SignalLongName" SG_ 1910 DTCIUnused5_776 "Diagnostic Trouble Code Information Extended 776 : Unused 5";
BA_ "VNSigAllNodes" SG_ 1910 DTCIUnused5_776 1;
BA_ "SignalType" SG_ 1910 DTCIUnused4_776 "BLN";
BA_ "PacketOrder" SG_ 1910 DTCIUnused4_776 4;
BA_ "SignalLongName" SG_ 1910 DTCIUnused4_776 "Diagnostic Trouble Code Information Extended 776 : Unused 4";
BA_ "VNSigAllNodes" SG_ 1910 DTCIUnused4_776 1;
BA_ "SignalType" SG_ 1910 DTCIUnused3_776 "BLN";
BA_ "PacketOrder" SG_ 1910 DTCIUnused3_776 3;
BA_ "SignalLongName" SG_ 1910 DTCIUnused3_776 "Diagnostic Trouble Code Information Extended 776 : Unused 3";
BA_ "VNSigAllNodes" SG_ 1910 DTCIUnused3_776 1;
BA_ "SignalType" SG_ 1910 DTCIUnused2_776 "BLN";
BA_ "PacketOrder" SG_ 1910 DTCIUnused2_776 2;
BA_ "SignalLongName" SG_ 1910 DTCIUnused2_776 "Diagnostic Trouble Code Information Extended 776 : Unused 2";
BA_ "VNSigAllNodes" SG_ 1910 DTCIUnused2_776 1;
BA_ "SignalType" SG_ 1910 DTCIUnused1_776 "BLN";
BA_ "PacketOrder" SG_ 1910 DTCIUnused1_776 1;
BA_ "SignalLongName" SG_ 1910 DTCIUnused1_776 "Diagnostic Trouble Code Information Extended 776 : Unused 1";
BA_ "VNSigAllNodes" SG_ 1910 DTCIUnused1_776 1;
BA_ "SignalType" SG_ 1912 DTCI_DTCFaultType_778 "ENM";
BA_ "PacketOrder" SG_ 1912 DTCI_DTCFaultType_778 20;
BA_ "SignalLongName" SG_ 1912 DTCI_DTCFaultType_778 "Diagnostic Trouble Code Information Extended 778 : Diagnostic Trouble Code Fault Type";
BA_ "VNSigAllNodes" SG_ 1912 DTCI_DTCFaultType_778 1;
BA_ "SignalType" SG_ 1912 DTCI_CodeSupported_778 "BLN";
BA_ "PacketOrder" SG_ 1912 DTCI_CodeSupported_778 19;
BA_ "SignalLongName" SG_ 1912 DTCI_CodeSupported_778 "Diagnostic Trouble Code Information Extended 778 : Code Supported";
BA_ "VNSigAllNodes" SG_ 1912 DTCI_CodeSupported_778 1;
BA_ "SignalType" SG_ 1912 DTCI_CurrentStatus_778 "BLN";
BA_ "PacketOrder" SG_ 1912 DTCI_CurrentStatus_778 18;
BA_ "SignalLongName" SG_ 1912 DTCI_CurrentStatus_778 "Diagnostic Trouble Code Information Extended 778 : Current Status";
BA_ "VNSigAllNodes" SG_ 1912 DTCI_CurrentStatus_778 1;
BA_ "SignalType" SG_ 1912 DTCI_TstNPsdCdClrdSt_778 "BLN";
BA_ "PacketOrder" SG_ 1912 DTCI_TstNPsdCdClrdSt_778 17;
BA_ "SignalLongName" SG_ 1912 DTCI_TstNPsdCdClrdSt_778 "Diagnostic Trouble Code Information Extended 778 : Test Not Passed Since Code Cleared Status";
BA_ "VNSigAllNodes" SG_ 1912 DTCI_TstNPsdCdClrdSt_778 1;
BA_ "SignalType" SG_ 1912 DTCI_TstFldCdClrdStat_778 "BLN";
BA_ "PacketOrder" SG_ 1912 DTCI_TstFldCdClrdStat_778 16;
BA_ "SignalLongName" SG_ 1912 DTCI_TstFldCdClrdStat_778 "Diagnostic Trouble Code Information Extended 778 : Test Failed Since Code Cleared Status";
BA_ "VNSigAllNodes" SG_ 1912 DTCI_TstFldCdClrdStat_778 1;
BA_ "SignalType" SG_ 1912 DTCI_HistStat_778 "BLN";
BA_ "PacketOrder" SG_ 1912 DTCI_HistStat_778 15;
BA_ "SignalLongName" SG_ 1912 DTCI_HistStat_778 "Diagnostic Trouble Code Information Extended 778 : History Status";
BA_ "VNSigAllNodes" SG_ 1912 DTCI_HistStat_778 1;
BA_ "SignalType" SG_ 1912 DTCI_TstNPsdPwrUpSt_778 "BLN";
BA_ "PacketOrder" SG_ 1912 DTCI_TstNPsdPwrUpSt_778 14;
BA_ "SignalLongName" SG_ 1912 DTCI_TstNPsdPwrUpSt_778 "Diagnostic Trouble Code Information Extended 778 : Test Not Passed Since Power Up Status";
BA_ "VNSigAllNodes" SG_ 1912 DTCI_TstNPsdPwrUpSt_778 1;
BA_ "SignalType" SG_ 1912 DTCI_TstFldPwrUpSt_778 "BLN";
BA_ "PacketOrder" SG_ 1912 DTCI_TstFldPwrUpSt_778 13;
BA_ "SignalLongName" SG_ 1912 DTCI_TstFldPwrUpSt_778 "Diagnostic Trouble Code Information Extended 778 : Test Failed Since Power Up Status";
BA_ "VNSigAllNodes" SG_ 1912 DTCI_TstFldPwrUpSt_778 1;
BA_ "SignalType" SG_ 1912 DTCI_WrnIndRqdSt_778 "BLN";
BA_ "PacketOrder" SG_ 1912 DTCI_WrnIndRqdSt_778 12;
BA_ "SignalLongName" SG_ 1912 DTCI_WrnIndRqdSt_778 "Diagnostic Trouble Code Information Extended 778 : Warning Indicator Requested Status";
BA_ "VNSigAllNodes" SG_ 1912 DTCI_WrnIndRqdSt_778 1;
BA_ "SignalType" SG_ 1912 DTCI_DTCFailType_778 "UNM";
BA_ "PacketOrder" SG_ 1912 DTCI_DTCFailType_778 11;
BA_ "SignalLongName" SG_ 1912 DTCI_DTCFailType_778 "Diagnostic Trouble Code Information Extended 778 : Diagnostic Trouble Code Failure Type";
BA_ "VNSigAllNodes" SG_ 1912 DTCI_DTCFailType_778 1;
BA_ "SignalType" SG_ 1912 DTCI_DTCNumber_778 "UNM";
BA_ "PacketOrder" SG_ 1912 DTCI_DTCNumber_778 10;
BA_ "SignalLongName" SG_ 1912 DTCI_DTCNumber_778 "Diagnostic Trouble Code Information Extended 778 : Diagnostic Trouble Code Number";
BA_ "VNSigAllNodes" SG_ 1912 DTCI_DTCNumber_778 1;
BA_ "SignalType" SG_ 1912 DTCI_DTCSource_778 "UNM";
BA_ "PacketOrder" SG_ 1912 DTCI_DTCSource_778 9;
BA_ "SignalLongName" SG_ 1912 DTCI_DTCSource_778 "Diagnostic Trouble Code Information Extended 778 : Diagnostic Trouble Code Source";
BA_ "VNSigAllNodes" SG_ 1912 DTCI_DTCSource_778 1;
BA_ "SignalType" SG_ 1912 DTCI_DTCTriggered_778 "BLN";
BA_ "PacketOrder" SG_ 1912 DTCI_DTCTriggered_778 8;
BA_ "SignalLongName" SG_ 1912 DTCI_DTCTriggered_778 "Diagnostic Trouble Code Information Extended 778 : Diagnostic Trouble Code Triggered";
BA_ "VNSigAllNodes" SG_ 1912 DTCI_DTCTriggered_778 1;
BA_ "SignalType" SG_ 1912 DTCIUnused7_778 "BLN";
BA_ "PacketOrder" SG_ 1912 DTCIUnused7_778 7;
BA_ "SignalLongName" SG_ 1912 DTCIUnused7_778 "Diagnostic Trouble Code Information Extended 778 : Unused 7";
BA_ "VNSigAllNodes" SG_ 1912 DTCIUnused7_778 1;
BA_ "SignalType" SG_ 1912 DTCIUnused6_778 "BLN";
BA_ "PacketOrder" SG_ 1912 DTCIUnused6_778 6;
BA_ "SignalLongName" SG_ 1912 DTCIUnused6_778 "Diagnostic Trouble Code Information Extended 778 : Unused 6";
BA_ "VNSigAllNodes" SG_ 1912 DTCIUnused6_778 1;
BA_ "SignalType" SG_ 1912 DTCIUnused5_778 "BLN";
BA_ "PacketOrder" SG_ 1912 DTCIUnused5_778 5;
BA_ "SignalLongName" SG_ 1912 DTCIUnused5_778 "Diagnostic Trouble Code Information Extended 778 : Unused 5";
BA_ "VNSigAllNodes" SG_ 1912 DTCIUnused5_778 1;
BA_ "SignalType" SG_ 1912 DTCIUnused4_778 "BLN";
BA_ "PacketOrder" SG_ 1912 DTCIUnused4_778 4;
BA_ "SignalLongName" SG_ 1912 DTCIUnused4_778 "Diagnostic Trouble Code Information Extended 778 : Unused 4";
BA_ "VNSigAllNodes" SG_ 1912 DTCIUnused4_778 1;
BA_ "SignalType" SG_ 1912 DTCIUnused3_778 "BLN";
BA_ "PacketOrder" SG_ 1912 DTCIUnused3_778 3;
BA_ "SignalLongName" SG_ 1912 DTCIUnused3_778 "Diagnostic Trouble Code Information Extended 778 : Unused 3";
BA_ "VNSigAllNodes" SG_ 1912 DTCIUnused3_778 1;
BA_ "SignalType" SG_ 1912 DTCIUnused2_778 "BLN";
BA_ "PacketOrder" SG_ 1912 DTCIUnused2_778 2;
BA_ "SignalLongName" SG_ 1912 DTCIUnused2_778 "Diagnostic Trouble Code Information Extended 778 : Unused 2";
BA_ "VNSigAllNodes" SG_ 1912 DTCIUnused2_778 1;
BA_ "SignalType" SG_ 1912 DTCIUnused1_778 "BLN";
BA_ "PacketOrder" SG_ 1912 DTCIUnused1_778 1;
BA_ "SignalLongName" SG_ 1912 DTCIUnused1_778 "Diagnostic Trouble Code Information Extended 778 : Unused 1";
BA_ "VNSigAllNodes" SG_ 1912 DTCIUnused1_778 1;
BA_ "SignalType" SG_ 1913 DTCI_DTCFaultType_779 "ENM";
BA_ "PacketOrder" SG_ 1913 DTCI_DTCFaultType_779 20;
BA_ "SignalLongName" SG_ 1913 DTCI_DTCFaultType_779 "Diagnostic Trouble Code Information Extended 779 : Diagnostic Trouble Code Fault Type";
BA_ "VNSigAllNodes" SG_ 1913 DTCI_DTCFaultType_779 1;
BA_ "SignalType" SG_ 1913 DTCI_CodeSupported_779 "BLN";
BA_ "PacketOrder" SG_ 1913 DTCI_CodeSupported_779 19;
BA_ "SignalLongName" SG_ 1913 DTCI_CodeSupported_779 "Diagnostic Trouble Code Information Extended 779 : Code Supported";
BA_ "VNSigAllNodes" SG_ 1913 DTCI_CodeSupported_779 1;
BA_ "SignalType" SG_ 1913 DTCI_CurrentStatus_779 "BLN";
BA_ "PacketOrder" SG_ 1913 DTCI_CurrentStatus_779 18;
BA_ "SignalLongName" SG_ 1913 DTCI_CurrentStatus_779 "Diagnostic Trouble Code Information Extended 779 : Current Status";
BA_ "VNSigAllNodes" SG_ 1913 DTCI_CurrentStatus_779 1;
BA_ "SignalType" SG_ 1913 DTCI_TstNPsdCdClrdSt_779 "BLN";
BA_ "PacketOrder" SG_ 1913 DTCI_TstNPsdCdClrdSt_779 17;
BA_ "SignalLongName" SG_ 1913 DTCI_TstNPsdCdClrdSt_779 "Diagnostic Trouble Code Information Extended 779 : Test Not Passed Since Code Cleared Status";
BA_ "VNSigAllNodes" SG_ 1913 DTCI_TstNPsdCdClrdSt_779 1;
BA_ "SignalType" SG_ 1913 DTCI_TstFldCdClrdStat_779 "BLN";
BA_ "PacketOrder" SG_ 1913 DTCI_TstFldCdClrdStat_779 16;
BA_ "SignalLongName" SG_ 1913 DTCI_TstFldCdClrdStat_779 "Diagnostic Trouble Code Information Extended 779 : Test Failed Since Code Cleared Status";
BA_ "VNSigAllNodes" SG_ 1913 DTCI_TstFldCdClrdStat_779 1;
BA_ "SignalType" SG_ 1913 DTCI_HistStat_779 "BLN";
BA_ "PacketOrder" SG_ 1913 DTCI_HistStat_779 15;
BA_ "SignalLongName" SG_ 1913 DTCI_HistStat_779 "Diagnostic Trouble Code Information Extended 779 : History Status";
BA_ "VNSigAllNodes" SG_ 1913 DTCI_HistStat_779 1;
BA_ "SignalType" SG_ 1913 DTCI_TstNPsdPwrUpSt_779 "BLN";
BA_ "PacketOrder" SG_ 1913 DTCI_TstNPsdPwrUpSt_779 14;
BA_ "SignalLongName" SG_ 1913 DTCI_TstNPsdPwrUpSt_779 "Diagnostic Trouble Code Information Extended 779 : Test Not Passed Since Power Up Status";
BA_ "VNSigAllNodes" SG_ 1913 DTCI_TstNPsdPwrUpSt_779 1;
BA_ "SignalType" SG_ 1913 DTCI_TstFldPwrUpSt_779 "BLN";
BA_ "PacketOrder" SG_ 1913 DTCI_TstFldPwrUpSt_779 13;
BA_ "SignalLongName" SG_ 1913 DTCI_TstFldPwrUpSt_779 "Diagnostic Trouble Code Information Extended 779 : Test Failed Since Power Up Status";
BA_ "VNSigAllNodes" SG_ 1913 DTCI_TstFldPwrUpSt_779 1;
BA_ "SignalType" SG_ 1913 DTCI_WrnIndRqdSt_779 "BLN";
BA_ "PacketOrder" SG_ 1913 DTCI_WrnIndRqdSt_779 12;
BA_ "SignalLongName" SG_ 1913 DTCI_WrnIndRqdSt_779 "Diagnostic Trouble Code Information Extended 779 : Warning Indicator Requested Status";
BA_ "VNSigAllNodes" SG_ 1913 DTCI_WrnIndRqdSt_779 1;
BA_ "SignalType" SG_ 1913 DTCI_DTCFailType_779 "UNM";
BA_ "PacketOrder" SG_ 1913 DTCI_DTCFailType_779 11;
BA_ "SignalLongName" SG_ 1913 DTCI_DTCFailType_779 "Diagnostic Trouble Code Information Extended 779 : Diagnostic Trouble Code Failure Type";
BA_ "VNSigAllNodes" SG_ 1913 DTCI_DTCFailType_779 1;
BA_ "SignalType" SG_ 1913 DTCI_DTCNumber_779 "UNM";
BA_ "PacketOrder" SG_ 1913 DTCI_DTCNumber_779 10;
BA_ "SignalLongName" SG_ 1913 DTCI_DTCNumber_779 "Diagnostic Trouble Code Information Extended 779 : Diagnostic Trouble Code Number";
BA_ "VNSigAllNodes" SG_ 1913 DTCI_DTCNumber_779 1;
BA_ "SignalType" SG_ 1913 DTCI_DTCSource_779 "UNM";
BA_ "PacketOrder" SG_ 1913 DTCI_DTCSource_779 9;
BA_ "SignalLongName" SG_ 1913 DTCI_DTCSource_779 "Diagnostic Trouble Code Information Extended 779 : Diagnostic Trouble Code Source";
BA_ "VNSigAllNodes" SG_ 1913 DTCI_DTCSource_779 1;
BA_ "SignalType" SG_ 1913 DTCI_DTCTriggered_779 "BLN";
BA_ "PacketOrder" SG_ 1913 DTCI_DTCTriggered_779 8;
BA_ "SignalLongName" SG_ 1913 DTCI_DTCTriggered_779 "Diagnostic Trouble Code Information Extended 779 : Diagnostic Trouble Code Triggered";
BA_ "VNSigAllNodes" SG_ 1913 DTCI_DTCTriggered_779 1;
BA_ "SignalType" SG_ 1913 DTCIUnused7_779 "BLN";
BA_ "PacketOrder" SG_ 1913 DTCIUnused7_779 7;
BA_ "SignalLongName" SG_ 1913 DTCIUnused7_779 "Diagnostic Trouble Code Information Extended 779 : Unused 7";
BA_ "VNSigAllNodes" SG_ 1913 DTCIUnused7_779 1;
BA_ "SignalType" SG_ 1913 DTCIUnused6_779 "BLN";
BA_ "PacketOrder" SG_ 1913 DTCIUnused6_779 6;
BA_ "SignalLongName" SG_ 1913 DTCIUnused6_779 "Diagnostic Trouble Code Information Extended 779 : Unused 6";
BA_ "VNSigAllNodes" SG_ 1913 DTCIUnused6_779 1;
BA_ "SignalType" SG_ 1913 DTCIUnused5_779 "BLN";
BA_ "PacketOrder" SG_ 1913 DTCIUnused5_779 5;
BA_ "SignalLongName" SG_ 1913 DTCIUnused5_779 "Diagnostic Trouble Code Information Extended 779 : Unused 5";
BA_ "VNSigAllNodes" SG_ 1913 DTCIUnused5_779 1;
BA_ "SignalType" SG_ 1913 DTCIUnused4_779 "BLN";
BA_ "PacketOrder" SG_ 1913 DTCIUnused4_779 4;
BA_ "SignalLongName" SG_ 1913 DTCIUnused4_779 "Diagnostic Trouble Code Information Extended 779 : Unused 4";
BA_ "VNSigAllNodes" SG_ 1913 DTCIUnused4_779 1;
BA_ "SignalType" SG_ 1913 DTCIUnused3_779 "BLN";
BA_ "PacketOrder" SG_ 1913 DTCIUnused3_779 3;
BA_ "SignalLongName" SG_ 1913 DTCIUnused3_779 "Diagnostic Trouble Code Information Extended 779 : Unused 3";
BA_ "VNSigAllNodes" SG_ 1913 DTCIUnused3_779 1;
BA_ "SignalType" SG_ 1913 DTCIUnused2_779 "BLN";
BA_ "PacketOrder" SG_ 1913 DTCIUnused2_779 2;
BA_ "SignalLongName" SG_ 1913 DTCIUnused2_779 "Diagnostic Trouble Code Information Extended 779 : Unused 2";
BA_ "VNSigAllNodes" SG_ 1913 DTCIUnused2_779 1;
BA_ "SignalType" SG_ 1913 DTCIUnused1_779 "BLN";
BA_ "PacketOrder" SG_ 1913 DTCIUnused1_779 1;
BA_ "SignalLongName" SG_ 1913 DTCIUnused1_779 "Diagnostic Trouble Code Information Extended 779 : Unused 1";
BA_ "VNSigAllNodes" SG_ 1913 DTCIUnused1_779 1;
BA_ "SignalType" SG_ 1916 DTCI_DTCFaultType_77C "ENM";
BA_ "PacketOrder" SG_ 1916 DTCI_DTCFaultType_77C 20;
BA_ "SignalLongName" SG_ 1916 DTCI_DTCFaultType_77C "Diagnostic Trouble Code Information Extended 77C : Diagnostic Trouble Code Fault Type";
BA_ "VNSigAllNodes" SG_ 1916 DTCI_DTCFaultType_77C 1;
BA_ "SignalType" SG_ 1916 DTCI_CodeSupported_77C "BLN";
BA_ "PacketOrder" SG_ 1916 DTCI_CodeSupported_77C 19;
BA_ "SignalLongName" SG_ 1916 DTCI_CodeSupported_77C "Diagnostic Trouble Code Information Extended 77C : Code Supported";
BA_ "VNSigAllNodes" SG_ 1916 DTCI_CodeSupported_77C 1;
BA_ "SignalType" SG_ 1916 DTCI_CurrentStatus_77C "BLN";
BA_ "PacketOrder" SG_ 1916 DTCI_CurrentStatus_77C 18;
BA_ "SignalLongName" SG_ 1916 DTCI_CurrentStatus_77C "Diagnostic Trouble Code Information Extended 77C : Current Status";
BA_ "VNSigAllNodes" SG_ 1916 DTCI_CurrentStatus_77C 1;
BA_ "SignalType" SG_ 1916 DTCI_TstNPsdCdClrdSt_77C "BLN";
BA_ "PacketOrder" SG_ 1916 DTCI_TstNPsdCdClrdSt_77C 17;
BA_ "SignalLongName" SG_ 1916 DTCI_TstNPsdCdClrdSt_77C "Diagnostic Trouble Code Information Extended 77C : Test Not Passed Since Code Cleared Status";
BA_ "VNSigAllNodes" SG_ 1916 DTCI_TstNPsdCdClrdSt_77C 1;
BA_ "SignalType" SG_ 1916 DTCI_TstFldCdClrdStat_77C "BLN";
BA_ "PacketOrder" SG_ 1916 DTCI_TstFldCdClrdStat_77C 16;
BA_ "SignalLongName" SG_ 1916 DTCI_TstFldCdClrdStat_77C "Diagnostic Trouble Code Information Extended 77C : Test Failed Since Code Cleared Status";
BA_ "VNSigAllNodes" SG_ 1916 DTCI_TstFldCdClrdStat_77C 1;
BA_ "SignalType" SG_ 1916 DTCI_HistStat_77C "BLN";
BA_ "PacketOrder" SG_ 1916 DTCI_HistStat_77C 15;
BA_ "SignalLongName" SG_ 1916 DTCI_HistStat_77C "Diagnostic Trouble Code Information Extended 77C : History Status";
BA_ "VNSigAllNodes" SG_ 1916 DTCI_HistStat_77C 1;
BA_ "SignalType" SG_ 1916 DTCI_TstNPsdPwrUpSt_77C "BLN";
BA_ "PacketOrder" SG_ 1916 DTCI_TstNPsdPwrUpSt_77C 14;
BA_ "SignalLongName" SG_ 1916 DTCI_TstNPsdPwrUpSt_77C "Diagnostic Trouble Code Information Extended 77C : Test Not Passed Since Power Up Status";
BA_ "VNSigAllNodes" SG_ 1916 DTCI_TstNPsdPwrUpSt_77C 1;
BA_ "SignalType" SG_ 1916 DTCI_TstFldPwrUpSt_77C "BLN";
BA_ "PacketOrder" SG_ 1916 DTCI_TstFldPwrUpSt_77C 13;
BA_ "SignalLongName" SG_ 1916 DTCI_TstFldPwrUpSt_77C "Diagnostic Trouble Code Information Extended 77C : Test Failed Since Power Up Status";
BA_ "VNSigAllNodes" SG_ 1916 DTCI_TstFldPwrUpSt_77C 1;
BA_ "SignalType" SG_ 1916 DTCI_WrnIndRqdSt_77C "BLN";
BA_ "PacketOrder" SG_ 1916 DTCI_WrnIndRqdSt_77C 12;
BA_ "SignalLongName" SG_ 1916 DTCI_WrnIndRqdSt_77C "Diagnostic Trouble Code Information Extended 77C : Warning Indicator Requested Status";
BA_ "VNSigAllNodes" SG_ 1916 DTCI_WrnIndRqdSt_77C 1;
BA_ "SignalType" SG_ 1916 DTCI_DTCFailType_77C "UNM";
BA_ "PacketOrder" SG_ 1916 DTCI_DTCFailType_77C 11;
BA_ "SignalLongName" SG_ 1916 DTCI_DTCFailType_77C "Diagnostic Trouble Code Information Extended 77C : Diagnostic Trouble Code Failure Type";
BA_ "VNSigAllNodes" SG_ 1916 DTCI_DTCFailType_77C 1;
BA_ "SignalType" SG_ 1916 DTCI_DTCNumber_77C "UNM";
BA_ "PacketOrder" SG_ 1916 DTCI_DTCNumber_77C 10;
BA_ "SignalLongName" SG_ 1916 DTCI_DTCNumber_77C "Diagnostic Trouble Code Information Extended 77C : Diagnostic Trouble Code Number";
BA_ "VNSigAllNodes" SG_ 1916 DTCI_DTCNumber_77C 1;
BA_ "SignalType" SG_ 1916 DTCI_DTCSource_77C "UNM";
BA_ "PacketOrder" SG_ 1916 DTCI_DTCSource_77C 9;
BA_ "SignalLongName" SG_ 1916 DTCI_DTCSource_77C "Diagnostic Trouble Code Information Extended 77C : Diagnostic Trouble Code Source";
BA_ "VNSigAllNodes" SG_ 1916 DTCI_DTCSource_77C 1;
BA_ "SignalType" SG_ 1916 DTCI_DTCTriggered_77C "BLN";
BA_ "PacketOrder" SG_ 1916 DTCI_DTCTriggered_77C 8;
BA_ "SignalLongName" SG_ 1916 DTCI_DTCTriggered_77C "Diagnostic Trouble Code Information Extended 77C : Diagnostic Trouble Code Triggered";
BA_ "VNSigAllNodes" SG_ 1916 DTCI_DTCTriggered_77C 1;
BA_ "SignalType" SG_ 1916 DTCIUnused7_77C "BLN";
BA_ "PacketOrder" SG_ 1916 DTCIUnused7_77C 7;
BA_ "SignalLongName" SG_ 1916 DTCIUnused7_77C "Diagnostic Trouble Code Information Extended 77C : Unused 7";
BA_ "VNSigAllNodes" SG_ 1916 DTCIUnused7_77C 1;
BA_ "SignalType" SG_ 1916 DTCIUnused6_77C "BLN";
BA_ "PacketOrder" SG_ 1916 DTCIUnused6_77C 6;
BA_ "SignalLongName" SG_ 1916 DTCIUnused6_77C "Diagnostic Trouble Code Information Extended 77C : Unused 6";
BA_ "VNSigAllNodes" SG_ 1916 DTCIUnused6_77C 1;
BA_ "SignalType" SG_ 1916 DTCIUnused5_77C "BLN";
BA_ "PacketOrder" SG_ 1916 DTCIUnused5_77C 5;
BA_ "SignalLongName" SG_ 1916 DTCIUnused5_77C "Diagnostic Trouble Code Information Extended 77C : Unused 5";
BA_ "VNSigAllNodes" SG_ 1916 DTCIUnused5_77C 1;
BA_ "SignalType" SG_ 1916 DTCIUnused4_77C "BLN";
BA_ "PacketOrder" SG_ 1916 DTCIUnused4_77C 4;
BA_ "SignalLongName" SG_ 1916 DTCIUnused4_77C "Diagnostic Trouble Code Information Extended 77C : Unused 4";
BA_ "VNSigAllNodes" SG_ 1916 DTCIUnused4_77C 1;
BA_ "SignalType" SG_ 1916 DTCIUnused3_77C "BLN";
BA_ "PacketOrder" SG_ 1916 DTCIUnused3_77C 3;
BA_ "SignalLongName" SG_ 1916 DTCIUnused3_77C "Diagnostic Trouble Code Information Extended 77C : Unused 3";
BA_ "VNSigAllNodes" SG_ 1916 DTCIUnused3_77C 1;
BA_ "SignalType" SG_ 1916 DTCIUnused2_77C "BLN";
BA_ "PacketOrder" SG_ 1916 DTCIUnused2_77C 2;
BA_ "SignalLongName" SG_ 1916 DTCIUnused2_77C "Diagnostic Trouble Code Information Extended 77C : Unused 2";
BA_ "VNSigAllNodes" SG_ 1916 DTCIUnused2_77C 1;
BA_ "SignalType" SG_ 1916 DTCIUnused1_77C "BLN";
BA_ "PacketOrder" SG_ 1916 DTCIUnused1_77C 1;
BA_ "SignalLongName" SG_ 1916 DTCIUnused1_77C "Diagnostic Trouble Code Information Extended 77C : Unused 1";
BA_ "VNSigAllNodes" SG_ 1916 DTCIUnused1_77C 1;
BA_ "SignalType" SG_ 1917 DTCI_DTCFaultType_77D "ENM";
BA_ "PacketOrder" SG_ 1917 DTCI_DTCFaultType_77D 20;
BA_ "SignalLongName" SG_ 1917 DTCI_DTCFaultType_77D "Diagnostic Trouble Code Information Extended 77D : Diagnostic Trouble Code Fault Type";
BA_ "VNSigAllNodes" SG_ 1917 DTCI_DTCFaultType_77D 1;
BA_ "SignalType" SG_ 1917 DTCI_CodeSupported_77D "BLN";
BA_ "PacketOrder" SG_ 1917 DTCI_CodeSupported_77D 19;
BA_ "SignalLongName" SG_ 1917 DTCI_CodeSupported_77D "Diagnostic Trouble Code Information Extended 77D : Code Supported";
BA_ "VNSigAllNodes" SG_ 1917 DTCI_CodeSupported_77D 1;
BA_ "SignalType" SG_ 1917 DTCI_CurrentStatus_77D "BLN";
BA_ "PacketOrder" SG_ 1917 DTCI_CurrentStatus_77D 18;
BA_ "SignalLongName" SG_ 1917 DTCI_CurrentStatus_77D "Diagnostic Trouble Code Information Extended 77D : Current Status";
BA_ "VNSigAllNodes" SG_ 1917 DTCI_CurrentStatus_77D 1;
BA_ "SignalType" SG_ 1917 DTCI_TstNPsdCdClrdSt_77D "BLN";
BA_ "PacketOrder" SG_ 1917 DTCI_TstNPsdCdClrdSt_77D 17;
BA_ "SignalLongName" SG_ 1917 DTCI_TstNPsdCdClrdSt_77D "Diagnostic Trouble Code Information Extended 77D : Test Not Passed Since Code Cleared Status";
BA_ "VNSigAllNodes" SG_ 1917 DTCI_TstNPsdCdClrdSt_77D 1;
BA_ "SignalType" SG_ 1917 DTCI_TstFldCdClrdStat_77D "BLN";
BA_ "PacketOrder" SG_ 1917 DTCI_TstFldCdClrdStat_77D 16;
BA_ "SignalLongName" SG_ 1917 DTCI_TstFldCdClrdStat_77D "Diagnostic Trouble Code Information Extended 77D : Test Failed Since Code Cleared Status";
BA_ "VNSigAllNodes" SG_ 1917 DTCI_TstFldCdClrdStat_77D 1;
BA_ "SignalType" SG_ 1917 DTCI_HistStat_77D "BLN";
BA_ "PacketOrder" SG_ 1917 DTCI_HistStat_77D 15;
BA_ "SignalLongName" SG_ 1917 DTCI_HistStat_77D "Diagnostic Trouble Code Information Extended 77D : History Status";
BA_ "VNSigAllNodes" SG_ 1917 DTCI_HistStat_77D 1;
BA_ "SignalType" SG_ 1917 DTCI_TstNPsdPwrUpSt_77D "BLN";
BA_ "PacketOrder" SG_ 1917 DTCI_TstNPsdPwrUpSt_77D 14;
BA_ "SignalLongName" SG_ 1917 DTCI_TstNPsdPwrUpSt_77D "Diagnostic Trouble Code Information Extended 77D : Test Not Passed Since Power Up Status";
BA_ "VNSigAllNodes" SG_ 1917 DTCI_TstNPsdPwrUpSt_77D 1;
BA_ "SignalType" SG_ 1917 DTCI_TstFldPwrUpSt_77D "BLN";
BA_ "PacketOrder" SG_ 1917 DTCI_TstFldPwrUpSt_77D 13;
BA_ "SignalLongName" SG_ 1917 DTCI_TstFldPwrUpSt_77D "Diagnostic Trouble Code Information Extended 77D : Test Failed Since Power Up Status";
BA_ "VNSigAllNodes" SG_ 1917 DTCI_TstFldPwrUpSt_77D 1;
BA_ "SignalType" SG_ 1917 DTCI_WrnIndRqdSt_77D "BLN";
BA_ "PacketOrder" SG_ 1917 DTCI_WrnIndRqdSt_77D 12;
BA_ "SignalLongName" SG_ 1917 DTCI_WrnIndRqdSt_77D "Diagnostic Trouble Code Information Extended 77D : Warning Indicator Requested Status";
BA_ "VNSigAllNodes" SG_ 1917 DTCI_WrnIndRqdSt_77D 1;
BA_ "SignalType" SG_ 1917 DTCI_DTCFailType_77D "UNM";
BA_ "PacketOrder" SG_ 1917 DTCI_DTCFailType_77D 11;
BA_ "SignalLongName" SG_ 1917 DTCI_DTCFailType_77D "Diagnostic Trouble Code Information Extended 77D : Diagnostic Trouble Code Failure Type";
BA_ "VNSigAllNodes" SG_ 1917 DTCI_DTCFailType_77D 1;
BA_ "SignalType" SG_ 1917 DTCI_DTCNumber_77D "UNM";
BA_ "PacketOrder" SG_ 1917 DTCI_DTCNumber_77D 10;
BA_ "SignalLongName" SG_ 1917 DTCI_DTCNumber_77D "Diagnostic Trouble Code Information Extended 77D : Diagnostic Trouble Code Number";
BA_ "VNSigAllNodes" SG_ 1917 DTCI_DTCNumber_77D 1;
BA_ "SignalType" SG_ 1917 DTCI_DTCSource_77D "UNM";
BA_ "PacketOrder" SG_ 1917 DTCI_DTCSource_77D 9;
BA_ "SignalLongName" SG_ 1917 DTCI_DTCSource_77D "Diagnostic Trouble Code Information Extended 77D : Diagnostic Trouble Code Source";
BA_ "VNSigAllNodes" SG_ 1917 DTCI_DTCSource_77D 1;
BA_ "SignalType" SG_ 1917 DTCI_DTCTriggered_77D "BLN";
BA_ "PacketOrder" SG_ 1917 DTCI_DTCTriggered_77D 8;
BA_ "SignalLongName" SG_ 1917 DTCI_DTCTriggered_77D "Diagnostic Trouble Code Information Extended 77D : Diagnostic Trouble Code Triggered";
BA_ "VNSigAllNodes" SG_ 1917 DTCI_DTCTriggered_77D 1;
BA_ "SignalType" SG_ 1917 DTCIUnused7_77D "BLN";
BA_ "PacketOrder" SG_ 1917 DTCIUnused7_77D 7;
BA_ "SignalLongName" SG_ 1917 DTCIUnused7_77D "Diagnostic Trouble Code Information Extended 77D : Unused 7";
BA_ "VNSigAllNodes" SG_ 1917 DTCIUnused7_77D 1;
BA_ "SignalType" SG_ 1917 DTCIUnused6_77D "BLN";
BA_ "PacketOrder" SG_ 1917 DTCIUnused6_77D 6;
BA_ "SignalLongName" SG_ 1917 DTCIUnused6_77D "Diagnostic Trouble Code Information Extended 77D : Unused 6";
BA_ "VNSigAllNodes" SG_ 1917 DTCIUnused6_77D 1;
BA_ "SignalType" SG_ 1917 DTCIUnused5_77D "BLN";
BA_ "PacketOrder" SG_ 1917 DTCIUnused5_77D 5;
BA_ "SignalLongName" SG_ 1917 DTCIUnused5_77D "Diagnostic Trouble Code Information Extended 77D : Unused 5";
BA_ "VNSigAllNodes" SG_ 1917 DTCIUnused5_77D 1;
BA_ "SignalType" SG_ 1917 DTCIUnused4_77D "BLN";
BA_ "PacketOrder" SG_ 1917 DTCIUnused4_77D 4;
BA_ "SignalLongName" SG_ 1917 DTCIUnused4_77D "Diagnostic Trouble Code Information Extended 77D : Unused 4";
BA_ "VNSigAllNodes" SG_ 1917 DTCIUnused4_77D 1;
BA_ "SignalType" SG_ 1917 DTCIUnused3_77D "BLN";
BA_ "PacketOrder" SG_ 1917 DTCIUnused3_77D 3;
BA_ "SignalLongName" SG_ 1917 DTCIUnused3_77D "Diagnostic Trouble Code Information Extended 77D : Unused 3";
BA_ "VNSigAllNodes" SG_ 1917 DTCIUnused3_77D 1;
BA_ "SignalType" SG_ 1917 DTCIUnused2_77D "BLN";
BA_ "PacketOrder" SG_ 1917 DTCIUnused2_77D 2;
BA_ "SignalLongName" SG_ 1917 DTCIUnused2_77D "Diagnostic Trouble Code Information Extended 77D : Unused 2";
BA_ "VNSigAllNodes" SG_ 1917 DTCIUnused2_77D 1;
BA_ "SignalType" SG_ 1917 DTCIUnused1_77D "BLN";
BA_ "PacketOrder" SG_ 1917 DTCIUnused1_77D 1;
BA_ "SignalLongName" SG_ 1917 DTCIUnused1_77D "Diagnostic Trouble Code Information Extended 77D : Unused 1";
BA_ "VNSigAllNodes" SG_ 1917 DTCIUnused1_77D 1;
BA_ "SignalType" SG_ 1918 DTCI_DTCFaultType_77E "ENM";
BA_ "PacketOrder" SG_ 1918 DTCI_DTCFaultType_77E 20;
BA_ "SignalLongName" SG_ 1918 DTCI_DTCFaultType_77E "Diagnostic Trouble Code Information Extended 77E : Diagnostic Trouble Code Fault Type";
BA_ "VNSigAllNodes" SG_ 1918 DTCI_DTCFaultType_77E 1;
BA_ "SignalType" SG_ 1918 DTCI_CodeSupported_77E "BLN";
BA_ "PacketOrder" SG_ 1918 DTCI_CodeSupported_77E 19;
BA_ "SignalLongName" SG_ 1918 DTCI_CodeSupported_77E "Diagnostic Trouble Code Information Extended 77E : Code Supported";
BA_ "VNSigAllNodes" SG_ 1918 DTCI_CodeSupported_77E 1;
BA_ "SignalType" SG_ 1918 DTCI_CurrentStatus_77E "BLN";
BA_ "PacketOrder" SG_ 1918 DTCI_CurrentStatus_77E 18;
BA_ "SignalLongName" SG_ 1918 DTCI_CurrentStatus_77E "Diagnostic Trouble Code Information Extended 77E : Current Status";
BA_ "VNSigAllNodes" SG_ 1918 DTCI_CurrentStatus_77E 1;
BA_ "SignalType" SG_ 1918 DTCI_TstNPsdCdClrdSt_77E "BLN";
BA_ "PacketOrder" SG_ 1918 DTCI_TstNPsdCdClrdSt_77E 17;
BA_ "SignalLongName" SG_ 1918 DTCI_TstNPsdCdClrdSt_77E "Diagnostic Trouble Code Information Extended 77E : Test Not Passed Since Code Cleared Status";
BA_ "VNSigAllNodes" SG_ 1918 DTCI_TstNPsdCdClrdSt_77E 1;
BA_ "SignalType" SG_ 1918 DTCI_TstFldCdClrdStat_77E "BLN";
BA_ "PacketOrder" SG_ 1918 DTCI_TstFldCdClrdStat_77E 16;
BA_ "SignalLongName" SG_ 1918 DTCI_TstFldCdClrdStat_77E "Diagnostic Trouble Code Information Extended 77E : Test Failed Since Code Cleared Status";
BA_ "VNSigAllNodes" SG_ 1918 DTCI_TstFldCdClrdStat_77E 1;
BA_ "SignalType" SG_ 1918 DTCI_HistStat_77E "BLN";
BA_ "PacketOrder" SG_ 1918 DTCI_HistStat_77E 15;
BA_ "SignalLongName" SG_ 1918 DTCI_HistStat_77E "Diagnostic Trouble Code Information Extended 77E : History Status";
BA_ "VNSigAllNodes" SG_ 1918 DTCI_HistStat_77E 1;
BA_ "SignalType" SG_ 1918 DTCI_TstNPsdPwrUpSt_77E "BLN";
BA_ "PacketOrder" SG_ 1918 DTCI_TstNPsdPwrUpSt_77E 14;
BA_ "SignalLongName" SG_ 1918 DTCI_TstNPsdPwrUpSt_77E "Diagnostic Trouble Code Information Extended 77E : Test Not Passed Since Power Up Status";
BA_ "VNSigAllNodes" SG_ 1918 DTCI_TstNPsdPwrUpSt_77E 1;
BA_ "SignalType" SG_ 1918 DTCI_TstFldPwrUpSt_77E "BLN";
BA_ "PacketOrder" SG_ 1918 DTCI_TstFldPwrUpSt_77E 13;
BA_ "SignalLongName" SG_ 1918 DTCI_TstFldPwrUpSt_77E "Diagnostic Trouble Code Information Extended 77E : Test Failed Since Power Up Status";
BA_ "VNSigAllNodes" SG_ 1918 DTCI_TstFldPwrUpSt_77E 1;
BA_ "SignalType" SG_ 1918 DTCI_WrnIndRqdSt_77E "BLN";
BA_ "PacketOrder" SG_ 1918 DTCI_WrnIndRqdSt_77E 12;
BA_ "SignalLongName" SG_ 1918 DTCI_WrnIndRqdSt_77E "Diagnostic Trouble Code Information Extended 77E : Warning Indicator Requested Status";
BA_ "VNSigAllNodes" SG_ 1918 DTCI_WrnIndRqdSt_77E 1;
BA_ "SignalType" SG_ 1918 DTCI_DTCFailType_77E "UNM";
BA_ "PacketOrder" SG_ 1918 DTCI_DTCFailType_77E 11;
BA_ "SignalLongName" SG_ 1918 DTCI_DTCFailType_77E "Diagnostic Trouble Code Information Extended 77E : Diagnostic Trouble Code Failure Type";
BA_ "VNSigAllNodes" SG_ 1918 DTCI_DTCFailType_77E 1;
BA_ "SignalType" SG_ 1918 DTCI_DTCNumber_77E "UNM";
BA_ "PacketOrder" SG_ 1918 DTCI_DTCNumber_77E 10;
BA_ "SignalLongName" SG_ 1918 DTCI_DTCNumber_77E "Diagnostic Trouble Code Information Extended 77E : Diagnostic Trouble Code Number";
BA_ "VNSigAllNodes" SG_ 1918 DTCI_DTCNumber_77E 1;
BA_ "SignalType" SG_ 1918 DTCI_DTCSource_77E "UNM";
BA_ "PacketOrder" SG_ 1918 DTCI_DTCSource_77E 9;
BA_ "SignalLongName" SG_ 1918 DTCI_DTCSource_77E "Diagnostic Trouble Code Information Extended 77E : Diagnostic Trouble Code Source";
BA_ "VNSigAllNodes" SG_ 1918 DTCI_DTCSource_77E 1;
BA_ "SignalType" SG_ 1918 DTCI_DTCTriggered_77E "BLN";
BA_ "PacketOrder" SG_ 1918 DTCI_DTCTriggered_77E 8;
BA_ "SignalLongName" SG_ 1918 DTCI_DTCTriggered_77E "Diagnostic Trouble Code Information Extended 77E : Diagnostic Trouble Code Triggered";
BA_ "VNSigAllNodes" SG_ 1918 DTCI_DTCTriggered_77E 1;
BA_ "SignalType" SG_ 1918 DTCIUnused7_77E "BLN";
BA_ "PacketOrder" SG_ 1918 DTCIUnused7_77E 7;
BA_ "SignalLongName" SG_ 1918 DTCIUnused7_77E "Diagnostic Trouble Code Information Extended 77E : Unused 7";
BA_ "VNSigAllNodes" SG_ 1918 DTCIUnused7_77E 1;
BA_ "SignalType" SG_ 1918 DTCIUnused6_77E "BLN";
BA_ "PacketOrder" SG_ 1918 DTCIUnused6_77E 6;
BA_ "SignalLongName" SG_ 1918 DTCIUnused6_77E "Diagnostic Trouble Code Information Extended 77E : Unused 6";
BA_ "VNSigAllNodes" SG_ 1918 DTCIUnused6_77E 1;
BA_ "SignalType" SG_ 1918 DTCIUnused5_77E "BLN";
BA_ "PacketOrder" SG_ 1918 DTCIUnused5_77E 5;
BA_ "SignalLongName" SG_ 1918 DTCIUnused5_77E "Diagnostic Trouble Code Information Extended 77E : Unused 5";
BA_ "VNSigAllNodes" SG_ 1918 DTCIUnused5_77E 1;
BA_ "SignalType" SG_ 1918 DTCIUnused4_77E "BLN";
BA_ "PacketOrder" SG_ 1918 DTCIUnused4_77E 4;
BA_ "SignalLongName" SG_ 1918 DTCIUnused4_77E "Diagnostic Trouble Code Information Extended 77E : Unused 4";
BA_ "VNSigAllNodes" SG_ 1918 DTCIUnused4_77E 1;
BA_ "SignalType" SG_ 1918 DTCIUnused3_77E "BLN";
BA_ "PacketOrder" SG_ 1918 DTCIUnused3_77E 3;
BA_ "SignalLongName" SG_ 1918 DTCIUnused3_77E "Diagnostic Trouble Code Information Extended 77E : Unused 3";
BA_ "VNSigAllNodes" SG_ 1918 DTCIUnused3_77E 1;
BA_ "SignalType" SG_ 1918 DTCIUnused2_77E "BLN";
BA_ "PacketOrder" SG_ 1918 DTCIUnused2_77E 2;
BA_ "SignalLongName" SG_ 1918 DTCIUnused2_77E "Diagnostic Trouble Code Information Extended 77E : Unused 2";
BA_ "VNSigAllNodes" SG_ 1918 DTCIUnused2_77E 1;
BA_ "SignalType" SG_ 1918 DTCIUnused1_77E "BLN";
BA_ "PacketOrder" SG_ 1918 DTCIUnused1_77E 1;
BA_ "SignalLongName" SG_ 1918 DTCIUnused1_77E "Diagnostic Trouble Code Information Extended 77E : Unused 1";
BA_ "VNSigAllNodes" SG_ 1918 DTCIUnused1_77E 1;
BA_ "SignalType" SG_ 1919 DTCI_DTCFaultType_77F "ENM";
BA_ "PacketOrder" SG_ 1919 DTCI_DTCFaultType_77F 20;
BA_ "SignalLongName" SG_ 1919 DTCI_DTCFaultType_77F "Diagnostic Trouble Code Information Extended 77F : Diagnostic Trouble Code Fault Type";
BA_ "VNSigAllNodes" SG_ 1919 DTCI_DTCFaultType_77F 1;
BA_ "SignalType" SG_ 1919 DTCI_CodeSupported_77F "BLN";
BA_ "PacketOrder" SG_ 1919 DTCI_CodeSupported_77F 19;
BA_ "SignalLongName" SG_ 1919 DTCI_CodeSupported_77F "Diagnostic Trouble Code Information Extended 77F : Code Supported";
BA_ "VNSigAllNodes" SG_ 1919 DTCI_CodeSupported_77F 1;
BA_ "SignalType" SG_ 1919 DTCI_CurrentStatus_77F "BLN";
BA_ "PacketOrder" SG_ 1919 DTCI_CurrentStatus_77F 18;
BA_ "SignalLongName" SG_ 1919 DTCI_CurrentStatus_77F "Diagnostic Trouble Code Information Extended 77F : Current Status";
BA_ "VNSigAllNodes" SG_ 1919 DTCI_CurrentStatus_77F 1;
BA_ "SignalType" SG_ 1919 DTCI_TstNPsdCdClrdSt_77F "BLN";
BA_ "PacketOrder" SG_ 1919 DTCI_TstNPsdCdClrdSt_77F 17;
BA_ "SignalLongName" SG_ 1919 DTCI_TstNPsdCdClrdSt_77F "Diagnostic Trouble Code Information Extended 77F : Test Not Passed Since Code Cleared Status";
BA_ "VNSigAllNodes" SG_ 1919 DTCI_TstNPsdCdClrdSt_77F 1;
BA_ "SignalType" SG_ 1919 DTCI_TstFldCdClrdStat_77F "BLN";
BA_ "PacketOrder" SG_ 1919 DTCI_TstFldCdClrdStat_77F 16;
BA_ "SignalLongName" SG_ 1919 DTCI_TstFldCdClrdStat_77F "Diagnostic Trouble Code Information Extended 77F : Test Failed Since Code Cleared Status";
BA_ "VNSigAllNodes" SG_ 1919 DTCI_TstFldCdClrdStat_77F 1;
BA_ "SignalType" SG_ 1919 DTCI_HistStat_77F "BLN";
BA_ "PacketOrder" SG_ 1919 DTCI_HistStat_77F 15;
BA_ "SignalLongName" SG_ 1919 DTCI_HistStat_77F "Diagnostic Trouble Code Information Extended 77F : History Status";
BA_ "VNSigAllNodes" SG_ 1919 DTCI_HistStat_77F 1;
BA_ "SignalType" SG_ 1919 DTCI_TstNPsdPwrUpSt_77F "BLN";
BA_ "PacketOrder" SG_ 1919 DTCI_TstNPsdPwrUpSt_77F 14;
BA_ "SignalLongName" SG_ 1919 DTCI_TstNPsdPwrUpSt_77F "Diagnostic Trouble Code Information Extended 77F : Test Not Passed Since Power Up Status";
BA_ "VNSigAllNodes" SG_ 1919 DTCI_TstNPsdPwrUpSt_77F 1;
BA_ "SignalType" SG_ 1919 DTCI_TstFldPwrUpSt_77F "BLN";
BA_ "PacketOrder" SG_ 1919 DTCI_TstFldPwrUpSt_77F 13;
BA_ "SignalLongName" SG_ 1919 DTCI_TstFldPwrUpSt_77F "Diagnostic Trouble Code Information Extended 77F : Test Failed Since Power Up Status";
BA_ "VNSigAllNodes" SG_ 1919 DTCI_TstFldPwrUpSt_77F 1;
BA_ "SignalType" SG_ 1919 DTCI_WrnIndRqdSt_77F "BLN";
BA_ "PacketOrder" SG_ 1919 DTCI_WrnIndRqdSt_77F 12;
BA_ "SignalLongName" SG_ 1919 DTCI_WrnIndRqdSt_77F "Diagnostic Trouble Code Information Extended 77F : Warning Indicator Requested Status";
BA_ "VNSigAllNodes" SG_ 1919 DTCI_WrnIndRqdSt_77F 1;
BA_ "SignalType" SG_ 1919 DTCI_DTCFailType_77F "UNM";
BA_ "PacketOrder" SG_ 1919 DTCI_DTCFailType_77F 11;
BA_ "SignalLongName" SG_ 1919 DTCI_DTCFailType_77F "Diagnostic Trouble Code Information Extended 77F : Diagnostic Trouble Code Failure Type";
BA_ "VNSigAllNodes" SG_ 1919 DTCI_DTCFailType_77F 1;
BA_ "SignalType" SG_ 1919 DTCI_DTCNumber_77F "UNM";
BA_ "PacketOrder" SG_ 1919 DTCI_DTCNumber_77F 10;
BA_ "SignalLongName" SG_ 1919 DTCI_DTCNumber_77F "Diagnostic Trouble Code Information Extended 77F : Diagnostic Trouble Code Number";
BA_ "VNSigAllNodes" SG_ 1919 DTCI_DTCNumber_77F 1;
BA_ "SignalType" SG_ 1919 DTCI_DTCSource_77F "UNM";
BA_ "PacketOrder" SG_ 1919 DTCI_DTCSource_77F 9;
BA_ "SignalLongName" SG_ 1919 DTCI_DTCSource_77F "Diagnostic Trouble Code Information Extended 77F : Diagnostic Trouble Code Source";
BA_ "VNSigAllNodes" SG_ 1919 DTCI_DTCSource_77F 1;
BA_ "SignalType" SG_ 1919 DTCI_DTCTriggered_77F "BLN";
BA_ "PacketOrder" SG_ 1919 DTCI_DTCTriggered_77F 8;
BA_ "SignalLongName" SG_ 1919 DTCI_DTCTriggered_77F "Diagnostic Trouble Code Information Extended 77F : Diagnostic Trouble Code Triggered";
BA_ "VNSigAllNodes" SG_ 1919 DTCI_DTCTriggered_77F 1;
BA_ "SignalType" SG_ 1919 DTCIUnused7_77F "BLN";
BA_ "PacketOrder" SG_ 1919 DTCIUnused7_77F 7;
BA_ "SignalLongName" SG_ 1919 DTCIUnused7_77F "Diagnostic Trouble Code Information Extended 77F : Unused 7";
BA_ "VNSigAllNodes" SG_ 1919 DTCIUnused7_77F 1;
BA_ "SignalType" SG_ 1919 DTCIUnused6_77F "BLN";
BA_ "PacketOrder" SG_ 1919 DTCIUnused6_77F 6;
BA_ "SignalLongName" SG_ 1919 DTCIUnused6_77F "Diagnostic Trouble Code Information Extended 77F : Unused 6";
BA_ "VNSigAllNodes" SG_ 1919 DTCIUnused6_77F 1;
BA_ "SignalType" SG_ 1919 DTCIUnused5_77F "BLN";
BA_ "PacketOrder" SG_ 1919 DTCIUnused5_77F 5;
BA_ "SignalLongName" SG_ 1919 DTCIUnused5_77F "Diagnostic Trouble Code Information Extended 77F : Unused 5";
BA_ "VNSigAllNodes" SG_ 1919 DTCIUnused5_77F 1;
BA_ "SignalType" SG_ 1919 DTCIUnused4_77F "BLN";
BA_ "PacketOrder" SG_ 1919 DTCIUnused4_77F 4;
BA_ "SignalLongName" SG_ 1919 DTCIUnused4_77F "Diagnostic Trouble Code Information Extended 77F : Unused 4";
BA_ "VNSigAllNodes" SG_ 1919 DTCIUnused4_77F 1;
BA_ "SignalType" SG_ 1919 DTCIUnused3_77F "BLN";
BA_ "PacketOrder" SG_ 1919 DTCIUnused3_77F 3;
BA_ "SignalLongName" SG_ 1919 DTCIUnused3_77F "Diagnostic Trouble Code Information Extended 77F : Unused 3";
BA_ "VNSigAllNodes" SG_ 1919 DTCIUnused3_77F 1;
BA_ "SignalType" SG_ 1919 DTCIUnused2_77F "BLN";
BA_ "PacketOrder" SG_ 1919 DTCIUnused2_77F 2;
BA_ "SignalLongName" SG_ 1919 DTCIUnused2_77F "Diagnostic Trouble Code Information Extended 77F : Unused 2";
BA_ "VNSigAllNodes" SG_ 1919 DTCIUnused2_77F 1;
BA_ "SignalType" SG_ 1919 DTCIUnused1_77F "BLN";
BA_ "PacketOrder" SG_ 1919 DTCIUnused1_77F 1;
BA_ "SignalLongName" SG_ 1919 DTCIUnused1_77F "Diagnostic Trouble Code Information Extended 77F : Unused 1";
BA_ "VNSigAllNodes" SG_ 1919 DTCIUnused1_77F 1;
BA_ "VNSigSLHSSharedDiagnostic" SG_ 589 DgnInf 1;
BA_ "SignalType" SG_ 589 DgnInf "UNM";
BA_ "SignalLongName" SG_ 589 DgnInf "Diagnostic Information";
BA_ "VNSigAllNodes" SG_ 589 DgnInf 1;
BA_ "VNSigSLHSSharedDiagnostic" SG_ 1357 DgnInf_HS54D 1;
BA_ "SignalType" SG_ 1357 DgnInf_HS54D "UNM";
BA_ "SignalLongName" SG_ 1357 DgnInf_HS54D "Diagnostic Information HS54D";
BA_ "VNSigAllNodes" SG_ 1357 DgnInf_HS54D 1;
BA_ "VNSigSLHSSharedDiagnostic" SG_ 1613 DgnInf 1;
BA_ "SignalType" SG_ 1613 DgnInf "UNM";
BA_ "SignalLongName" SG_ 1613 DgnInf "Diagnostic Information";
BA_ "VNSigAllNodes" SG_ 1613 DgnInf 1;
BA_ "VNSigSLHSSharedDiagnostic" SG_ 1606 DgnInf 1;
BA_ "SignalType" SG_ 1606 DgnInf "UNM";
BA_ "SignalLongName" SG_ 1606 DgnInf "Diagnostic Information";
BA_ "VNSigAllNodes" SG_ 1606 DgnInf 1;
BA_ "VNSigSLHSSharedDiagnostic" SG_ 582 DgnInf 1;
BA_ "SignalType" SG_ 582 DgnInf "UNM";
BA_ "SignalLongName" SG_ 582 DgnInf "Diagnostic Information";
BA_ "VNSigAllNodes" SG_ 582 DgnInf 1;
BA_ "VNSigSLHSSharedDiagnostic" SG_ 590 DgnInf 1;
BA_ "SignalType" SG_ 590 DgnInf "UNM";
BA_ "SignalLongName" SG_ 590 DgnInf "Diagnostic Information";
BA_ "VNSigAllNodes" SG_ 590 DgnInf 1;
BA_ "VNSigSLHSSharedDiagnostic" SG_ 601 DgnInf 1;
BA_ "SignalType" SG_ 601 DgnInf "UNM";
BA_ "SignalLongName" SG_ 601 DgnInf "Diagnostic Information";
BA_ "VNSigAllNodes" SG_ 601 DgnInf 1;
BA_ "VNSigSLHSSharedDiagnostic" SG_ 1369 DgnInf_HS559 1;
BA_ "SignalType" SG_ 1369 DgnInf_HS559 "UNM";
BA_ "SignalLongName" SG_ 1369 DgnInf_HS559 "Diagnostic Information HS559";
BA_ "VNSigAllNodes" SG_ 1369 DgnInf_HS559 1;
BA_ "VNSigSLHSSharedDiagnostic" SG_ 1625 DgnInf 1;
BA_ "SignalType" SG_ 1625 DgnInf "UNM";
BA_ "SignalLongName" SG_ 1625 DgnInf "Diagnostic Information";
BA_ "VNSigAllNodes" SG_ 1625 DgnInf 1;
BA_ "VNSigSLHSSharedDiagnostic" SG_ 1356 DgnInf_HS54C 1;
BA_ "SignalType" SG_ 1356 DgnInf_HS54C "UNM";
BA_ "SignalLongName" SG_ 1356 DgnInf_HS54C "Diagnostic Information HS54C";
BA_ "VNSigAllNodes" SG_ 1356 DgnInf_HS54C 1;
BA_ "VNSigSLHSSharedDiagnostic" SG_ 1358 DgnInf_HS54E 1;
BA_ "SignalType" SG_ 1358 DgnInf_HS54E "UNM";
BA_ "SignalLongName" SG_ 1358 DgnInf_HS54E "Diagnostic Information HS54E";
BA_ "VNSigAllNodes" SG_ 1358 DgnInf_HS54E 1;
BA_ "VNSigSLHSSharedDiagnostic" SG_ 1359 DgnInf_HS54F 1;
BA_ "SignalType" SG_ 1359 DgnInf_HS54F "UNM";
BA_ "SignalLongName" SG_ 1359 DgnInf_HS54F "Diagnostic Information HS54F";
BA_ "VNSigAllNodes" SG_ 1359 DgnInf_HS54F 1;
BA_ "VNSigSLHSSharedDiagnostic" SG_ 2023 DgnInf 1;
BA_ "SignalType" SG_ 2023 DgnInf "UNM";
BA_ "SignalLongName" SG_ 2023 DgnInf "Diagnostic Information";
BA_ "VNSigAllNodes" SG_ 2023 DgnInf 1;
BA_ "VNSigSLHSSharedDiagnostic" SG_ 2021 DgnInf 1;
BA_ "SignalType" SG_ 2021 DgnInf "UNM";
BA_ "SignalLongName" SG_ 2021 DgnInf "Diagnostic Information";
BA_ "VNSigAllNodes" SG_ 2021 DgnInf 1;
BA_ "VNSigSLHSSharedDiagnostic" SG_ 2017 DgnInf 1;
BA_ "SignalType" SG_ 2017 DgnInf "UNM";
BA_ "SignalLongName" SG_ 2017 DgnInf "Diagnostic Information";
BA_ "VNSigAllNodes" SG_ 2017 DgnInf 1;
BA_ "VNSigSLHSSharedDiagnostic" SG_ 2019 DgnInf 1;
BA_ "SignalType" SG_ 2019 DgnInf "UNM";
BA_ "SignalLongName" SG_ 2019 DgnInf "Diagnostic Information";
BA_ "VNSigAllNodes" SG_ 2019 DgnInf 1;
BA_ "VNSigSLHSSharedDiagnostic" SG_ 585 DgnInf 1;
BA_ "SignalType" SG_ 585 DgnInf "UNM";
BA_ "SignalLongName" SG_ 585 DgnInf "Diagnostic Information";
BA_ "VNSigAllNodes" SG_ 585 DgnInf 1;
BA_ "VNSigSLHSSharedDiagnostic" SG_ 578 DgnInf 1;
BA_ "SignalType" SG_ 578 DgnInf "UNM";
BA_ "SignalLongName" SG_ 578 DgnInf "Diagnostic Information";
BA_ "VNSigAllNodes" SG_ 578 DgnInf 1;
BA_ "VNSigSLHSSharedDiagnostic" SG_ 2022 DgnInf 1;
BA_ "SignalType" SG_ 2022 DgnInf "UNM";
BA_ "SignalLongName" SG_ 2022 DgnInf "Diagnostic Information";
BA_ "VNSigAllNodes" SG_ 2022 DgnInf 1;
BA_ "VNSigSLHSSharedDiagnostic" SG_ 584 DgnInf 1;
BA_ "SignalType" SG_ 584 DgnInf "UNM";
BA_ "SignalLongName" SG_ 584 DgnInf "Diagnostic Information";
BA_ "VNSigAllNodes" SG_ 584 DgnInf 1;
BA_ "VNSigSLHSSharedDiagnostic" SG_ 591 DgnInf 1;
BA_ "SignalType" SG_ 591 DgnInf "UNM";
BA_ "SignalLongName" SG_ 591 DgnInf "Diagnostic Information";
BA_ "VNSigAllNodes" SG_ 591 DgnInf 1;
BA_ "VNSigSLHSSharedDiagnostic" SG_ 581 DgnInf 1;
BA_ "SignalType" SG_ 581 DgnInf "UNM";
BA_ "SignalLongName" SG_ 581 DgnInf "Diagnostic Information";
BA_ "VNSigAllNodes" SG_ 581 DgnInf 1;
BA_ "VNSigSLHSSharedDiagnostic" SG_ 586 DgnInf 1;
BA_ "SignalType" SG_ 586 DgnInf "UNM";
BA_ "SignalLongName" SG_ 586 DgnInf "Diagnostic Information";
BA_ "VNSigAllNodes" SG_ 586 DgnInf 1;
BA_ "VNSigSLHSSharedDiagnostic" SG_ 588 DgnInf 1;
BA_ "SignalType" SG_ 588 DgnInf "UNM";
BA_ "SignalLongName" SG_ 588 DgnInf "Diagnostic Information";
BA_ "VNSigAllNodes" SG_ 588 DgnInf 1;
BA_ "VNSigSLHSSharedDiagnostic" SG_ 580 DgnInf 1;
BA_ "SignalType" SG_ 580 DgnInf "UNM";
BA_ "SignalLongName" SG_ 580 DgnInf "Diagnostic Information";
BA_ "VNSigAllNodes" SG_ 580 DgnInf 1;
BA_ "SignalType" SG_ 499 PTShftPtrnOvrdAct "BLN";
BA_ "SignalLongName" SG_ 499 PTShftPtrnOvrdAct "Powertrain Shift Pattern Override Active";
BA_ "VNSigAllNodes" SG_ 499 PTShftPtrnOvrdAct 1;
BA_ "SignalType" SG_ 499 PFTrnsTUDSecSwSt "ENM";
BA_ "SignalLongName" SG_ 499 PFTrnsTUDSecSwSt "Platform Transmission Tap Up/Down Secondary Switch State";
BA_ "VNSigAllNodes" SG_ 499 PFTrnsTUDSecSwSt 1;
BA_ "SignalType" SG_ 499 TrnsPFShftPattSwARC "UNM";
BA_ "SignalLongName" SG_ 499 TrnsPFShftPattSwARC "Transmission Platform Shift Pattern Switch Alive Rolling Count";
BA_ "VNSigAllNodes" SG_ 499 TrnsPFShftPattSwARC 1;
BA_ "SignalType" SG_ 499 TrnsPFShftPattSw4Act "BLN";
BA_ "SignalLongName" SG_ 499 TrnsPFShftPattSw4Act "Transmission Platform Shift Pattern Switch 4 Active";
BA_ "VNSigAllNodes" SG_ 499 TrnsPFShftPattSw4Act 1;
BA_ "SignalType" SG_ 499 TrnsPFShftPattSw3Act "BLN";
BA_ "SignalLongName" SG_ 499 TrnsPFShftPattSw3Act "Transmission Platform Shift Pattern Switch 3 Active";
BA_ "VNSigAllNodes" SG_ 499 TrnsPFShftPattSw3Act 1;
BA_ "SignalType" SG_ 499 TrnsPFShftPattSw2Act "BLN";
BA_ "SignalLongName" SG_ 499 TrnsPFShftPattSw2Act "Transmission Platform Shift Pattern Switch 2 Active";
BA_ "VNSigAllNodes" SG_ 499 TrnsPFShftPattSw2Act 1;
BA_ "SignalType" SG_ 499 TrnsPFShftPattSw1Act "BLN";
BA_ "SignalLongName" SG_ 499 TrnsPFShftPattSw1Act "Transmission Platform Shift Pattern Switch 1 Active";
BA_ "VNSigAllNodes" SG_ 499 TrnsPFShftPattSw1Act 1;
BA_ "SignalType" SG_ 499 PFTrnsTUDSwStAlvRC "UNM";
BA_ "SignalLongName" SG_ 499 PFTrnsTUDSwStAlvRC "Platform Transmission Tap Up/Down Switch Status Alive Rolling Count";
BA_ "VNSigAllNodes" SG_ 499 PFTrnsTUDSwStAlvRC 1;
BA_ "SignalType" SG_ 499 PFTrnsTUDSwSt "ENM";
BA_ "SignalLongName" SG_ 499 PFTrnsTUDSwSt "Platform Transmission Tap Up/Down Switch State";
BA_ "VNSigAllNodes" SG_ 499 PFTrnsTUDSwSt 1;
BA_ "SignalType" SG_ 499 PFTrnsTUDEnSwSt "ENM";
BA_ "SignalLongName" SG_ 499 PFTrnsTUDEnSwSt "Platform Transmission Tap Up/Down Enable Switch State";
BA_ "VNSigAllNodes" SG_ 499 PFTrnsTUDEnSwSt 1;
BA_ "SignalType" SG_ 499 OvrdrvDsblReqd "BLN";
BA_ "SignalLongName" SG_ 499 OvrdrvDsblReqd "Overdrive Disable Requested";
BA_ "VNSigAllNodes" SG_ 499 OvrdrvDsblReqd 1;
BA_ "SignalType" SG_ 1282 TireTrdTmpStatARC "UNM";
BA_ "SignalLongName" SG_ 1282 TireTrdTmpStatARC "Tire Tread Temperature Status Alive Rolling Count";
BA_ "VNSigAllNodes" SG_ 1282 TireTrdTmpStatARC 1;
BA_ "SignalType" SG_ 1282 TireTrdTmpStat "ENM";
BA_ "SignalLongName" SG_ 1282 TireTrdTmpStat "Tire Tread Temperature Status";
BA_ "VNSigAllNodes" SG_ 1282 TireTrdTmpStat 1;
BA_ "VNSigSLHS_VNReq" SG_ 1282 AllNodesVNA_502 1;
BA_ "SignalType" SG_ 1282 AllNodesVNA_502 "ENM";
BA_ "SignalLongName" SG_ 1282 AllNodesVNA_502 "All Nodes Virtual Network Activation";
BA_ "VNSigAllNodes" SG_ 1282 AllNodesVNA_502 1;
BA_ "SignalType" SG_ 1282 A3ERRAlrmTime "UNM";
BA_ "PacketOrder" SG_ 1282 A3ERRAlrmTime 2;
BA_ "SignalLongName" SG_ 1282 A3ERRAlrmTime "Alarm 3 Extended Range Request : Alarm Time";
BA_ "VNSigAllNodes" SG_ 1282 A3ERRAlrmTime 1;
BA_ "SignalType" SG_ 1282 A3ERRAlrmReq "ENM";
BA_ "PacketOrder" SG_ 1282 A3ERRAlrmReq 1;
BA_ "SignalLongName" SG_ 1282 A3ERRAlrmReq "Alarm 3 Extended Range Request : Alarm Request";
BA_ "VNSigAllNodes" SG_ 1282 A3ERRAlrmReq 1;
BA_ "VNSigSLHSSharedDiagnostic" SG_ 1360 DgnInf_HS550 1;
BA_ "SignalType" SG_ 1360 DgnInf_HS550 "UNM";
BA_ "SignalLongName" SG_ 1360 DgnInf_HS550 "Diagnostic Information HS550";
BA_ "VNSigAllNodes" SG_ 1360 DgnInf_HS550 1;
BA_ "VNSigSLHSSharedDiagnostic" SG_ 1616 DgnInf 1;
BA_ "SignalType" SG_ 1616 DgnInf "UNM";
BA_ "SignalLongName" SG_ 1616 DgnInf "Diagnostic Information";
BA_ "VNSigAllNodes" SG_ 1616 DgnInf 1;
BA_ "SignalType" SG_ 1921 DTCI_CurrentStatus_781 "BLN";
BA_ "PacketOrder" SG_ 1921 DTCI_CurrentStatus_781 18;
BA_ "SignalLongName" SG_ 1921 DTCI_CurrentStatus_781 "Diagnostic Trouble Code Information Extended 781: Current Status";
BA_ "VNSigAllNodes" SG_ 1921 DTCI_CurrentStatus_781 1;
BA_ "SignalType" SG_ 1921 DTCI_WrnIndRqdSt_781 "BLN";
BA_ "PacketOrder" SG_ 1921 DTCI_WrnIndRqdSt_781 12;
BA_ "SignalLongName" SG_ 1921 DTCI_WrnIndRqdSt_781 "Diagnostic Trouble Code Information Extended 781 : Warning Indicator Requested Status";
BA_ "VNSigAllNodes" SG_ 1921 DTCI_WrnIndRqdSt_781 1;
BA_ "SignalType" SG_ 1921 DTCIUnused7_781 "BLN";
BA_ "PacketOrder" SG_ 1921 DTCIUnused7_781 7;
BA_ "SignalLongName" SG_ 1921 DTCIUnused7_781 "Diagnostic Trouble Code Information Extended 781 : Unused 7";
BA_ "VNSigAllNodes" SG_ 1921 DTCIUnused7_781 1;
BA_ "SignalType" SG_ 1921 DTCIUnused6_781 "BLN";
BA_ "PacketOrder" SG_ 1921 DTCIUnused6_781 6;
BA_ "SignalLongName" SG_ 1921 DTCIUnused6_781 "Diagnostic Trouble Code Information Extended 781 : Unused 6";
BA_ "VNSigAllNodes" SG_ 1921 DTCIUnused6_781 1;
BA_ "SignalType" SG_ 1921 DTCIUnused5_781 "BLN";
BA_ "PacketOrder" SG_ 1921 DTCIUnused5_781 5;
BA_ "SignalLongName" SG_ 1921 DTCIUnused5_781 "Diagnostic Trouble Code Information Extended 781 : Unused 5";
BA_ "VNSigAllNodes" SG_ 1921 DTCIUnused5_781 1;
BA_ "SignalType" SG_ 1921 DTCIUnused4_781 "BLN";
BA_ "PacketOrder" SG_ 1921 DTCIUnused4_781 4;
BA_ "SignalLongName" SG_ 1921 DTCIUnused4_781 "Diagnostic Trouble Code Information Extended 781 : Unused 4";
BA_ "VNSigAllNodes" SG_ 1921 DTCIUnused4_781 1;
BA_ "SignalType" SG_ 1921 DTCIUnused3_781 "BLN";
BA_ "PacketOrder" SG_ 1921 DTCIUnused3_781 3;
BA_ "SignalLongName" SG_ 1921 DTCIUnused3_781 "Diagnostic Trouble Code Information Extended 781 : Unused 3";
BA_ "VNSigAllNodes" SG_ 1921 DTCIUnused3_781 1;
BA_ "SignalType" SG_ 1921 DTCIUnused2_781 "BLN";
BA_ "PacketOrder" SG_ 1921 DTCIUnused2_781 2;
BA_ "SignalLongName" SG_ 1921 DTCIUnused2_781 "Diagnostic Trouble Code Information Extended 781 : Unused 2";
BA_ "VNSigAllNodes" SG_ 1921 DTCIUnused2_781 1;
BA_ "SignalType" SG_ 1921 DTCIUnused1_781 "BLN";
BA_ "PacketOrder" SG_ 1921 DTCIUnused1_781 1;
BA_ "SignalLongName" SG_ 1921 DTCIUnused1_781 "Diagnostic Trouble Code Information Extended 781 : Unused 1";
BA_ "VNSigAllNodes" SG_ 1921 DTCIUnused1_781 1;
BA_ "SignalType" SG_ 1921 DTCI_TstNPsdPwrUpSt_781 "BLN";
BA_ "PacketOrder" SG_ 1921 DTCI_TstNPsdPwrUpSt_781 14;
BA_ "SignalLongName" SG_ 1921 DTCI_TstNPsdPwrUpSt_781 "Diagnostic Trouble Code Information Extended 781 : Test Not Passed Since Power Up Status";
BA_ "VNSigAllNodes" SG_ 1921 DTCI_TstNPsdPwrUpSt_781 1;
BA_ "SignalType" SG_ 1921 DTCI_TstNPsdCdClrdSt_781 "BLN";
BA_ "PacketOrder" SG_ 1921 DTCI_TstNPsdCdClrdSt_781 17;
BA_ "SignalLongName" SG_ 1921 DTCI_TstNPsdCdClrdSt_781 "Diagnostic Trouble Code Information Extended 781 : Test Not Passed Since Code Cleared Status";
BA_ "VNSigAllNodes" SG_ 1921 DTCI_TstNPsdCdClrdSt_781 1;
BA_ "SignalType" SG_ 1921 DTCI_TstFldPwrUpSt_781 "BLN";
BA_ "PacketOrder" SG_ 1921 DTCI_TstFldPwrUpSt_781 13;
BA_ "SignalLongName" SG_ 1921 DTCI_TstFldPwrUpSt_781 "Diagnostic Trouble Code Information Extended 781 : Test Failed Since Power Up Status";
BA_ "VNSigAllNodes" SG_ 1921 DTCI_TstFldPwrUpSt_781 1;
BA_ "SignalType" SG_ 1921 DTCI_TstFldCdClrdStat_781 "BLN";
BA_ "PacketOrder" SG_ 1921 DTCI_TstFldCdClrdStat_781 16;
BA_ "SignalLongName" SG_ 1921 DTCI_TstFldCdClrdStat_781 "Diagnostic Trouble Code Information Extended 781 : Test Failed Since Code Cleared Status";
BA_ "VNSigAllNodes" SG_ 1921 DTCI_TstFldCdClrdStat_781 1;
BA_ "SignalType" SG_ 1921 DTCI_HistStat_781 "BLN";
BA_ "PacketOrder" SG_ 1921 DTCI_HistStat_781 15;
BA_ "SignalLongName" SG_ 1921 DTCI_HistStat_781 "Diagnostic Trouble Code Information Extended 781 : History Status";
BA_ "VNSigAllNodes" SG_ 1921 DTCI_HistStat_781 1;
BA_ "SignalType" SG_ 1921 DTCI_DTCTriggered_781 "BLN";
BA_ "PacketOrder" SG_ 1921 DTCI_DTCTriggered_781 8;
BA_ "SignalLongName" SG_ 1921 DTCI_DTCTriggered_781 "Diagnostic Trouble Code Information Extended 781 : Diagnostic Trouble Code Triggered";
BA_ "VNSigAllNodes" SG_ 1921 DTCI_DTCTriggered_781 1;
BA_ "SignalType" SG_ 1921 DTCI_DTCSource_781 "UNM";
BA_ "PacketOrder" SG_ 1921 DTCI_DTCSource_781 9;
BA_ "SignalLongName" SG_ 1921 DTCI_DTCSource_781 "Diagnostic Trouble Code Information Extended 781 : Diagnostic Trouble Code Source";
BA_ "VNSigAllNodes" SG_ 1921 DTCI_DTCSource_781 1;
BA_ "SignalType" SG_ 1921 DTCI_DTCNumber_781 "UNM";
BA_ "PacketOrder" SG_ 1921 DTCI_DTCNumber_781 10;
BA_ "SignalLongName" SG_ 1921 DTCI_DTCNumber_781 "Diagnostic Trouble Code Information Extended 781 : Diagnostic Trouble Code Number";
BA_ "VNSigAllNodes" SG_ 1921 DTCI_DTCNumber_781 1;
BA_ "SignalType" SG_ 1921 DTCI_DTCFaultType_781 "ENM";
BA_ "PacketOrder" SG_ 1921 DTCI_DTCFaultType_781 20;
BA_ "SignalLongName" SG_ 1921 DTCI_DTCFaultType_781 "Diagnostic Trouble Code Information Extended 781 : Diagnostic Trouble Code Fault Type";
BA_ "VNSigAllNodes" SG_ 1921 DTCI_DTCFaultType_781 1;
BA_ "SignalType" SG_ 1921 DTCI_DTCFailType_781 "UNM";
BA_ "PacketOrder" SG_ 1921 DTCI_DTCFailType_781 11;
BA_ "SignalLongName" SG_ 1921 DTCI_DTCFailType_781 "Diagnostic Trouble Code Information Extended 781 : Diagnostic Trouble Code Failure Type";
BA_ "VNSigAllNodes" SG_ 1921 DTCI_DTCFailType_781 1;
BA_ "SignalType" SG_ 1921 DTCI_CodeSupported_781 "BLN";
BA_ "PacketOrder" SG_ 1921 DTCI_CodeSupported_781 19;
BA_ "SignalLongName" SG_ 1921 DTCI_CodeSupported_781 "Diagnostic Trouble Code Information Extended 781 : Code Supported";
BA_ "VNSigAllNodes" SG_ 1921 DTCI_CodeSupported_781 1;
BA_ "SignalType" SG_ 1920 DTCI_CurrentStatus_780 "BLN";
BA_ "PacketOrder" SG_ 1920 DTCI_CurrentStatus_780 18;
BA_ "SignalLongName" SG_ 1920 DTCI_CurrentStatus_780 "Diagnostic Trouble Code Information Extended 780 : Current Status";
BA_ "VNSigAllNodes" SG_ 1920 DTCI_CurrentStatus_780 1;
BA_ "SignalType" SG_ 1920 DTCI_WrnIndRqdSt_780 "BLN";
BA_ "PacketOrder" SG_ 1920 DTCI_WrnIndRqdSt_780 12;
BA_ "SignalLongName" SG_ 1920 DTCI_WrnIndRqdSt_780 "Diagnostic Trouble Code Information Extended 780 : Warning Indicator Requested Status";
BA_ "VNSigAllNodes" SG_ 1920 DTCI_WrnIndRqdSt_780 1;
BA_ "SignalType" SG_ 1920 DTCIUnused7_780 "BLN";
BA_ "PacketOrder" SG_ 1920 DTCIUnused7_780 7;
BA_ "SignalLongName" SG_ 1920 DTCIUnused7_780 "Diagnostic Trouble Code Information Extended 780 : Unused 7";
BA_ "VNSigAllNodes" SG_ 1920 DTCIUnused7_780 1;
BA_ "SignalType" SG_ 1920 DTCIUnused6_780 "BLN";
BA_ "PacketOrder" SG_ 1920 DTCIUnused6_780 6;
BA_ "SignalLongName" SG_ 1920 DTCIUnused6_780 "Diagnostic Trouble Code Information Extended 780 : Unused 6";
BA_ "VNSigAllNodes" SG_ 1920 DTCIUnused6_780 1;
BA_ "SignalType" SG_ 1920 DTCIUnused5_780 "BLN";
BA_ "PacketOrder" SG_ 1920 DTCIUnused5_780 5;
BA_ "SignalLongName" SG_ 1920 DTCIUnused5_780 "Diagnostic Trouble Code Information Extended 780 : Unused 5";
BA_ "VNSigAllNodes" SG_ 1920 DTCIUnused5_780 1;
BA_ "SignalType" SG_ 1920 DTCIUnused4_780 "BLN";
BA_ "PacketOrder" SG_ 1920 DTCIUnused4_780 4;
BA_ "SignalLongName" SG_ 1920 DTCIUnused4_780 "Diagnostic Trouble Code Information Extended 780 : Unused 4";
BA_ "VNSigAllNodes" SG_ 1920 DTCIUnused4_780 1;
BA_ "SignalType" SG_ 1920 DTCIUnused3_780 "BLN";
BA_ "PacketOrder" SG_ 1920 DTCIUnused3_780 3;
BA_ "SignalLongName" SG_ 1920 DTCIUnused3_780 "Diagnostic Trouble Code Information Extended 780 : Unused 3";
BA_ "VNSigAllNodes" SG_ 1920 DTCIUnused3_780 1;
BA_ "SignalType" SG_ 1920 DTCIUnused2_780 "BLN";
BA_ "PacketOrder" SG_ 1920 DTCIUnused2_780 2;
BA_ "SignalLongName" SG_ 1920 DTCIUnused2_780 "Diagnostic Trouble Code Information Extended 780 : Unused 2";
BA_ "VNSigAllNodes" SG_ 1920 DTCIUnused2_780 1;
BA_ "SignalType" SG_ 1920 DTCIUnused1_780 "BLN";
BA_ "PacketOrder" SG_ 1920 DTCIUnused1_780 1;
BA_ "SignalLongName" SG_ 1920 DTCIUnused1_780 "Diagnostic Trouble Code Information Extended 780 : Unused 1";
BA_ "VNSigAllNodes" SG_ 1920 DTCIUnused1_780 1;
BA_ "SignalType" SG_ 1920 DTCI_TstNPsdPwrUpSt_780 "BLN";
BA_ "PacketOrder" SG_ 1920 DTCI_TstNPsdPwrUpSt_780 14;
BA_ "SignalLongName" SG_ 1920 DTCI_TstNPsdPwrUpSt_780 "Diagnostic Trouble Code Information Extended 780 : Test Not Passed Since Power Up Status";
BA_ "VNSigAllNodes" SG_ 1920 DTCI_TstNPsdPwrUpSt_780 1;
BA_ "SignalType" SG_ 1920 DTCI_TstNPsdCdClrdSt_780 "BLN";
BA_ "PacketOrder" SG_ 1920 DTCI_TstNPsdCdClrdSt_780 17;
BA_ "SignalLongName" SG_ 1920 DTCI_TstNPsdCdClrdSt_780 "Diagnostic Trouble Code Information Extended 780 : Test Not Passed Since Code Cleared Status";
BA_ "VNSigAllNodes" SG_ 1920 DTCI_TstNPsdCdClrdSt_780 1;
BA_ "SignalType" SG_ 1920 DTCI_TstFldPwrUpSt_780 "BLN";
BA_ "PacketOrder" SG_ 1920 DTCI_TstFldPwrUpSt_780 13;
BA_ "SignalLongName" SG_ 1920 DTCI_TstFldPwrUpSt_780 "Diagnostic Trouble Code Information Extended 780 : Test Failed Since Power Up Status";
BA_ "VNSigAllNodes" SG_ 1920 DTCI_TstFldPwrUpSt_780 1;
BA_ "SignalType" SG_ 1920 DTCI_TstFldCdClrdStat_780 "BLN";
BA_ "PacketOrder" SG_ 1920 DTCI_TstFldCdClrdStat_780 16;
BA_ "SignalLongName" SG_ 1920 DTCI_TstFldCdClrdStat_780 "Diagnostic Trouble Code Information Extended 780 : Test Failed Since Code Cleared Status";
BA_ "VNSigAllNodes" SG_ 1920 DTCI_TstFldCdClrdStat_780 1;
BA_ "SignalType" SG_ 1920 DTCI_HistStat_780 "BLN";
BA_ "PacketOrder" SG_ 1920 DTCI_HistStat_780 15;
BA_ "SignalLongName" SG_ 1920 DTCI_HistStat_780 "Diagnostic Trouble Code Information Extended 780 : History Status";
BA_ "VNSigAllNodes" SG_ 1920 DTCI_HistStat_780 1;
BA_ "SignalType" SG_ 1920 DTCI_DTCTriggered_780 "BLN";
BA_ "PacketOrder" SG_ 1920 DTCI_DTCTriggered_780 8;
BA_ "SignalLongName" SG_ 1920 DTCI_DTCTriggered_780 "Diagnostic Trouble Code Information Extended 780 : Diagnostic Trouble Code Triggered";
BA_ "VNSigAllNodes" SG_ 1920 DTCI_DTCTriggered_780 1;
BA_ "SignalType" SG_ 1920 DTCI_DTCSource_780 "UNM";
BA_ "PacketOrder" SG_ 1920 DTCI_DTCSource_780 9;
BA_ "SignalLongName" SG_ 1920 DTCI_DTCSource_780 "Diagnostic Trouble Code Information Extended 780 : Diagnostic Trouble Code Source";
BA_ "VNSigAllNodes" SG_ 1920 DTCI_DTCSource_780 1;
BA_ "SignalType" SG_ 1920 DTCI_DTCNumber_780 "UNM";
BA_ "PacketOrder" SG_ 1920 DTCI_DTCNumber_780 10;
BA_ "SignalLongName" SG_ 1920 DTCI_DTCNumber_780 "Diagnostic Trouble Code Information Extended 780 : Diagnostic Trouble Code Number";
BA_ "VNSigAllNodes" SG_ 1920 DTCI_DTCNumber_780 1;
BA_ "SignalType" SG_ 1920 DTCI_DTCFaultType_780 "ENM";
BA_ "PacketOrder" SG_ 1920 DTCI_DTCFaultType_780 20;
BA_ "SignalLongName" SG_ 1920 DTCI_DTCFaultType_780 "Diagnostic Trouble Code Information Extended 780 : Diagnostic Trouble Code Fault Type";
BA_ "VNSigAllNodes" SG_ 1920 DTCI_DTCFaultType_780 1;
BA_ "SignalType" SG_ 1920 DTCI_DTCFailType_780 "UNM";
BA_ "PacketOrder" SG_ 1920 DTCI_DTCFailType_780 11;
BA_ "SignalLongName" SG_ 1920 DTCI_DTCFailType_780 "Diagnostic Trouble Code Information Extended 780 : Diagnostic Trouble Code Failure Type";
BA_ "VNSigAllNodes" SG_ 1920 DTCI_DTCFailType_780 1;
BA_ "SignalType" SG_ 1920 DTCI_CodeSupported_780 "BLN";
BA_ "PacketOrder" SG_ 1920 DTCI_CodeSupported_780 19;
BA_ "SignalLongName" SG_ 1920 DTCI_CodeSupported_780 "Diagnostic Trouble Code Information Extended 780 : Code Supported";
BA_ "VNSigAllNodes" SG_ 1920 DTCI_CodeSupported_780 1;
BA_ "VNSigSLHSSharedDiagnostic" SG_ 596 DgnInf 1;
BA_ "SignalType" SG_ 596 DgnInf "UNM";
BA_ "SignalLongName" SG_ 596 DgnInf "Diagnostic Information";
BA_ "VNSigAllNodes" SG_ 596 DgnInf 1;
BA_ "GenSigDeltaValue" SG_ 2033 PCUInfo 1;
BA_ "GenSigSendType" SG_ 2033 PCUInfo 12;
BA_ "SignalType" SG_ 2033 PCUInfo "UNM";
BA_ "SignalLongName" SG_ 2033 PCUInfo "Pyrotechnical Control Unit Information";
BA_ "VNSigAllNodes" SG_ 2033 PCUInfo 1;
BA_ "SignalType" SG_ 495 MassAirFloV "ENM";
BA_ "SignalLongName" SG_ 495 MassAirFloV "Mass Air Flow Validity";
BA_ "VNSigAllNodes" SG_ 495 MassAirFloV 1;
BA_ "SignalType" SG_ 495 MassAirFlo "UNM";
BA_ "SignalLongName" SG_ 495 MassAirFlo "Mass Air Flow";
BA_ "VNSigAllNodes" SG_ 495 MassAirFlo 1;
BA_ "VNSigSLHSSharedDiagnostic" SG_ 1350 DgnInf_HS546 1;
BA_ "SignalType" SG_ 1350 DgnInf_HS546 "UNM";
BA_ "SignalLongName" SG_ 1350 DgnInf_HS546 "Diagnostic Information HS546";
BA_ "VNSigAllNodes" SG_ 1350 DgnInf_HS546 1;
BA_ "SignalType" SG_ 1914 DTCI_DTCFaultType_77A "ENM";
BA_ "PacketOrder" SG_ 1914 DTCI_DTCFaultType_77A 20;
BA_ "SignalLongName" SG_ 1914 DTCI_DTCFaultType_77A "Diagnostic Trouble Code Information Extended 77A : Diagnostic Trouble Code Fault Type";
BA_ "VNSigAllNodes" SG_ 1914 DTCI_DTCFaultType_77A 1;
BA_ "SignalType" SG_ 1914 DTCI_CodeSupported_77A "BLN";
BA_ "PacketOrder" SG_ 1914 DTCI_CodeSupported_77A 19;
BA_ "SignalLongName" SG_ 1914 DTCI_CodeSupported_77A "Diagnostic Trouble Code Information Extended 77A : Code Supported";
BA_ "VNSigAllNodes" SG_ 1914 DTCI_CodeSupported_77A 1;
BA_ "SignalType" SG_ 1914 DTCI_CurrentStatus_77A "BLN";
BA_ "PacketOrder" SG_ 1914 DTCI_CurrentStatus_77A 18;
BA_ "SignalLongName" SG_ 1914 DTCI_CurrentStatus_77A "Diagnostic Trouble Code Information Extended 77A : Current Status";
BA_ "VNSigAllNodes" SG_ 1914 DTCI_CurrentStatus_77A 1;
BA_ "SignalType" SG_ 1914 DTCI_TstNPsdCdClrdSt_77A "BLN";
BA_ "PacketOrder" SG_ 1914 DTCI_TstNPsdCdClrdSt_77A 17;
BA_ "SignalLongName" SG_ 1914 DTCI_TstNPsdCdClrdSt_77A "Diagnostic Trouble Code Information Extended 77A : Test Not Passed Since Code Cleared Status";
BA_ "VNSigAllNodes" SG_ 1914 DTCI_TstNPsdCdClrdSt_77A 1;
BA_ "SignalType" SG_ 1914 DTCI_TstFldCdClrdStat_77A "BLN";
BA_ "PacketOrder" SG_ 1914 DTCI_TstFldCdClrdStat_77A 16;
BA_ "SignalLongName" SG_ 1914 DTCI_TstFldCdClrdStat_77A "Diagnostic Trouble Code Information Extended 77A : Test Failed Since Code Cleared Status";
BA_ "VNSigAllNodes" SG_ 1914 DTCI_TstFldCdClrdStat_77A 1;
BA_ "SignalType" SG_ 1914 DTCI_HistStat_77A "BLN";
BA_ "PacketOrder" SG_ 1914 DTCI_HistStat_77A 15;
BA_ "SignalLongName" SG_ 1914 DTCI_HistStat_77A "Diagnostic Trouble Code Information Extended 77A : History Status";
BA_ "VNSigAllNodes" SG_ 1914 DTCI_HistStat_77A 1;
BA_ "SignalType" SG_ 1914 DTCI_TstNPsdPwrUpSt_77A "BLN";
BA_ "PacketOrder" SG_ 1914 DTCI_TstNPsdPwrUpSt_77A 14;
BA_ "SignalLongName" SG_ 1914 DTCI_TstNPsdPwrUpSt_77A "Diagnostic Trouble Code Information Extended 77A : Test Not Passed Since Power Up Status";
BA_ "VNSigAllNodes" SG_ 1914 DTCI_TstNPsdPwrUpSt_77A 1;
BA_ "SignalType" SG_ 1914 DTCI_TstFldPwrUpSt_77A "BLN";
BA_ "PacketOrder" SG_ 1914 DTCI_TstFldPwrUpSt_77A 13;
BA_ "SignalLongName" SG_ 1914 DTCI_TstFldPwrUpSt_77A "Diagnostic Trouble Code Information Extended 77A : Test Failed Since Power Up Status";
BA_ "VNSigAllNodes" SG_ 1914 DTCI_TstFldPwrUpSt_77A 1;
BA_ "SignalType" SG_ 1914 DTCI_WrnIndRqdSt_77A "BLN";
BA_ "PacketOrder" SG_ 1914 DTCI_WrnIndRqdSt_77A 12;
BA_ "SignalLongName" SG_ 1914 DTCI_WrnIndRqdSt_77A "Diagnostic Trouble Code Information Extended 77A : Warning Indicator Requested Status";
BA_ "VNSigAllNodes" SG_ 1914 DTCI_WrnIndRqdSt_77A 1;
BA_ "SignalType" SG_ 1914 DTCI_DTCFailType_77A "UNM";
BA_ "PacketOrder" SG_ 1914 DTCI_DTCFailType_77A 11;
BA_ "SignalLongName" SG_ 1914 DTCI_DTCFailType_77A "Diagnostic Trouble Code Information Extended 77A : Diagnostic Trouble Code Failure Type";
BA_ "VNSigAllNodes" SG_ 1914 DTCI_DTCFailType_77A 1;
BA_ "SignalType" SG_ 1914 DTCI_DTCNumber_77A "UNM";
BA_ "PacketOrder" SG_ 1914 DTCI_DTCNumber_77A 10;
BA_ "SignalLongName" SG_ 1914 DTCI_DTCNumber_77A "Diagnostic Trouble Code Information Extended 77A : Diagnostic Trouble Code Number";
BA_ "VNSigAllNodes" SG_ 1914 DTCI_DTCNumber_77A 1;
BA_ "SignalType" SG_ 1914 DTCI_DTCSource_77A "UNM";
BA_ "PacketOrder" SG_ 1914 DTCI_DTCSource_77A 9;
BA_ "SignalLongName" SG_ 1914 DTCI_DTCSource_77A "Diagnostic Trouble Code Information Extended 77A : Diagnostic Trouble Code Source";
BA_ "VNSigAllNodes" SG_ 1914 DTCI_DTCSource_77A 1;
BA_ "SignalType" SG_ 1914 DTCI_DTCTriggered_77A "BLN";
BA_ "PacketOrder" SG_ 1914 DTCI_DTCTriggered_77A 8;
BA_ "SignalLongName" SG_ 1914 DTCI_DTCTriggered_77A "Diagnostic Trouble Code Information Extended 77A : Diagnostic Trouble Code Triggered";
BA_ "VNSigAllNodes" SG_ 1914 DTCI_DTCTriggered_77A 1;
BA_ "SignalType" SG_ 1914 DTCIUnused7_77A "BLN";
BA_ "PacketOrder" SG_ 1914 DTCIUnused7_77A 7;
BA_ "SignalLongName" SG_ 1914 DTCIUnused7_77A "Diagnostic Trouble Code Information Extended 77A : Unused 7";
BA_ "VNSigAllNodes" SG_ 1914 DTCIUnused7_77A 1;
BA_ "SignalType" SG_ 1914 DTCIUnused6_77A "BLN";
BA_ "PacketOrder" SG_ 1914 DTCIUnused6_77A 6;
BA_ "SignalLongName" SG_ 1914 DTCIUnused6_77A "Diagnostic Trouble Code Information Extended 77A : Unused 6";
BA_ "VNSigAllNodes" SG_ 1914 DTCIUnused6_77A 1;
BA_ "SignalType" SG_ 1914 DTCIUnused5_77A "BLN";
BA_ "PacketOrder" SG_ 1914 DTCIUnused5_77A 5;
BA_ "SignalLongName" SG_ 1914 DTCIUnused5_77A "Diagnostic Trouble Code Information Extended 77A : Unused 5";
BA_ "VNSigAllNodes" SG_ 1914 DTCIUnused5_77A 1;
BA_ "SignalType" SG_ 1914 DTCIUnused4_77A "BLN";
BA_ "PacketOrder" SG_ 1914 DTCIUnused4_77A 4;
BA_ "SignalLongName" SG_ 1914 DTCIUnused4_77A "Diagnostic Trouble Code Information Extended 77A : Unused 4";
BA_ "VNSigAllNodes" SG_ 1914 DTCIUnused4_77A 1;
BA_ "SignalType" SG_ 1914 DTCIUnused3_77A "BLN";
BA_ "PacketOrder" SG_ 1914 DTCIUnused3_77A 3;
BA_ "SignalLongName" SG_ 1914 DTCIUnused3_77A "Diagnostic Trouble Code Information Extended 77A : Unused 3";
BA_ "VNSigAllNodes" SG_ 1914 DTCIUnused3_77A 1;
BA_ "SignalType" SG_ 1914 DTCIUnused2_77A "BLN";
BA_ "PacketOrder" SG_ 1914 DTCIUnused2_77A 2;
BA_ "SignalLongName" SG_ 1914 DTCIUnused2_77A "Diagnostic Trouble Code Information Extended 77A : Unused 2";
BA_ "VNSigAllNodes" SG_ 1914 DTCIUnused2_77A 1;
BA_ "SignalType" SG_ 1914 DTCIUnused1_77A "BLN";
BA_ "PacketOrder" SG_ 1914 DTCIUnused1_77A 1;
BA_ "SignalLongName" SG_ 1914 DTCIUnused1_77A "Diagnostic Trouble Code Information Extended 77A : Unused 1";
BA_ "VNSigAllNodes" SG_ 1914 DTCIUnused1_77A 1;
BA_ "SignalType" SG_ 1911 DTCI_DTCFaultType_777 "ENM";
BA_ "PacketOrder" SG_ 1911 DTCI_DTCFaultType_777 20;
BA_ "SignalLongName" SG_ 1911 DTCI_DTCFaultType_777 "Diagnostic Trouble Code Information Extended 777 : Diagnostic Trouble Code Fault Type";
BA_ "VNSigAllNodes" SG_ 1911 DTCI_DTCFaultType_777 1;
BA_ "SignalType" SG_ 1911 DTCI_CodeSupported_777 "BLN";
BA_ "PacketOrder" SG_ 1911 DTCI_CodeSupported_777 19;
BA_ "SignalLongName" SG_ 1911 DTCI_CodeSupported_777 "Diagnostic Trouble Code Information Extended 777 : Code Supported";
BA_ "VNSigAllNodes" SG_ 1911 DTCI_CodeSupported_777 1;
BA_ "SignalType" SG_ 1911 DTCI_CurrentStatus_777 "BLN";
BA_ "PacketOrder" SG_ 1911 DTCI_CurrentStatus_777 18;
BA_ "SignalLongName" SG_ 1911 DTCI_CurrentStatus_777 "Diagnostic Trouble Code Information Extended 777 : Current Status";
BA_ "VNSigAllNodes" SG_ 1911 DTCI_CurrentStatus_777 1;
BA_ "SignalType" SG_ 1911 DTCI_TstNPsdCdClrdSt_777 "BLN";
BA_ "PacketOrder" SG_ 1911 DTCI_TstNPsdCdClrdSt_777 17;
BA_ "SignalLongName" SG_ 1911 DTCI_TstNPsdCdClrdSt_777 "Diagnostic Trouble Code Information Extended 777 : Test Not Passed Since Code Cleared Status";
BA_ "VNSigAllNodes" SG_ 1911 DTCI_TstNPsdCdClrdSt_777 1;
BA_ "SignalType" SG_ 1911 DTCI_TstFldCdClrdStat_777 "BLN";
BA_ "PacketOrder" SG_ 1911 DTCI_TstFldCdClrdStat_777 16;
BA_ "SignalLongName" SG_ 1911 DTCI_TstFldCdClrdStat_777 "Diagnostic Trouble Code Information Extended 777 : Test Failed Since Code Cleared Status";
BA_ "VNSigAllNodes" SG_ 1911 DTCI_TstFldCdClrdStat_777 1;
BA_ "SignalType" SG_ 1911 DTCI_HistStat_777 "BLN";
BA_ "PacketOrder" SG_ 1911 DTCI_HistStat_777 15;
BA_ "SignalLongName" SG_ 1911 DTCI_HistStat_777 "Diagnostic Trouble Code Information Extended 777 : History Status";
BA_ "VNSigAllNodes" SG_ 1911 DTCI_HistStat_777 1;
BA_ "SignalType" SG_ 1911 DTCI_TstNPsdPwrUpSt_777 "BLN";
BA_ "PacketOrder" SG_ 1911 DTCI_TstNPsdPwrUpSt_777 14;
BA_ "SignalLongName" SG_ 1911 DTCI_TstNPsdPwrUpSt_777 "Diagnostic Trouble Code Information Extended 777 : Test Not Passed Since Power Up Status";
BA_ "VNSigAllNodes" SG_ 1911 DTCI_TstNPsdPwrUpSt_777 1;
BA_ "SignalType" SG_ 1911 DTCI_TstFldPwrUpSt_777 "BLN";
BA_ "PacketOrder" SG_ 1911 DTCI_TstFldPwrUpSt_777 13;
BA_ "SignalLongName" SG_ 1911 DTCI_TstFldPwrUpSt_777 "Diagnostic Trouble Code Information Extended 777 : Test Failed Since Power Up Status";
BA_ "VNSigAllNodes" SG_ 1911 DTCI_TstFldPwrUpSt_777 1;
BA_ "SignalType" SG_ 1911 DTCI_WrnIndRqdSt_777 "BLN";
BA_ "PacketOrder" SG_ 1911 DTCI_WrnIndRqdSt_777 12;
BA_ "SignalLongName" SG_ 1911 DTCI_WrnIndRqdSt_777 "Diagnostic Trouble Code Information Extended 777 : Warning Indicator Requested Status";
BA_ "VNSigAllNodes" SG_ 1911 DTCI_WrnIndRqdSt_777 1;
BA_ "SignalType" SG_ 1911 DTCI_DTCFailType_777 "UNM";
BA_ "PacketOrder" SG_ 1911 DTCI_DTCFailType_777 11;
BA_ "SignalLongName" SG_ 1911 DTCI_DTCFailType_777 "Diagnostic Trouble Code Information Extended 777 : Diagnostic Trouble Code Failure Type";
BA_ "VNSigAllNodes" SG_ 1911 DTCI_DTCFailType_777 1;
BA_ "SignalType" SG_ 1911 DTCI_DTCNumber_777 "UNM";
BA_ "PacketOrder" SG_ 1911 DTCI_DTCNumber_777 10;
BA_ "SignalLongName" SG_ 1911 DTCI_DTCNumber_777 "Diagnostic Trouble Code Information Extended 777 : Diagnostic Trouble Code Number";
BA_ "VNSigAllNodes" SG_ 1911 DTCI_DTCNumber_777 1;
BA_ "SignalType" SG_ 1911 DTCI_DTCSource_777 "UNM";
BA_ "PacketOrder" SG_ 1911 DTCI_DTCSource_777 9;
BA_ "SignalLongName" SG_ 1911 DTCI_DTCSource_777 "Diagnostic Trouble Code Information Extended 777 : Diagnostic Trouble Code Source";
BA_ "VNSigAllNodes" SG_ 1911 DTCI_DTCSource_777 1;
BA_ "SignalType" SG_ 1911 DTCI_DTCTriggered_777 "BLN";
BA_ "PacketOrder" SG_ 1911 DTCI_DTCTriggered_777 8;
BA_ "SignalLongName" SG_ 1911 DTCI_DTCTriggered_777 "Diagnostic Trouble Code Information Extended 777 : Diagnostic Trouble Code Triggered";
BA_ "VNSigAllNodes" SG_ 1911 DTCI_DTCTriggered_777 1;
BA_ "SignalType" SG_ 1911 DTCIUnused7_777 "BLN";
BA_ "PacketOrder" SG_ 1911 DTCIUnused7_777 7;
BA_ "SignalLongName" SG_ 1911 DTCIUnused7_777 "Diagnostic Trouble Code Information Extended 777 : Unused 7";
BA_ "VNSigAllNodes" SG_ 1911 DTCIUnused7_777 1;
BA_ "SignalType" SG_ 1911 DTCIUnused6_777 "BLN";
BA_ "PacketOrder" SG_ 1911 DTCIUnused6_777 6;
BA_ "SignalLongName" SG_ 1911 DTCIUnused6_777 "Diagnostic Trouble Code Information Extended 777 : Unused 6";
BA_ "VNSigAllNodes" SG_ 1911 DTCIUnused6_777 1;
BA_ "SignalType" SG_ 1911 DTCIUnused5_777 "BLN";
BA_ "PacketOrder" SG_ 1911 DTCIUnused5_777 5;
BA_ "SignalLongName" SG_ 1911 DTCIUnused5_777 "Diagnostic Trouble Code Information Extended 777 : Unused 5";
BA_ "VNSigAllNodes" SG_ 1911 DTCIUnused5_777 1;
BA_ "SignalType" SG_ 1911 DTCIUnused4_777 "BLN";
BA_ "PacketOrder" SG_ 1911 DTCIUnused4_777 4;
BA_ "SignalLongName" SG_ 1911 DTCIUnused4_777 "Diagnostic Trouble Code Information Extended 777 : Unused 4";
BA_ "VNSigAllNodes" SG_ 1911 DTCIUnused4_777 1;
BA_ "SignalType" SG_ 1911 DTCIUnused3_777 "BLN";
BA_ "PacketOrder" SG_ 1911 DTCIUnused3_777 3;
BA_ "SignalLongName" SG_ 1911 DTCIUnused3_777 "Diagnostic Trouble Code Information Extended 777 : Unused 3";
BA_ "VNSigAllNodes" SG_ 1911 DTCIUnused3_777 1;
BA_ "SignalType" SG_ 1911 DTCIUnused2_777 "BLN";
BA_ "PacketOrder" SG_ 1911 DTCIUnused2_777 2;
BA_ "SignalLongName" SG_ 1911 DTCIUnused2_777 "Diagnostic Trouble Code Information Extended 777 : Unused 2";
BA_ "VNSigAllNodes" SG_ 1911 DTCIUnused2_777 1;
BA_ "SignalType" SG_ 1911 DTCIUnused1_777 "BLN";
BA_ "PacketOrder" SG_ 1911 DTCIUnused1_777 1;
BA_ "SignalLongName" SG_ 1911 DTCIUnused1_777 "Diagnostic Trouble Code Information Extended 777 : Unused 1";
BA_ "VNSigAllNodes" SG_ 1911 DTCIUnused1_777 1;
BA_ "VNSigSLHSSharedDiagnostic" SG_ 583 DgnInf 1;
BA_ "SignalType" SG_ 583 DgnInf "UNM";
BA_ "SignalLongName" SG_ 583 DgnInf "Diagnostic Information";
BA_ "VNSigAllNodes" SG_ 583 DgnInf 1;
BA_ "VNSigSLHSSharedDiagnostic" SG_ 1351 DgnInf_HS547 1;
BA_ "SignalType" SG_ 1351 DgnInf_HS547 "UNM";
BA_ "SignalLongName" SG_ 1351 DgnInf_HS547 "Diagnostic Information HS547";
BA_ "VNSigAllNodes" SG_ 1351 DgnInf_HS547 1;
BA_ "VNSigSLHSSharedDiagnostic" SG_ 1607 DgnInf 1;
BA_ "SignalType" SG_ 1607 DgnInf "UNM";
BA_ "SignalLongName" SG_ 1607 DgnInf "Diagnostic Information";
BA_ "VNSigAllNodes" SG_ 1607 DgnInf 1;
BA_ "SignalType" SG_ 1906 DTCI_DTCFaultType_772 "ENM";
BA_ "PacketOrder" SG_ 1906 DTCI_DTCFaultType_772 20;
BA_ "SignalLongName" SG_ 1906 DTCI_DTCFaultType_772 "Diagnostic Trouble Code Information Extended 772 : Diagnostic Trouble Code Fault Type";
BA_ "VNSigAllNodes" SG_ 1906 DTCI_DTCFaultType_772 1;
BA_ "SignalType" SG_ 1906 DTCI_CodeSupported_772 "BLN";
BA_ "PacketOrder" SG_ 1906 DTCI_CodeSupported_772 19;
BA_ "SignalLongName" SG_ 1906 DTCI_CodeSupported_772 "Diagnostic Trouble Code Information Extended 772 : Code Supported";
BA_ "VNSigAllNodes" SG_ 1906 DTCI_CodeSupported_772 1;
BA_ "SignalType" SG_ 1906 DTCI_CurrentStatus_772 "BLN";
BA_ "PacketOrder" SG_ 1906 DTCI_CurrentStatus_772 18;
BA_ "SignalLongName" SG_ 1906 DTCI_CurrentStatus_772 "Diagnostic Trouble Code Information Extended 772 : Current Status";
BA_ "VNSigAllNodes" SG_ 1906 DTCI_CurrentStatus_772 1;
BA_ "SignalType" SG_ 1906 DTCI_TstNPsdCdClrdSt_772 "BLN";
BA_ "PacketOrder" SG_ 1906 DTCI_TstNPsdCdClrdSt_772 17;
BA_ "SignalLongName" SG_ 1906 DTCI_TstNPsdCdClrdSt_772 "Diagnostic Trouble Code Information Extended 772 : Test Not Passed Since Code Cleared Status";
BA_ "VNSigAllNodes" SG_ 1906 DTCI_TstNPsdCdClrdSt_772 1;
BA_ "SignalType" SG_ 1906 DTCI_TstFldCdClrdStat_772 "BLN";
BA_ "PacketOrder" SG_ 1906 DTCI_TstFldCdClrdStat_772 16;
BA_ "SignalLongName" SG_ 1906 DTCI_TstFldCdClrdStat_772 "Diagnostic Trouble Code Information Extended 772 : Test Failed Since Code Cleared Status";
BA_ "VNSigAllNodes" SG_ 1906 DTCI_TstFldCdClrdStat_772 1;
BA_ "SignalType" SG_ 1906 DTCI_HistStat_772 "BLN";
BA_ "PacketOrder" SG_ 1906 DTCI_HistStat_772 15;
BA_ "SignalLongName" SG_ 1906 DTCI_HistStat_772 "Diagnostic Trouble Code Information Extended 772 : History Status";
BA_ "VNSigAllNodes" SG_ 1906 DTCI_HistStat_772 1;
BA_ "SignalType" SG_ 1906 DTCI_TstNPsdPwrUpSt_772 "BLN";
BA_ "PacketOrder" SG_ 1906 DTCI_TstNPsdPwrUpSt_772 14;
BA_ "SignalLongName" SG_ 1906 DTCI_TstNPsdPwrUpSt_772 "Diagnostic Trouble Code Information Extended 772 : Test Not Passed Since Power Up Status";
BA_ "VNSigAllNodes" SG_ 1906 DTCI_TstNPsdPwrUpSt_772 1;
BA_ "SignalType" SG_ 1906 DTCI_TstFldPwrUpSt_772 "BLN";
BA_ "PacketOrder" SG_ 1906 DTCI_TstFldPwrUpSt_772 13;
BA_ "SignalLongName" SG_ 1906 DTCI_TstFldPwrUpSt_772 "Diagnostic Trouble Code Information Extended 772 : Test Failed Since Power Up Status";
BA_ "VNSigAllNodes" SG_ 1906 DTCI_TstFldPwrUpSt_772 1;
BA_ "SignalType" SG_ 1906 DTCI_WrnIndRqdSt_772 "BLN";
BA_ "PacketOrder" SG_ 1906 DTCI_WrnIndRqdSt_772 12;
BA_ "SignalLongName" SG_ 1906 DTCI_WrnIndRqdSt_772 "Diagnostic Trouble Code Information Extended 772 : Warning Indicator Requested Status";
BA_ "VNSigAllNodes" SG_ 1906 DTCI_WrnIndRqdSt_772 1;
BA_ "SignalType" SG_ 1906 DTCI_DTCFailType_772 "UNM";
BA_ "PacketOrder" SG_ 1906 DTCI_DTCFailType_772 11;
BA_ "SignalLongName" SG_ 1906 DTCI_DTCFailType_772 "Diagnostic Trouble Code Information Extended 772 : Diagnostic Trouble Code Failure Type";
BA_ "VNSigAllNodes" SG_ 1906 DTCI_DTCFailType_772 1;
BA_ "SignalType" SG_ 1906 DTCI_DTCNumber_772 "UNM";
BA_ "PacketOrder" SG_ 1906 DTCI_DTCNumber_772 10;
BA_ "SignalLongName" SG_ 1906 DTCI_DTCNumber_772 "Diagnostic Trouble Code Information Extended 772 : Diagnostic Trouble Code Number";
BA_ "VNSigAllNodes" SG_ 1906 DTCI_DTCNumber_772 1;
BA_ "SignalType" SG_ 1906 DTCI_DTCSource_772 "UNM";
BA_ "PacketOrder" SG_ 1906 DTCI_DTCSource_772 9;
BA_ "SignalLongName" SG_ 1906 DTCI_DTCSource_772 "Diagnostic Trouble Code Information Extended 772 : Diagnostic Trouble Code Source";
BA_ "VNSigAllNodes" SG_ 1906 DTCI_DTCSource_772 1;
BA_ "SignalType" SG_ 1906 DTCI_DTCTriggered_772 "BLN";
BA_ "PacketOrder" SG_ 1906 DTCI_DTCTriggered_772 8;
BA_ "SignalLongName" SG_ 1906 DTCI_DTCTriggered_772 "Diagnostic Trouble Code Information Extended 772 : Diagnostic Trouble Code Triggered";
BA_ "VNSigAllNodes" SG_ 1906 DTCI_DTCTriggered_772 1;
BA_ "SignalType" SG_ 1906 DTCIUnused7_772 "BLN";
BA_ "PacketOrder" SG_ 1906 DTCIUnused7_772 7;
BA_ "SignalLongName" SG_ 1906 DTCIUnused7_772 "Diagnostic Trouble Code Information Extended 772 : Unused 7";
BA_ "VNSigAllNodes" SG_ 1906 DTCIUnused7_772 1;
BA_ "SignalType" SG_ 1906 DTCIUnused6_772 "BLN";
BA_ "PacketOrder" SG_ 1906 DTCIUnused6_772 6;
BA_ "SignalLongName" SG_ 1906 DTCIUnused6_772 "Diagnostic Trouble Code Information Extended 772 : Unused 6";
BA_ "VNSigAllNodes" SG_ 1906 DTCIUnused6_772 1;
BA_ "SignalType" SG_ 1906 DTCIUnused5_772 "BLN";
BA_ "PacketOrder" SG_ 1906 DTCIUnused5_772 5;
BA_ "SignalLongName" SG_ 1906 DTCIUnused5_772 "Diagnostic Trouble Code Information Extended 772 : Unused 5";
BA_ "VNSigAllNodes" SG_ 1906 DTCIUnused5_772 1;
BA_ "SignalType" SG_ 1906 DTCIUnused4_772 "BLN";
BA_ "PacketOrder" SG_ 1906 DTCIUnused4_772 4;
BA_ "SignalLongName" SG_ 1906 DTCIUnused4_772 "Diagnostic Trouble Code Information Extended 772 : Unused 4";
BA_ "VNSigAllNodes" SG_ 1906 DTCIUnused4_772 1;
BA_ "SignalType" SG_ 1906 DTCIUnused3_772 "BLN";
BA_ "PacketOrder" SG_ 1906 DTCIUnused3_772 3;
BA_ "SignalLongName" SG_ 1906 DTCIUnused3_772 "Diagnostic Trouble Code Information Extended 772 : Unused 3";
BA_ "VNSigAllNodes" SG_ 1906 DTCIUnused3_772 1;
BA_ "SignalType" SG_ 1906 DTCIUnused2_772 "BLN";
BA_ "PacketOrder" SG_ 1906 DTCIUnused2_772 2;
BA_ "SignalLongName" SG_ 1906 DTCIUnused2_772 "Diagnostic Trouble Code Information Extended 772 : Unused 2";
BA_ "VNSigAllNodes" SG_ 1906 DTCIUnused2_772 1;
BA_ "SignalType" SG_ 1906 DTCIUnused1_772 "BLN";
BA_ "PacketOrder" SG_ 1906 DTCIUnused1_772 1;
BA_ "SignalLongName" SG_ 1906 DTCIUnused1_772 "Diagnostic Trouble Code Information Extended 772 : Unused 1";
BA_ "VNSigAllNodes" SG_ 1906 DTCIUnused1_772 1;
BA_ "SignalType" SG_ 1907 DTCI_DTCFaultType_773 "ENM";
BA_ "PacketOrder" SG_ 1907 DTCI_DTCFaultType_773 20;
BA_ "SignalLongName" SG_ 1907 DTCI_DTCFaultType_773 "Diagnostic Trouble Code Information Extended 773 : Diagnostic Trouble Code Fault Type";
BA_ "VNSigAllNodes" SG_ 1907 DTCI_DTCFaultType_773 1;
BA_ "SignalType" SG_ 1907 DTCI_CodeSupported_773 "BLN";
BA_ "PacketOrder" SG_ 1907 DTCI_CodeSupported_773 19;
BA_ "SignalLongName" SG_ 1907 DTCI_CodeSupported_773 "Diagnostic Trouble Code Information Extended 773 : Code Supported";
BA_ "VNSigAllNodes" SG_ 1907 DTCI_CodeSupported_773 1;
BA_ "SignalType" SG_ 1907 DTCI_CurrentStatus_773 "BLN";
BA_ "PacketOrder" SG_ 1907 DTCI_CurrentStatus_773 18;
BA_ "SignalLongName" SG_ 1907 DTCI_CurrentStatus_773 "Diagnostic Trouble Code Information Extended 773 : Current Status";
BA_ "VNSigAllNodes" SG_ 1907 DTCI_CurrentStatus_773 1;
BA_ "SignalType" SG_ 1907 DTCI_TstNPsdCdClrdSt_773 "BLN";
BA_ "PacketOrder" SG_ 1907 DTCI_TstNPsdCdClrdSt_773 17;
BA_ "SignalLongName" SG_ 1907 DTCI_TstNPsdCdClrdSt_773 "Diagnostic Trouble Code Information Extended 773 : Test Not Passed Since Code Cleared Status";
BA_ "VNSigAllNodes" SG_ 1907 DTCI_TstNPsdCdClrdSt_773 1;
BA_ "SignalType" SG_ 1907 DTCI_TstFldCdClrdStat_773 "BLN";
BA_ "PacketOrder" SG_ 1907 DTCI_TstFldCdClrdStat_773 16;
BA_ "SignalLongName" SG_ 1907 DTCI_TstFldCdClrdStat_773 "Diagnostic Trouble Code Information Extended 773 : Test Failed Since Code Cleared Status";
BA_ "VNSigAllNodes" SG_ 1907 DTCI_TstFldCdClrdStat_773 1;
BA_ "SignalType" SG_ 1907 DTCI_HistStat_773 "BLN";
BA_ "PacketOrder" SG_ 1907 DTCI_HistStat_773 15;
BA_ "SignalLongName" SG_ 1907 DTCI_HistStat_773 "Diagnostic Trouble Code Information Extended 773 : History Status";
BA_ "VNSigAllNodes" SG_ 1907 DTCI_HistStat_773 1;
BA_ "SignalType" SG_ 1907 DTCI_TstNPsdPwrUpSt_773 "BLN";
BA_ "PacketOrder" SG_ 1907 DTCI_TstNPsdPwrUpSt_773 14;
BA_ "SignalLongName" SG_ 1907 DTCI_TstNPsdPwrUpSt_773 "Diagnostic Trouble Code Information Extended 773 : Test Not Passed Since Power Up Status";
BA_ "VNSigAllNodes" SG_ 1907 DTCI_TstNPsdPwrUpSt_773 1;
BA_ "SignalType" SG_ 1907 DTCI_TstFldPwrUpSt_773 "BLN";
BA_ "PacketOrder" SG_ 1907 DTCI_TstFldPwrUpSt_773 13;
BA_ "SignalLongName" SG_ 1907 DTCI_TstFldPwrUpSt_773 "Diagnostic Trouble Code Information Extended 773 : Test Failed Since Power Up Status";
BA_ "VNSigAllNodes" SG_ 1907 DTCI_TstFldPwrUpSt_773 1;
BA_ "SignalType" SG_ 1907 DTCI_WrnIndRqdSt_773 "BLN";
BA_ "PacketOrder" SG_ 1907 DTCI_WrnIndRqdSt_773 12;
BA_ "SignalLongName" SG_ 1907 DTCI_WrnIndRqdSt_773 "Diagnostic Trouble Code Information Extended 773 : Warning Indicator Requested Status";
BA_ "VNSigAllNodes" SG_ 1907 DTCI_WrnIndRqdSt_773 1;
BA_ "SignalType" SG_ 1907 DTCI_DTCFailType_773 "UNM";
BA_ "PacketOrder" SG_ 1907 DTCI_DTCFailType_773 11;
BA_ "SignalLongName" SG_ 1907 DTCI_DTCFailType_773 "Diagnostic Trouble Code Information Extended 773 : Diagnostic Trouble Code Failure Type";
BA_ "VNSigAllNodes" SG_ 1907 DTCI_DTCFailType_773 1;
BA_ "SignalType" SG_ 1907 DTCI_DTCNumber_773 "UNM";
BA_ "PacketOrder" SG_ 1907 DTCI_DTCNumber_773 10;
BA_ "SignalLongName" SG_ 1907 DTCI_DTCNumber_773 "Diagnostic Trouble Code Information Extended 773 : Diagnostic Trouble Code Number";
BA_ "VNSigAllNodes" SG_ 1907 DTCI_DTCNumber_773 1;
BA_ "SignalType" SG_ 1907 DTCI_DTCSource_773 "UNM";
BA_ "PacketOrder" SG_ 1907 DTCI_DTCSource_773 9;
BA_ "SignalLongName" SG_ 1907 DTCI_DTCSource_773 "Diagnostic Trouble Code Information Extended 773 : Diagnostic Trouble Code Source";
BA_ "VNSigAllNodes" SG_ 1907 DTCI_DTCSource_773 1;
BA_ "SignalType" SG_ 1907 DTCI_DTCTriggered_773 "BLN";
BA_ "PacketOrder" SG_ 1907 DTCI_DTCTriggered_773 8;
BA_ "SignalLongName" SG_ 1907 DTCI_DTCTriggered_773 "Diagnostic Trouble Code Information Extended 773 : Diagnostic Trouble Code Triggered";
BA_ "VNSigAllNodes" SG_ 1907 DTCI_DTCTriggered_773 1;
BA_ "SignalType" SG_ 1907 DTCIUnused7_773 "BLN";
BA_ "PacketOrder" SG_ 1907 DTCIUnused7_773 7;
BA_ "SignalLongName" SG_ 1907 DTCIUnused7_773 "Diagnostic Trouble Code Information Extended 773 : Unused 7";
BA_ "VNSigAllNodes" SG_ 1907 DTCIUnused7_773 1;
BA_ "SignalType" SG_ 1907 DTCIUnused6_773 "BLN";
BA_ "PacketOrder" SG_ 1907 DTCIUnused6_773 6;
BA_ "SignalLongName" SG_ 1907 DTCIUnused6_773 "Diagnostic Trouble Code Information Extended 773 : Unused 6";
BA_ "VNSigAllNodes" SG_ 1907 DTCIUnused6_773 1;
BA_ "SignalType" SG_ 1907 DTCIUnused5_773 "BLN";
BA_ "PacketOrder" SG_ 1907 DTCIUnused5_773 5;
BA_ "SignalLongName" SG_ 1907 DTCIUnused5_773 "Diagnostic Trouble Code Information Extended 773 : Unused 5";
BA_ "VNSigAllNodes" SG_ 1907 DTCIUnused5_773 1;
BA_ "SignalType" SG_ 1907 DTCIUnused4_773 "BLN";
BA_ "PacketOrder" SG_ 1907 DTCIUnused4_773 4;
BA_ "SignalLongName" SG_ 1907 DTCIUnused4_773 "Diagnostic Trouble Code Information Extended 773 : Unused 4";
BA_ "VNSigAllNodes" SG_ 1907 DTCIUnused4_773 1;
BA_ "SignalType" SG_ 1907 DTCIUnused3_773 "BLN";
BA_ "PacketOrder" SG_ 1907 DTCIUnused3_773 3;
BA_ "SignalLongName" SG_ 1907 DTCIUnused3_773 "Diagnostic Trouble Code Information Extended 773 : Unused 3";
BA_ "VNSigAllNodes" SG_ 1907 DTCIUnused3_773 1;
BA_ "SignalType" SG_ 1907 DTCIUnused2_773 "BLN";
BA_ "PacketOrder" SG_ 1907 DTCIUnused2_773 2;
BA_ "SignalLongName" SG_ 1907 DTCIUnused2_773 "Diagnostic Trouble Code Information Extended 773 : Unused 2";
BA_ "VNSigAllNodes" SG_ 1907 DTCIUnused2_773 1;
BA_ "SignalType" SG_ 1907 DTCIUnused1_773 "BLN";
BA_ "PacketOrder" SG_ 1907 DTCIUnused1_773 1;
BA_ "SignalLongName" SG_ 1907 DTCIUnused1_773 "Diagnostic Trouble Code Information Extended 773 : Unused 1";
BA_ "VNSigAllNodes" SG_ 1907 DTCIUnused1_773 1;
BA_ "VNSigSLHSSharedDiagnostic" SG_ 579 DgnInf 1;
BA_ "SignalType" SG_ 579 DgnInf "UNM";
BA_ "SignalLongName" SG_ 579 DgnInf "Diagnostic Information";
BA_ "VNSigAllNodes" SG_ 579 DgnInf 1;
BA_ "VNSigSLHSSharedDiagnostic" SG_ 1603 DgnInf 1;
BA_ "SignalType" SG_ 1603 DgnInf "UNM";
BA_ "SignalLongName" SG_ 1603 DgnInf "Diagnostic Information";
BA_ "VNSigAllNodes" SG_ 1603 DgnInf 1;
BA_ "VNSigSLHSSharedDiagnostic" SG_ 1347 DgnInf_HS543 1;
BA_ "SignalType" SG_ 1347 DgnInf_HS543 "UNM";
BA_ "SignalLongName" SG_ 1347 DgnInf_HS543 "Diagnostic Information HS543";
BA_ "VNSigAllNodes" SG_ 1347 DgnInf_HS543 1;
BA_ "SignalType" SG_ 1915 DTCI_DTCFaultType_77B "ENM";
BA_ "PacketOrder" SG_ 1915 DTCI_DTCFaultType_77B 20;
BA_ "SignalLongName" SG_ 1915 DTCI_DTCFaultType_77B "Diagnostic Trouble Code Information Extended 77B : Diagnostic Trouble Code Fault Type";
BA_ "VNSigAllNodes" SG_ 1915 DTCI_DTCFaultType_77B 1;
BA_ "SignalType" SG_ 1915 DTCI_CodeSupported_77B "BLN";
BA_ "PacketOrder" SG_ 1915 DTCI_CodeSupported_77B 19;
BA_ "SignalLongName" SG_ 1915 DTCI_CodeSupported_77B "Diagnostic Trouble Code Information Extended 77B : Code Supported";
BA_ "VNSigAllNodes" SG_ 1915 DTCI_CodeSupported_77B 1;
BA_ "SignalType" SG_ 1915 DTCI_CurrentStatus_77B "BLN";
BA_ "PacketOrder" SG_ 1915 DTCI_CurrentStatus_77B 18;
BA_ "SignalLongName" SG_ 1915 DTCI_CurrentStatus_77B "Diagnostic Trouble Code Information Extended 77B : Current Status";
BA_ "VNSigAllNodes" SG_ 1915 DTCI_CurrentStatus_77B 1;
BA_ "SignalType" SG_ 1915 DTCI_TstNPsdCdClrdSt_77B "BLN";
BA_ "PacketOrder" SG_ 1915 DTCI_TstNPsdCdClrdSt_77B 17;
BA_ "SignalLongName" SG_ 1915 DTCI_TstNPsdCdClrdSt_77B "Diagnostic Trouble Code Information Extended 77B : Test Not Passed Since Code Cleared Status";
BA_ "VNSigAllNodes" SG_ 1915 DTCI_TstNPsdCdClrdSt_77B 1;
BA_ "SignalType" SG_ 1915 DTCI_TstFldCdClrdStat_77B "BLN";
BA_ "PacketOrder" SG_ 1915 DTCI_TstFldCdClrdStat_77B 16;
BA_ "SignalLongName" SG_ 1915 DTCI_TstFldCdClrdStat_77B "Diagnostic Trouble Code Information Extended 77B : Test Failed Since Code Cleared Status";
BA_ "VNSigAllNodes" SG_ 1915 DTCI_TstFldCdClrdStat_77B 1;
BA_ "SignalType" SG_ 1915 DTCI_HistStat_77B "BLN";
BA_ "PacketOrder" SG_ 1915 DTCI_HistStat_77B 15;
BA_ "SignalLongName" SG_ 1915 DTCI_HistStat_77B "Diagnostic Trouble Code Information Extended 77B : History Status";
BA_ "VNSigAllNodes" SG_ 1915 DTCI_HistStat_77B 1;
BA_ "SignalType" SG_ 1915 DTCI_TstNPsdPwrUpSt_77B "BLN";
BA_ "PacketOrder" SG_ 1915 DTCI_TstNPsdPwrUpSt_77B 14;
BA_ "SignalLongName" SG_ 1915 DTCI_TstNPsdPwrUpSt_77B "Diagnostic Trouble Code Information Extended 77B : Test Not Passed Since Power Up Status";
BA_ "VNSigAllNodes" SG_ 1915 DTCI_TstNPsdPwrUpSt_77B 1;
BA_ "SignalType" SG_ 1915 DTCI_TstFldPwrUpSt_77B "BLN";
BA_ "PacketOrder" SG_ 1915 DTCI_TstFldPwrUpSt_77B 13;
BA_ "SignalLongName" SG_ 1915 DTCI_TstFldPwrUpSt_77B "Diagnostic Trouble Code Information Extended 77B : Test Failed Since Power Up Status";
BA_ "VNSigAllNodes" SG_ 1915 DTCI_TstFldPwrUpSt_77B 1;
BA_ "SignalType" SG_ 1915 DTCI_WrnIndRqdSt_77B "BLN";
BA_ "PacketOrder" SG_ 1915 DTCI_WrnIndRqdSt_77B 12;
BA_ "SignalLongName" SG_ 1915 DTCI_WrnIndRqdSt_77B "Diagnostic Trouble Code Information Extended 77B : Warning Indicator Requested Status";
BA_ "VNSigAllNodes" SG_ 1915 DTCI_WrnIndRqdSt_77B 1;
BA_ "SignalType" SG_ 1915 DTCI_DTCFailType_77B "UNM";
BA_ "PacketOrder" SG_ 1915 DTCI_DTCFailType_77B 11;
BA_ "SignalLongName" SG_ 1915 DTCI_DTCFailType_77B "Diagnostic Trouble Code Information Extended 77B : Diagnostic Trouble Code Failure Type";
BA_ "VNSigAllNodes" SG_ 1915 DTCI_DTCFailType_77B 1;
BA_ "SignalType" SG_ 1915 DTCI_DTCNumber_77B "UNM";
BA_ "PacketOrder" SG_ 1915 DTCI_DTCNumber_77B 10;
BA_ "SignalLongName" SG_ 1915 DTCI_DTCNumber_77B "Diagnostic Trouble Code Information Extended 77B : Diagnostic Trouble Code Number";
BA_ "VNSigAllNodes" SG_ 1915 DTCI_DTCNumber_77B 1;
BA_ "SignalType" SG_ 1915 DTCI_DTCSource_77B "UNM";
BA_ "PacketOrder" SG_ 1915 DTCI_DTCSource_77B 9;
BA_ "SignalLongName" SG_ 1915 DTCI_DTCSource_77B "Diagnostic Trouble Code Information Extended 77B : Diagnostic Trouble Code Source";
BA_ "VNSigAllNodes" SG_ 1915 DTCI_DTCSource_77B 1;
BA_ "SignalType" SG_ 1915 DTCI_DTCTriggered_77B "BLN";
BA_ "PacketOrder" SG_ 1915 DTCI_DTCTriggered_77B 8;
BA_ "SignalLongName" SG_ 1915 DTCI_DTCTriggered_77B "Diagnostic Trouble Code Information Extended 77B : Diagnostic Trouble Code Triggered";
BA_ "VNSigAllNodes" SG_ 1915 DTCI_DTCTriggered_77B 1;
BA_ "SignalType" SG_ 1915 DTCIUnused7_77B "BLN";
BA_ "PacketOrder" SG_ 1915 DTCIUnused7_77B 7;
BA_ "SignalLongName" SG_ 1915 DTCIUnused7_77B "Diagnostic Trouble Code Information Extended 77B : Unused 7";
BA_ "VNSigAllNodes" SG_ 1915 DTCIUnused7_77B 1;
BA_ "SignalType" SG_ 1915 DTCIUnused6_77B "BLN";
BA_ "PacketOrder" SG_ 1915 DTCIUnused6_77B 6;
BA_ "SignalLongName" SG_ 1915 DTCIUnused6_77B "Diagnostic Trouble Code Information Extended 77B : Unused 6";
BA_ "VNSigAllNodes" SG_ 1915 DTCIUnused6_77B 1;
BA_ "SignalType" SG_ 1915 DTCIUnused5_77B "BLN";
BA_ "PacketOrder" SG_ 1915 DTCIUnused5_77B 5;
BA_ "SignalLongName" SG_ 1915 DTCIUnused5_77B "Diagnostic Trouble Code Information Extended 77B : Unused 5";
BA_ "VNSigAllNodes" SG_ 1915 DTCIUnused5_77B 1;
BA_ "SignalType" SG_ 1915 DTCIUnused4_77B "BLN";
BA_ "PacketOrder" SG_ 1915 DTCIUnused4_77B 4;
BA_ "SignalLongName" SG_ 1915 DTCIUnused4_77B "Diagnostic Trouble Code Information Extended 77B : Unused 4";
BA_ "VNSigAllNodes" SG_ 1915 DTCIUnused4_77B 1;
BA_ "SignalType" SG_ 1915 DTCIUnused3_77B "BLN";
BA_ "PacketOrder" SG_ 1915 DTCIUnused3_77B 3;
BA_ "SignalLongName" SG_ 1915 DTCIUnused3_77B "Diagnostic Trouble Code Information Extended 77B : Unused 3";
BA_ "VNSigAllNodes" SG_ 1915 DTCIUnused3_77B 1;
BA_ "SignalType" SG_ 1915 DTCIUnused2_77B "BLN";
BA_ "PacketOrder" SG_ 1915 DTCIUnused2_77B 2;
BA_ "SignalLongName" SG_ 1915 DTCIUnused2_77B "Diagnostic Trouble Code Information Extended 77B : Unused 2";
BA_ "VNSigAllNodes" SG_ 1915 DTCIUnused2_77B 1;
BA_ "SignalType" SG_ 1915 DTCIUnused1_77B "BLN";
BA_ "PacketOrder" SG_ 1915 DTCIUnused1_77B 1;
BA_ "SignalLongName" SG_ 1915 DTCIUnused1_77B "Diagnostic Trouble Code Information Extended 77B : Unused 1";
BA_ "VNSigAllNodes" SG_ 1915 DTCIUnused1_77B 1;
BA_ "VNSigSLHSSharedDiagnostic" SG_ 587 DgnInf 1;
BA_ "SignalType" SG_ 587 DgnInf "UNM";
BA_ "SignalLongName" SG_ 587 DgnInf "Diagnostic Information";
BA_ "VNSigAllNodes" SG_ 587 DgnInf 1;
BA_ "VNSigSLHSSharedDiagnostic" SG_ 1611 DgnInf 1;
BA_ "SignalType" SG_ 1611 DgnInf "UNM";
BA_ "SignalLongName" SG_ 1611 DgnInf "Diagnostic Information";
BA_ "VNSigAllNodes" SG_ 1611 DgnInf 1;
BA_ "VNSigSLHSSharedDiagnostic" SG_ 1355 DgnInf_HS54B 1;
BA_ "SignalType" SG_ 1355 DgnInf_HS54B "UNM";
BA_ "SignalLongName" SG_ 1355 DgnInf_HS54B "Diagnostic Information HS54B";
BA_ "VNSigAllNodes" SG_ 1355 DgnInf_HS54B 1;
BA_REL_ "GenSigRxStartValue" BU_SG_REL_ TCM_HS SG_ 499 PTShftPtrnOvrdAct "False";
BA_REL_ "GenSigSuprvResp" BU_SG_REL_ HCP_T_HS SG_ 499 PFTrnsTUDSecSwSt 1;
BA_REL_ "GenSigTimeoutMsg" BU_SG_REL_ HCP_T_HS SG_ 499 PFTrnsTUDSecSwSt 499;
BA_REL_ "GenSigTimeoutTime" BU_SG_REL_ HCP_T_HS SG_ 499 PFTrnsTUDSecSwSt 250;
BA_REL_ "GenSigRxStartValue" BU_SG_REL_ TCM_HS SG_ 499 PFTrnsTUDSecSwSt "$0 - No Activation";
BA_REL_ "GenSigSuprvResp" BU_SG_REL_ HCP_T_HS SG_ 499 TrnsPFShftPattSwARC 1;
BA_REL_ "GenSigTimeoutMsg" BU_SG_REL_ HCP_T_HS SG_ 499 TrnsPFShftPattSwARC 499;
BA_REL_ "GenSigTimeoutTime" BU_SG_REL_ HCP_T_HS SG_ 499 TrnsPFShftPattSwARC 250;
BA_REL_ "GenSigSuprvResp" BU_SG_REL_ HCP_T_HS SG_ 499 TrnsPFShftPattSw4Act 1;
BA_REL_ "GenSigTimeoutMsg" BU_SG_REL_ HCP_T_HS SG_ 499 TrnsPFShftPattSw4Act 499;
BA_REL_ "GenSigTimeoutTime" BU_SG_REL_ HCP_T_HS SG_ 499 TrnsPFShftPattSw4Act 250;
BA_REL_ "GenSigRxStartValue" BU_SG_REL_ ECM_HS SG_ 499 TrnsPFShftPattSw4Act "False";
BA_REL_ "GenSigRxStartValue" BU_SG_REL_ TCM_HS SG_ 499 TrnsPFShftPattSw4Act "False";
BA_REL_ "GenSigSuprvResp" BU_SG_REL_ HCP_T_HS SG_ 499 TrnsPFShftPattSw3Act 1;
BA_REL_ "GenSigTimeoutMsg" BU_SG_REL_ HCP_T_HS SG_ 499 TrnsPFShftPattSw3Act 499;
BA_REL_ "GenSigTimeoutTime" BU_SG_REL_ HCP_T_HS SG_ 499 TrnsPFShftPattSw3Act 250;
BA_REL_ "GenSigRxStartValue" BU_SG_REL_ ECM_HS SG_ 499 TrnsPFShftPattSw3Act "False";
BA_REL_ "GenSigRxStartValue" BU_SG_REL_ TCM_HS SG_ 499 TrnsPFShftPattSw3Act "False";
BA_REL_ "GenSigSuprvResp" BU_SG_REL_ HCP_T_HS SG_ 499 TrnsPFShftPattSw2Act 1;
BA_REL_ "GenSigTimeoutMsg" BU_SG_REL_ HCP_T_HS SG_ 499 TrnsPFShftPattSw2Act 499;
BA_REL_ "GenSigTimeoutTime" BU_SG_REL_ HCP_T_HS SG_ 499 TrnsPFShftPattSw2Act 250;
BA_REL_ "GenSigRxStartValue" BU_SG_REL_ ECM_HS SG_ 499 TrnsPFShftPattSw2Act "False";
BA_REL_ "GenSigRxStartValue" BU_SG_REL_ TCM_HS SG_ 499 TrnsPFShftPattSw2Act "False";
BA_REL_ "GenSigSuprvResp" BU_SG_REL_ HCP_T_HS SG_ 499 TrnsPFShftPattSw1Act 1;
BA_REL_ "GenSigTimeoutMsg" BU_SG_REL_ HCP_T_HS SG_ 499 TrnsPFShftPattSw1Act 499;
BA_REL_ "GenSigTimeoutTime" BU_SG_REL_ HCP_T_HS SG_ 499 TrnsPFShftPattSw1Act 250;
BA_REL_ "GenSigRxStartValue" BU_SG_REL_ ECM_HS SG_ 499 TrnsPFShftPattSw1Act "False";
BA_REL_ "GenSigRxStartValue" BU_SG_REL_ TCM_HS SG_ 499 TrnsPFShftPattSw1Act "False";
BA_REL_ "GenSigSuprvResp" BU_SG_REL_ HCP_T_HS SG_ 499 PFTrnsTUDSwStAlvRC 1;
BA_REL_ "GenSigTimeoutMsg" BU_SG_REL_ HCP_T_HS SG_ 499 PFTrnsTUDSwStAlvRC 499;
BA_REL_ "GenSigTimeoutTime" BU_SG_REL_ HCP_T_HS SG_ 499 PFTrnsTUDSwStAlvRC 250;
BA_REL_ "GenSigSuprvResp" BU_SG_REL_ HCP_T_HS SG_ 499 PFTrnsTUDSwSt 1;
BA_REL_ "GenSigTimeoutMsg" BU_SG_REL_ HCP_T_HS SG_ 499 PFTrnsTUDSwSt 499;
BA_REL_ "GenSigTimeoutTime" BU_SG_REL_ HCP_T_HS SG_ 499 PFTrnsTUDSwSt 250;
BA_REL_ "GenSigRxStartValue" BU_SG_REL_ TCM_HS SG_ 499 PFTrnsTUDSwSt "$0 - No Activation";
BA_REL_ "GenSigSuprvResp" BU_SG_REL_ HCP_T_HS SG_ 499 PFTrnsTUDEnSwSt 1;
BA_REL_ "GenSigTimeoutMsg" BU_SG_REL_ HCP_T_HS SG_ 499 PFTrnsTUDEnSwSt 499;
BA_REL_ "GenSigTimeoutTime" BU_SG_REL_ HCP_T_HS SG_ 499 PFTrnsTUDEnSwSt 250;
BA_REL_ "GenSigRxStartValue" BU_SG_REL_ TCM_HS SG_ 499 PFTrnsTUDEnSwSt "$0 - No Activation";
BA_REL_ "GenSigSuprvResp" BU_SG_REL_ BSM_HS SG_ 495 MassAirFlo 1;
BA_REL_ "GenSigTimeoutMsg" BU_SG_REL_ BSM_HS SG_ 495 MassAirFlo 495;
BA_REL_ "GenSigTimeoutTime" BU_SG_REL_ BSM_HS SG_ 495 MassAirFlo 31;
BA_REL_ "GenSigSuprvResp" BU_SG_REL_ VICM_HS SG_ 495 MassAirFlo 1;
BA_REL_ "GenSigTimeoutMsg" BU_SG_REL_ VICM_HS SG_ 495 MassAirFlo 495;
BA_REL_ "GenSigTimeoutTime" BU_SG_REL_ VICM_HS SG_ 495 MassAirFlo 31;
VAL_ 1904 DTCI_WrnIndRqdSt_770 1 "true" 0 "false" ;
VAL_ 1904 DTCIUnused7_770 1 "true" 0 "false" ;
VAL_ 1904 DTCIUnused6_770 1 "true" 0 "false" ;
VAL_ 1904 DTCIUnused5_770 1 "true" 0 "false" ;
VAL_ 1904 DTCIUnused4_770 1 "true" 0 "false" ;
VAL_ 1904 DTCIUnused3_770 1 "true" 0 "false" ;
VAL_ 1904 DTCIUnused2_770 1 "true" 0 "false" ;
VAL_ 1904 DTCIUnused1_770 1 "true" 0 "false" ;
VAL_ 1904 DTCI_TstNPsdPwrUpSt_770 1 "true" 0 "false" ;
VAL_ 1904 DTCI_TstNPsdCdClrdSt_770 1 "true" 0 "false" ;
VAL_ 1904 DTCI_TstFldPwrUpSt_770 1 "true" 0 "false" ;
VAL_ 1904 DTCI_TstFldCdClrdStat_770 1 "true" 0 "false" ;
VAL_ 1904 DTCI_HistStat_770 1 "true" 0 "false" ;
VAL_ 1904 DTCI_DTCTriggered_770 1 "true" 0 "false" ;
VAL_ 1904 DTCI_DTCFaultType_770 3 "Type C" 2 "Type B" 1 "Type A" 0 "Not Supported" ;
VAL_ 1904 DTCI_CurrentStatus_770 1 "true" 0 "false" ;
VAL_ 1904 DTCI_CodeSupported_770 1 "true" 0 "false" ;
VAL_ 1908 DTCI_DTCFaultType_774 3 "Type C" 2 "Type B" 1 "Type A" 0 "Not Supported" ;
VAL_ 1908 DTCI_CodeSupported_774 1 "true" 0 "false" ;
VAL_ 1908 DTCI_CurrentStatus_774 1 "true" 0 "false" ;
VAL_ 1908 DTCI_TstNPsdCdClrdSt_774 1 "true" 0 "false" ;
VAL_ 1908 DTCI_TstFldCdClrdStat_774 1 "true" 0 "false" ;
VAL_ 1908 DTCI_HistStat_774 1 "true" 0 "false" ;
VAL_ 1908 DTCI_TstNPsdPwrUpSt_774 1 "true" 0 "false" ;
VAL_ 1908 DTCI_TstFldPwrUpSt_774 1 "true" 0 "false" ;
VAL_ 1908 DTCI_WrnIndRqdSt_774 1 "true" 0 "false" ;
VAL_ 1908 DTCI_DTCTriggered_774 1 "true" 0 "false" ;
VAL_ 1908 DTCIUnused7_774 1 "true" 0 "false" ;
VAL_ 1908 DTCIUnused6_774 1 "true" 0 "false" ;
VAL_ 1908 DTCIUnused5_774 1 "true" 0 "false" ;
VAL_ 1908 DTCIUnused4_774 1 "true" 0 "false" ;
VAL_ 1908 DTCIUnused3_774 1 "true" 0 "false" ;
VAL_ 1908 DTCIUnused2_774 1 "true" 0 "false" ;
VAL_ 1908 DTCIUnused1_774 1 "true" 0 "false" ;
VAL_ 1909 DTCI_DTCFaultType_775 3 "Type C" 2 "Type B" 1 "Type A" 0 "Not Supported" ;
VAL_ 1909 DTCI_CodeSupported_775 1 "true" 0 "false" ;
VAL_ 1909 DTCI_CurrentStatus_775 1 "true" 0 "false" ;
VAL_ 1909 DTCI_TstNPsdCdClrdSt_775 1 "true" 0 "false" ;
VAL_ 1909 DTCI_TstFldCdClrdStat_775 1 "true" 0 "false" ;
VAL_ 1909 DTCI_HistStat_775 1 "true" 0 "false" ;
VAL_ 1909 DTCI_TstNPsdPwrUpSt_775 1 "true" 0 "false" ;
VAL_ 1909 DTCI_TstFldPwrUpSt_775 1 "true" 0 "false" ;
VAL_ 1909 DTCI_WrnIndRqdSt_775 1 "true" 0 "false" ;
VAL_ 1909 DTCI_DTCTriggered_775 1 "true" 0 "false" ;
VAL_ 1909 DTCIUnused7_775 1 "true" 0 "false" ;
VAL_ 1909 DTCIUnused6_775 1 "true" 0 "false" ;
VAL_ 1909 DTCIUnused5_775 1 "true" 0 "false" ;
VAL_ 1909 DTCIUnused4_775 1 "true" 0 "false" ;
VAL_ 1909 DTCIUnused3_775 1 "true" 0 "false" ;
VAL_ 1909 DTCIUnused2_775 1 "true" 0 "false" ;
VAL_ 1909 DTCIUnused1_775 1 "true" 0 "false" ;
VAL_ 1910 DTCI_DTCFaultType_776 3 "Type C" 2 "Type B" 1 "Type A" 0 "Not Supported" ;
VAL_ 1910 DTCI_CodeSupported_776 1 "true" 0 "false" ;
VAL_ 1910 DTCI_CurrentStatus_776 1 "true" 0 "false" ;
VAL_ 1910 DTCI_TstNPsdCdClrdSt_776 1 "true" 0 "false" ;
VAL_ 1910 DTCI_TstFldCdClrdStat_776 1 "true" 0 "false" ;
VAL_ 1910 DTCI_HistStat_776 1 "true" 0 "false" ;
VAL_ 1910 DTCI_TstNPsdPwrUpSt_776 1 "true" 0 "false" ;
VAL_ 1910 DTCI_TstFldPwrUpSt_776 1 "true" 0 "false" ;
VAL_ 1910 DTCI_WrnIndRqdSt_776 1 "true" 0 "false" ;
VAL_ 1910 DTCI_DTCTriggered_776 1 "true" 0 "false" ;
VAL_ 1910 DTCIUnused7_776 1 "true" 0 "false" ;
VAL_ 1910 DTCIUnused6_776 1 "true" 0 "false" ;
VAL_ 1910 DTCIUnused5_776 1 "true" 0 "false" ;
VAL_ 1910 DTCIUnused4_776 1 "true" 0 "false" ;
VAL_ 1910 DTCIUnused3_776 1 "true" 0 "false" ;
VAL_ 1910 DTCIUnused2_776 1 "true" 0 "false" ;
VAL_ 1910 DTCIUnused1_776 1 "true" 0 "false" ;
VAL_ 1912 DTCI_DTCFaultType_778 3 "Type C" 2 "Type B" 1 "Type A" 0 "Not Supported" ;
VAL_ 1912 DTCI_CodeSupported_778 1 "true" 0 "false" ;
VAL_ 1912 DTCI_CurrentStatus_778 1 "true" 0 "false" ;
VAL_ 1912 DTCI_TstNPsdCdClrdSt_778 1 "true" 0 "false" ;
VAL_ 1912 DTCI_TstFldCdClrdStat_778 1 "true" 0 "false" ;
VAL_ 1912 DTCI_HistStat_778 1 "true" 0 "false" ;
VAL_ 1912 DTCI_TstNPsdPwrUpSt_778 1 "true" 0 "false" ;
VAL_ 1912 DTCI_TstFldPwrUpSt_778 1 "true" 0 "false" ;
VAL_ 1912 DTCI_WrnIndRqdSt_778 1 "true" 0 "false" ;
VAL_ 1912 DTCI_DTCTriggered_778 1 "true" 0 "false" ;
VAL_ 1912 DTCIUnused7_778 1 "true" 0 "false" ;
VAL_ 1912 DTCIUnused6_778 1 "true" 0 "false" ;
VAL_ 1912 DTCIUnused5_778 1 "true" 0 "false" ;
VAL_ 1912 DTCIUnused4_778 1 "true" 0 "false" ;
VAL_ 1912 DTCIUnused3_778 1 "true" 0 "false" ;
VAL_ 1912 DTCIUnused2_778 1 "true" 0 "false" ;
VAL_ 1912 DTCIUnused1_778 1 "true" 0 "false" ;
VAL_ 1913 DTCI_DTCFaultType_779 3 "Type C" 2 "Type B" 1 "Type A" 0 "Not Supported" ;
VAL_ 1913 DTCI_CodeSupported_779 1 "true" 0 "false" ;
VAL_ 1913 DTCI_CurrentStatus_779 1 "true" 0 "false" ;
VAL_ 1913 DTCI_TstNPsdCdClrdSt_779 1 "true" 0 "false" ;
VAL_ 1913 DTCI_TstFldCdClrdStat_779 1 "true" 0 "false" ;
VAL_ 1913 DTCI_HistStat_779 1 "true" 0 "false" ;
VAL_ 1913 DTCI_TstNPsdPwrUpSt_779 1 "true" 0 "false" ;
VAL_ 1913 DTCI_TstFldPwrUpSt_779 1 "true" 0 "false" ;
VAL_ 1913 DTCI_WrnIndRqdSt_779 1 "true" 0 "false" ;
VAL_ 1913 DTCI_DTCTriggered_779 1 "true" 0 "false" ;
VAL_ 1913 DTCIUnused7_779 1 "true" 0 "false" ;
VAL_ 1913 DTCIUnused6_779 1 "true" 0 "false" ;
VAL_ 1913 DTCIUnused5_779 1 "true" 0 "false" ;
VAL_ 1913 DTCIUnused4_779 1 "true" 0 "false" ;
VAL_ 1913 DTCIUnused3_779 1 "true" 0 "false" ;
VAL_ 1913 DTCIUnused2_779 1 "true" 0 "false" ;
VAL_ 1913 DTCIUnused1_779 1 "true" 0 "false" ;
VAL_ 1916 DTCI_DTCFaultType_77C 3 "Type C" 2 "Type B" 1 "Type A" 0 "Not Supported" ;
VAL_ 1916 DTCI_CodeSupported_77C 1 "true" 0 "false" ;
VAL_ 1916 DTCI_CurrentStatus_77C 1 "true" 0 "false" ;
VAL_ 1916 DTCI_TstNPsdCdClrdSt_77C 1 "true" 0 "false" ;
VAL_ 1916 DTCI_TstFldCdClrdStat_77C 1 "true" 0 "false" ;
VAL_ 1916 DTCI_HistStat_77C 1 "true" 0 "false" ;
VAL_ 1916 DTCI_TstNPsdPwrUpSt_77C 1 "true" 0 "false" ;
VAL_ 1916 DTCI_TstFldPwrUpSt_77C 1 "true" 0 "false" ;
VAL_ 1916 DTCI_WrnIndRqdSt_77C 1 "true" 0 "false" ;
VAL_ 1916 DTCI_DTCTriggered_77C 1 "true" 0 "false" ;
VAL_ 1916 DTCIUnused7_77C 1 "true" 0 "false" ;
VAL_ 1916 DTCIUnused6_77C 1 "true" 0 "false" ;
VAL_ 1916 DTCIUnused5_77C 1 "true" 0 "false" ;
VAL_ 1916 DTCIUnused4_77C 1 "true" 0 "false" ;
VAL_ 1916 DTCIUnused3_77C 1 "true" 0 "false" ;
VAL_ 1916 DTCIUnused2_77C 1 "true" 0 "false" ;
VAL_ 1916 DTCIUnused1_77C 1 "true" 0 "false" ;
VAL_ 1917 DTCI_DTCFaultType_77D 3 "Type C" 2 "Type B" 1 "Type A" 0 "Not Supported" ;
VAL_ 1917 DTCI_CodeSupported_77D 1 "true" 0 "false" ;
VAL_ 1917 DTCI_CurrentStatus_77D 1 "true" 0 "false" ;
VAL_ 1917 DTCI_TstNPsdCdClrdSt_77D 1 "true" 0 "false" ;
VAL_ 1917 DTCI_TstFldCdClrdStat_77D 1 "true" 0 "false" ;
VAL_ 1917 DTCI_HistStat_77D 1 "true" 0 "false" ;
VAL_ 1917 DTCI_TstNPsdPwrUpSt_77D 1 "true" 0 "false" ;
VAL_ 1917 DTCI_TstFldPwrUpSt_77D 1 "true" 0 "false" ;
VAL_ 1917 DTCI_WrnIndRqdSt_77D 1 "true" 0 "false" ;
VAL_ 1917 DTCI_DTCTriggered_77D 1 "true" 0 "false" ;
VAL_ 1917 DTCIUnused7_77D 1 "true" 0 "false" ;
VAL_ 1917 DTCIUnused6_77D 1 "true" 0 "false" ;
VAL_ 1917 DTCIUnused5_77D 1 "true" 0 "false" ;
VAL_ 1917 DTCIUnused4_77D 1 "true" 0 "false" ;
VAL_ 1917 DTCIUnused3_77D 1 "true" 0 "false" ;
VAL_ 1917 DTCIUnused2_77D 1 "true" 0 "false" ;
VAL_ 1917 DTCIUnused1_77D 1 "true" 0 "false" ;
VAL_ 1918 DTCI_DTCFaultType_77E 3 "Type C" 2 "Type B" 1 "Type A" 0 "Not Supported" ;
VAL_ 1918 DTCI_CodeSupported_77E 1 "true" 0 "false" ;
VAL_ 1918 DTCI_CurrentStatus_77E 1 "true" 0 "false" ;
VAL_ 1918 DTCI_TstNPsdCdClrdSt_77E 1 "true" 0 "false" ;
VAL_ 1918 DTCI_TstFldCdClrdStat_77E 1 "true" 0 "false" ;
VAL_ 1918 DTCI_HistStat_77E 1 "true" 0 "false" ;
VAL_ 1918 DTCI_TstNPsdPwrUpSt_77E 1 "true" 0 "false" ;
VAL_ 1918 DTCI_TstFldPwrUpSt_77E 1 "true" 0 "false" ;
VAL_ 1918 DTCI_WrnIndRqdSt_77E 1 "true" 0 "false" ;
VAL_ 1918 DTCI_DTCTriggered_77E 1 "true" 0 "false" ;
VAL_ 1918 DTCIUnused7_77E 1 "true" 0 "false" ;
VAL_ 1918 DTCIUnused6_77E 1 "true" 0 "false" ;
VAL_ 1918 DTCIUnused5_77E 1 "true" 0 "false" ;
VAL_ 1918 DTCIUnused4_77E 1 "true" 0 "false" ;
VAL_ 1918 DTCIUnused3_77E 1 "true" 0 "false" ;
VAL_ 1918 DTCIUnused2_77E 1 "true" 0 "false" ;
VAL_ 1918 DTCIUnused1_77E 1 "true" 0 "false" ;
VAL_ 1919 DTCI_DTCFaultType_77F 3 "Type C" 2 "Type B" 1 "Type A" 0 "Not Supported" ;
VAL_ 1919 DTCI_CodeSupported_77F 1 "true" 0 "false" ;
VAL_ 1919 DTCI_CurrentStatus_77F 1 "true" 0 "false" ;
VAL_ 1919 DTCI_TstNPsdCdClrdSt_77F 1 "true" 0 "false" ;
VAL_ 1919 DTCI_TstFldCdClrdStat_77F 1 "true" 0 "false" ;
VAL_ 1919 DTCI_HistStat_77F 1 "true" 0 "false" ;
VAL_ 1919 DTCI_TstNPsdPwrUpSt_77F 1 "true" 0 "false" ;
VAL_ 1919 DTCI_TstFldPwrUpSt_77F 1 "true" 0 "false" ;
VAL_ 1919 DTCI_WrnIndRqdSt_77F 1 "true" 0 "false" ;
VAL_ 1919 DTCI_DTCTriggered_77F 1 "true" 0 "false" ;
VAL_ 1919 DTCIUnused7_77F 1 "true" 0 "false" ;
VAL_ 1919 DTCIUnused6_77F 1 "true" 0 "false" ;
VAL_ 1919 DTCIUnused5_77F 1 "true" 0 "false" ;
VAL_ 1919 DTCIUnused4_77F 1 "true" 0 "false" ;
VAL_ 1919 DTCIUnused3_77F 1 "true" 0 "false" ;
VAL_ 1919 DTCIUnused2_77F 1 "true" 0 "false" ;
VAL_ 1919 DTCIUnused1_77F 1 "true" 0 "false" ;
VAL_ 499 PTShftPtrnOvrdAct 1 "true" 0 "false" ;
VAL_ 499 PFTrnsTUDSecSwSt 3 "Illegal Up/Down Switch State Active" 2 "Decrement Switch Active" 1 "Increment Switch Active" 0 "No Activation" ;
VAL_ 499 TrnsPFShftPattSw4Act 1 "true" 0 "false" ;
VAL_ 499 TrnsPFShftPattSw3Act 1 "true" 0 "false" ;
VAL_ 499 TrnsPFShftPattSw2Act 1 "true" 0 "false" ;
VAL_ 499 TrnsPFShftPattSw1Act 1 "true" 0 "false" ;
VAL_ 499 PFTrnsTUDSwSt 3 "Illegal Up/Down Switch State Active" 2 "Decrement Switch Active" 1 "Increment Switch Active" 0 "No Activation" ;
VAL_ 499 PFTrnsTUDEnSwSt 3 "Illegal Enable Switch State" 2 "Electronic Range Select Enable Sw" 1 "Driver Shift Control Enable Switch" 0 "No Activation" ;
VAL_ 499 OvrdrvDsblReqd 1 "true" 0 "false" ;
VAL_ 1282 TireTrdTmpStat 0 "No Action (unknown)" 1 "Frozen" 2 "Cold" 3 "Warm" 4 "Hot" 5 "Overheated" ;
VAL_ 1282 AllNodesVNA_502 1 "Activate Virtual Network" 0 "No Activation" ;
VAL_ 1282 A3ERRAlrmReq 0 "No Action" 1 "Set Alarm" 2 "Cancel Alarm" ;
VAL_ 1921 DTCI_CurrentStatus_781 1 "true" 0 "false" ;
VAL_ 1921 DTCI_WrnIndRqdSt_781 1 "true" 0 "false" ;
VAL_ 1921 DTCIUnused7_781 1 "true" 0 "false" ;
VAL_ 1921 DTCIUnused6_781 1 "true" 0 "false" ;
VAL_ 1921 DTCIUnused5_781 1 "true" 0 "false" ;
VAL_ 1921 DTCIUnused4_781 1 "true" 0 "false" ;
VAL_ 1921 DTCIUnused3_781 1 "true" 0 "false" ;
VAL_ 1921 DTCIUnused2_781 1 "true" 0 "false" ;
VAL_ 1921 DTCIUnused1_781 1 "true" 0 "false" ;
VAL_ 1921 DTCI_TstNPsdPwrUpSt_781 1 "true" 0 "false" ;
VAL_ 1921 DTCI_TstNPsdCdClrdSt_781 1 "true" 0 "false" ;
VAL_ 1921 DTCI_TstFldPwrUpSt_781 1 "true" 0 "false" ;
VAL_ 1921 DTCI_TstFldCdClrdStat_781 1 "true" 0 "false" ;
VAL_ 1921 DTCI_HistStat_781 1 "true" 0 "false" ;
VAL_ 1921 DTCI_DTCTriggered_781 1 "true" 0 "false" ;
VAL_ 1921 DTCI_DTCFaultType_781 3 "Type C" 2 "Type B" 1 "Type A" 0 "Not Supported" ;
VAL_ 1921 DTCI_CodeSupported_781 1 "true" 0 "false" ;
VAL_ 1920 DTCI_CurrentStatus_780 1 "true" 0 "false" ;
VAL_ 1920 DTCI_WrnIndRqdSt_780 1 "true" 0 "false" ;
VAL_ 1920 DTCIUnused7_780 1 "true" 0 "false" ;
VAL_ 1920 DTCIUnused6_780 1 "true" 0 "false" ;
VAL_ 1920 DTCIUnused5_780 1 "true" 0 "false" ;
VAL_ 1920 DTCIUnused4_780 1 "true" 0 "false" ;
VAL_ 1920 DTCIUnused3_780 1 "true" 0 "false" ;
VAL_ 1920 DTCIUnused2_780 1 "true" 0 "false" ;
VAL_ 1920 DTCIUnused1_780 1 "true" 0 "false" ;
VAL_ 1920 DTCI_TstNPsdPwrUpSt_780 1 "true" 0 "false" ;
VAL_ 1920 DTCI_TstNPsdCdClrdSt_780 1 "true" 0 "false" ;
VAL_ 1920 DTCI_TstFldPwrUpSt_780 1 "true" 0 "false" ;
VAL_ 1920 DTCI_TstFldCdClrdStat_780 1 "true" 0 "false" ;
VAL_ 1920 DTCI_HistStat_780 1 "true" 0 "false" ;
VAL_ 1920 DTCI_DTCTriggered_780 1 "true" 0 "false" ;
VAL_ 1920 DTCI_DTCFaultType_780 3 "Type C" 2 "Type B" 1 "Type A" 0 "Not Supported" ;
VAL_ 1920 DTCI_CodeSupported_780 1 "true" 0 "false" ;
VAL_ 495 MassAirFloV 1 "Invalid" 0 "Valid" ;
VAL_ 1914 DTCI_DTCFaultType_77A 3 "Type C" 2 "Type B" 1 "Type A" 0 "Not Supported" ;
VAL_ 1914 DTCI_CodeSupported_77A 1 "true" 0 "false" ;
VAL_ 1914 DTCI_CurrentStatus_77A 1 "true" 0 "false" ;
VAL_ 1914 DTCI_TstNPsdCdClrdSt_77A 1 "true" 0 "false" ;
VAL_ 1914 DTCI_TstFldCdClrdStat_77A 1 "true" 0 "false" ;
VAL_ 1914 DTCI_HistStat_77A 1 "true" 0 "false" ;
VAL_ 1914 DTCI_TstNPsdPwrUpSt_77A 1 "true" 0 "false" ;
VAL_ 1914 DTCI_TstFldPwrUpSt_77A 1 "true" 0 "false" ;
VAL_ 1914 DTCI_WrnIndRqdSt_77A 1 "true" 0 "false" ;
VAL_ 1914 DTCI_DTCTriggered_77A 1 "true" 0 "false" ;
VAL_ 1914 DTCIUnused7_77A 1 "true" 0 "false" ;
VAL_ 1914 DTCIUnused6_77A 1 "true" 0 "false" ;
VAL_ 1914 DTCIUnused5_77A 1 "true" 0 "false" ;
VAL_ 1914 DTCIUnused4_77A 1 "true" 0 "false" ;
VAL_ 1914 DTCIUnused3_77A 1 "true" 0 "false" ;
VAL_ 1914 DTCIUnused2_77A 1 "true" 0 "false" ;
VAL_ 1914 DTCIUnused1_77A 1 "true" 0 "false" ;
VAL_ 1911 DTCI_DTCFaultType_777 3 "Type C" 2 "Type B" 1 "Type A" 0 "Not Supported" ;
VAL_ 1911 DTCI_CodeSupported_777 1 "true" 0 "false" ;
VAL_ 1911 DTCI_CurrentStatus_777 1 "true" 0 "false" ;
VAL_ 1911 DTCI_TstNPsdCdClrdSt_777 1 "true" 0 "false" ;
VAL_ 1911 DTCI_TstFldCdClrdStat_777 1 "true" 0 "false" ;
VAL_ 1911 DTCI_HistStat_777 1 "true" 0 "false" ;
VAL_ 1911 DTCI_TstNPsdPwrUpSt_777 1 "true" 0 "false" ;
VAL_ 1911 DTCI_TstFldPwrUpSt_777 1 "true" 0 "false" ;
VAL_ 1911 DTCI_WrnIndRqdSt_777 1 "true" 0 "false" ;
VAL_ 1911 DTCI_DTCTriggered_777 1 "true" 0 "false" ;
VAL_ 1911 DTCIUnused7_777 1 "true" 0 "false" ;
VAL_ 1911 DTCIUnused6_777 1 "true" 0 "false" ;
VAL_ 1911 DTCIUnused5_777 1 "true" 0 "false" ;
VAL_ 1911 DTCIUnused4_777 1 "true" 0 "false" ;
VAL_ 1911 DTCIUnused3_777 1 "true" 0 "false" ;
VAL_ 1911 DTCIUnused2_777 1 "true" 0 "false" ;
VAL_ 1911 DTCIUnused1_777 1 "true" 0 "false" ;
VAL_ 1906 DTCI_DTCFaultType_772 3 "Type C" 2 "Type B" 1 "Type A" 0 "Not Supported" ;
VAL_ 1906 DTCI_CodeSupported_772 1 "true" 0 "false" ;
VAL_ 1906 DTCI_CurrentStatus_772 1 "true" 0 "false" ;
VAL_ 1906 DTCI_TstNPsdCdClrdSt_772 1 "true" 0 "false" ;
VAL_ 1906 DTCI_TstFldCdClrdStat_772 1 "true" 0 "false" ;
VAL_ 1906 DTCI_HistStat_772 1 "true" 0 "false" ;
VAL_ 1906 DTCI_TstNPsdPwrUpSt_772 1 "true" 0 "false" ;
VAL_ 1906 DTCI_TstFldPwrUpSt_772 1 "true" 0 "false" ;
VAL_ 1906 DTCI_WrnIndRqdSt_772 1 "true" 0 "false" ;
VAL_ 1906 DTCI_DTCTriggered_772 1 "true" 0 "false" ;
VAL_ 1906 DTCIUnused7_772 1 "true" 0 "false" ;
VAL_ 1906 DTCIUnused6_772 1 "true" 0 "false" ;
VAL_ 1906 DTCIUnused5_772 1 "true" 0 "false" ;
VAL_ 1906 DTCIUnused4_772 1 "true" 0 "false" ;
VAL_ 1906 DTCIUnused3_772 1 "true" 0 "false" ;
VAL_ 1906 DTCIUnused2_772 1 "true" 0 "false" ;
VAL_ 1906 DTCIUnused1_772 1 "true" 0 "false" ;
VAL_ 1907 DTCI_DTCFaultType_773 3 "Type C" 2 "Type B" 1 "Type A" 0 "Not Supported" ;
VAL_ 1907 DTCI_CodeSupported_773 1 "true" 0 "false" ;
VAL_ 1907 DTCI_CurrentStatus_773 1 "true" 0 "false" ;
VAL_ 1907 DTCI_TstNPsdCdClrdSt_773 1 "true" 0 "false" ;
VAL_ 1907 DTCI_TstFldCdClrdStat_773 1 "true" 0 "false" ;
VAL_ 1907 DTCI_HistStat_773 1 "true" 0 "false" ;
VAL_ 1907 DTCI_TstNPsdPwrUpSt_773 1 "true" 0 "false" ;
VAL_ 1907 DTCI_TstFldPwrUpSt_773 1 "true" 0 "false" ;
VAL_ 1907 DTCI_WrnIndRqdSt_773 1 "true" 0 "false" ;
VAL_ 1907 DTCI_DTCTriggered_773 1 "true" 0 "false" ;
VAL_ 1907 DTCIUnused7_773 1 "true" 0 "false" ;
VAL_ 1907 DTCIUnused6_773 1 "true" 0 "false" ;
VAL_ 1907 DTCIUnused5_773 1 "true" 0 "false" ;
VAL_ 1907 DTCIUnused4_773 1 "true" 0 "false" ;
VAL_ 1907 DTCIUnused3_773 1 "true" 0 "false" ;
VAL_ 1907 DTCIUnused2_773 1 "true" 0 "false" ;
VAL_ 1907 DTCIUnused1_773 1 "true" 0 "false" ;
VAL_ 1915 DTCI_DTCFaultType_77B 3 "Type C" 2 "Type B" 1 "Type A" 0 "Not Supported" ;
VAL_ 1915 DTCI_CodeSupported_77B 1 "true" 0 "false" ;
VAL_ 1915 DTCI_CurrentStatus_77B 1 "true" 0 "false" ;
VAL_ 1915 DTCI_TstNPsdCdClrdSt_77B 1 "true" 0 "false" ;
VAL_ 1915 DTCI_TstFldCdClrdStat_77B 1 "true" 0 "false" ;
VAL_ 1915 DTCI_HistStat_77B 1 "true" 0 "false" ;
VAL_ 1915 DTCI_TstNPsdPwrUpSt_77B 1 "true" 0 "false" ;
VAL_ 1915 DTCI_TstFldPwrUpSt_77B 1 "true" 0 "false" ;
VAL_ 1915 DTCI_WrnIndRqdSt_77B 1 "true" 0 "false" ;
VAL_ 1915 DTCI_DTCTriggered_77B 1 "true" 0 "false" ;
VAL_ 1915 DTCIUnused7_77B 1 "true" 0 "false" ;
VAL_ 1915 DTCIUnused6_77B 1 "true" 0 "false" ;
VAL_ 1915 DTCIUnused5_77B 1 "true" 0 "false" ;
VAL_ 1915 DTCIUnused4_77B 1 "true" 0 "false" ;
VAL_ 1915 DTCIUnused3_77B 1 "true" 0 "false" ;
VAL_ 1915 DTCIUnused2_77B 1 "true" 0 "false" ;
VAL_ 1915 DTCIUnused1_77B 1 "true" 0 "false" ;
SIG_GROUP_ 1904 DTCInfo_770 1 : DTCI_WrnIndRqdSt_770 DTCIUnused7_770 DTCIUnused6_770 DTCIUnused5_770 DTCIUnused4_770 DTCIUnused3_770 DTCIUnused2_770 DTCIUnused1_770 DTCI_TstNPsdPwrUpSt_770 DTCI_TstNPsdCdClrdSt_770 DTCI_TstFldPwrUpSt_770 DTCI_TstFldCdClrdStat_770 DTCI_HistStat_770 DTCI_DTCTriggered_770 DTCI_DTCSource_770 DTCI_DTCNumber_770 DTCI_DTCFaultType_770 DTCI_DTCFailType_770 DTCI_CurrentStatus_770 DTCI_CodeSupported_770;
SIG_GROUP_ 1908 DTCInfo_774 1 : DTCI_DTCFaultType_774 DTCI_CodeSupported_774 DTCI_CurrentStatus_774 DTCI_TstNPsdCdClrdSt_774 DTCI_TstFldCdClrdStat_774 DTCI_HistStat_774 DTCI_TstNPsdPwrUpSt_774 DTCI_TstFldPwrUpSt_774 DTCI_WrnIndRqdSt_774 DTCI_DTCFailType_774 DTCI_DTCNumber_774 DTCI_DTCSource_774 DTCI_DTCTriggered_774 DTCIUnused7_774 DTCIUnused6_774 DTCIUnused5_774 DTCIUnused4_774 DTCIUnused3_774 DTCIUnused2_774 DTCIUnused1_774;
SIG_GROUP_ 1909 DTCInfo_775 1 : DTCI_DTCFaultType_775 DTCI_CodeSupported_775 DTCI_CurrentStatus_775 DTCI_TstNPsdCdClrdSt_775 DTCI_TstFldCdClrdStat_775 DTCI_HistStat_775 DTCI_TstNPsdPwrUpSt_775 DTCI_TstFldPwrUpSt_775 DTCI_WrnIndRqdSt_775 DTCI_DTCFailType_775 DTCI_DTCNumber_775 DTCI_DTCSource_775 DTCI_DTCTriggered_775 DTCIUnused7_775 DTCIUnused6_775 DTCIUnused5_775 DTCIUnused4_775 DTCIUnused3_775 DTCIUnused2_775 DTCIUnused1_775;
SIG_GROUP_ 1910 DTCInfo_776 1 : DTCI_DTCFaultType_776 DTCI_CodeSupported_776 DTCI_CurrentStatus_776 DTCI_TstNPsdCdClrdSt_776 DTCI_TstFldCdClrdStat_776 DTCI_HistStat_776 DTCI_TstNPsdPwrUpSt_776 DTCI_TstFldPwrUpSt_776 DTCI_WrnIndRqdSt_776 DTCI_DTCFailType_776 DTCI_DTCNumber_776 DTCI_DTCSource_776 DTCI_DTCTriggered_776 DTCIUnused7_776 DTCIUnused6_776 DTCIUnused5_776 DTCIUnused4_776 DTCIUnused3_776 DTCIUnused2_776 DTCIUnused1_776;
SIG_GROUP_ 1912 DTCInfo_778 1 : DTCI_DTCFaultType_778 DTCI_CodeSupported_778 DTCI_CurrentStatus_778 DTCI_TstNPsdCdClrdSt_778 DTCI_TstFldCdClrdStat_778 DTCI_HistStat_778 DTCI_TstNPsdPwrUpSt_778 DTCI_TstFldPwrUpSt_778 DTCI_WrnIndRqdSt_778 DTCI_DTCFailType_778 DTCI_DTCNumber_778 DTCI_DTCSource_778 DTCI_DTCTriggered_778 DTCIUnused7_778 DTCIUnused6_778 DTCIUnused5_778 DTCIUnused4_778 DTCIUnused3_778 DTCIUnused2_778 DTCIUnused1_778;
SIG_GROUP_ 1913 DTCInfo_779 1 : DTCI_DTCFaultType_779 DTCI_CodeSupported_779 DTCI_CurrentStatus_779 DTCI_TstNPsdCdClrdSt_779 DTCI_TstFldCdClrdStat_779 DTCI_HistStat_779 DTCI_TstNPsdPwrUpSt_779 DTCI_TstFldPwrUpSt_779 DTCI_WrnIndRqdSt_779 DTCI_DTCFailType_779 DTCI_DTCNumber_779 DTCI_DTCSource_779 DTCI_DTCTriggered_779 DTCIUnused7_779 DTCIUnused6_779 DTCIUnused5_779 DTCIUnused4_779 DTCIUnused3_779 DTCIUnused2_779 DTCIUnused1_779;
SIG_GROUP_ 1916 DTCInfo_77C 1 : DTCI_DTCFaultType_77C DTCI_CodeSupported_77C DTCI_CurrentStatus_77C DTCI_TstNPsdCdClrdSt_77C DTCI_TstFldCdClrdStat_77C DTCI_HistStat_77C DTCI_TstNPsdPwrUpSt_77C DTCI_TstFldPwrUpSt_77C DTCI_WrnIndRqdSt_77C DTCI_DTCFailType_77C DTCI_DTCNumber_77C DTCI_DTCSource_77C DTCI_DTCTriggered_77C DTCIUnused7_77C DTCIUnused6_77C DTCIUnused5_77C DTCIUnused4_77C DTCIUnused3_77C DTCIUnused2_77C DTCIUnused1_77C;
SIG_GROUP_ 1917 DTCInfo_77D 1 : DTCI_DTCFaultType_77D DTCI_CodeSupported_77D DTCI_CurrentStatus_77D DTCI_TstNPsdCdClrdSt_77D DTCI_TstFldCdClrdStat_77D DTCI_HistStat_77D DTCI_TstNPsdPwrUpSt_77D DTCI_TstFldPwrUpSt_77D DTCI_WrnIndRqdSt_77D DTCI_DTCFailType_77D DTCI_DTCNumber_77D DTCI_DTCSource_77D DTCI_DTCTriggered_77D DTCIUnused7_77D DTCIUnused6_77D DTCIUnused5_77D DTCIUnused4_77D DTCIUnused3_77D DTCIUnused2_77D DTCIUnused1_77D;
SIG_GROUP_ 1918 DTCInfo_77E 1 : DTCI_DTCFaultType_77E DTCI_CodeSupported_77E DTCI_CurrentStatus_77E DTCI_TstNPsdCdClrdSt_77E DTCI_TstFldCdClrdStat_77E DTCI_HistStat_77E DTCI_TstNPsdPwrUpSt_77E DTCI_TstFldPwrUpSt_77E DTCI_WrnIndRqdSt_77E DTCI_DTCFailType_77E DTCI_DTCNumber_77E DTCI_DTCSource_77E DTCI_DTCTriggered_77E DTCIUnused7_77E DTCIUnused6_77E DTCIUnused5_77E DTCIUnused4_77E DTCIUnused3_77E DTCIUnused2_77E DTCIUnused1_77E;
SIG_GROUP_ 1919 DTCInfo_77F 1 : DTCI_DTCFaultType_77F DTCI_CodeSupported_77F DTCI_CurrentStatus_77F DTCI_TstNPsdCdClrdSt_77F DTCI_TstFldCdClrdStat_77F DTCI_HistStat_77F DTCI_TstNPsdPwrUpSt_77F DTCI_TstFldPwrUpSt_77F DTCI_WrnIndRqdSt_77F DTCI_DTCFailType_77F DTCI_DTCNumber_77F DTCI_DTCSource_77F DTCI_DTCTriggered_77F DTCIUnused7_77F DTCIUnused6_77F DTCIUnused5_77F DTCIUnused4_77F DTCIUnused3_77F DTCIUnused2_77F DTCIUnused1_77F;
SIG_GROUP_ 1282 Alrm3ExtRngReq 1 : A3ERRAlrmTime A3ERRAlrmReq;
SIG_GROUP_ 1921 DTCInfo_781 1 : DTCI_CurrentStatus_781 DTCI_WrnIndRqdSt_781 DTCIUnused7_781 DTCIUnused6_781 DTCIUnused5_781 DTCIUnused4_781 DTCIUnused3_781 DTCIUnused2_781 DTCIUnused1_781 DTCI_TstNPsdPwrUpSt_781 DTCI_TstNPsdCdClrdSt_781 DTCI_TstFldPwrUpSt_781 DTCI_TstFldCdClrdStat_781 DTCI_HistStat_781 DTCI_DTCTriggered_781 DTCI_DTCSource_781 DTCI_DTCNumber_781 DTCI_DTCFaultType_781 DTCI_DTCFailType_781 DTCI_CodeSupported_781;
SIG_GROUP_ 1920 DTCInfo_780 1 : DTCI_CurrentStatus_780 DTCI_WrnIndRqdSt_780 DTCIUnused7_780 DTCIUnused6_780 DTCIUnused5_780 DTCIUnused4_780 DTCIUnused3_780 DTCIUnused2_780 DTCIUnused1_780 DTCI_TstNPsdPwrUpSt_780 DTCI_TstNPsdCdClrdSt_780 DTCI_TstFldPwrUpSt_780 DTCI_TstFldCdClrdStat_780 DTCI_HistStat_780 DTCI_DTCTriggered_780 DTCI_DTCSource_780 DTCI_DTCNumber_780 DTCI_DTCFaultType_780 DTCI_DTCFailType_780 DTCI_CodeSupported_780;
SIG_GROUP_ 1914 DTCInfo_77A 1 : DTCI_DTCFaultType_77A DTCI_CodeSupported_77A DTCI_CurrentStatus_77A DTCI_TstNPsdCdClrdSt_77A DTCI_TstFldCdClrdStat_77A DTCI_HistStat_77A DTCI_TstNPsdPwrUpSt_77A DTCI_TstFldPwrUpSt_77A DTCI_WrnIndRqdSt_77A DTCI_DTCFailType_77A DTCI_DTCNumber_77A DTCI_DTCSource_77A DTCI_DTCTriggered_77A DTCIUnused7_77A DTCIUnused6_77A DTCIUnused5_77A DTCIUnused4_77A DTCIUnused3_77A DTCIUnused2_77A DTCIUnused1_77A;
SIG_GROUP_ 1911 DTCInfo_777 1 : DTCI_DTCFaultType_777 DTCI_CodeSupported_777 DTCI_CurrentStatus_777 DTCI_TstNPsdCdClrdSt_777 DTCI_TstFldCdClrdStat_777 DTCI_HistStat_777 DTCI_TstNPsdPwrUpSt_777 DTCI_TstFldPwrUpSt_777 DTCI_WrnIndRqdSt_777 DTCI_DTCFailType_777 DTCI_DTCNumber_777 DTCI_DTCSource_777 DTCI_DTCTriggered_777 DTCIUnused7_777 DTCIUnused6_777 DTCIUnused5_777 DTCIUnused4_777 DTCIUnused3_777 DTCIUnused2_777 DTCIUnused1_777;
SIG_GROUP_ 1906 DTCInfo_772 1 : DTCI_DTCFaultType_772 DTCI_CodeSupported_772 DTCI_CurrentStatus_772 DTCI_TstNPsdCdClrdSt_772 DTCI_TstFldCdClrdStat_772 DTCI_HistStat_772 DTCI_TstNPsdPwrUpSt_772 DTCI_TstFldPwrUpSt_772 DTCI_WrnIndRqdSt_772 DTCI_DTCFailType_772 DTCI_DTCNumber_772 DTCI_DTCSource_772 DTCI_DTCTriggered_772 DTCIUnused7_772 DTCIUnused6_772 DTCIUnused5_772 DTCIUnused4_772 DTCIUnused3_772 DTCIUnused2_772 DTCIUnused1_772;
SIG_GROUP_ 1907 DTCInfo_773 1 : DTCI_DTCFaultType_773 DTCI_CodeSupported_773 DTCI_CurrentStatus_773 DTCI_TstNPsdCdClrdSt_773 DTCI_TstFldCdClrdStat_773 DTCI_HistStat_773 DTCI_TstNPsdPwrUpSt_773 DTCI_TstFldPwrUpSt_773 DTCI_WrnIndRqdSt_773 DTCI_DTCFailType_773 DTCI_DTCNumber_773 DTCI_DTCSource_773 DTCI_DTCTriggered_773 DTCIUnused7_773 DTCIUnused6_773 DTCIUnused5_773 DTCIUnused4_773 DTCIUnused3_773 DTCIUnused2_773 DTCIUnused1_773;
SIG_GROUP_ 1915 DTCInfo_77B 1 : DTCI_DTCFaultType_77B DTCI_CodeSupported_77B DTCI_CurrentStatus_77B DTCI_TstNPsdCdClrdSt_77B DTCI_TstFldCdClrdStat_77B DTCI_HistStat_77B DTCI_TstNPsdPwrUpSt_77B DTCI_TstFldPwrUpSt_77B DTCI_WrnIndRqdSt_77B DTCI_DTCFailType_77B DTCI_DTCNumber_77B DTCI_DTCSource_77B DTCI_DTCTriggered_77B DTCIUnused7_77B DTCIUnused6_77B DTCIUnused5_77B DTCIUnused4_77B DTCIUnused3_77B DTCIUnused2_77B DTCIUnused1_77B;
